VERSION ""

NS_ :

BS_:

BU_: GFM2_BCCMB ACCMB GFM3_DCACB FHCM SOBDMB_AWDC DCACA_GAS DCACA_HEV DCDC_LISB BCMC_CPDB DCMR_EAWD DCMR_ELSD BECMB_EPM PACM GFM_CPLR OBCC AFCM SOBDM_BCCM GWM _delete BCM ACCM GFM2_UIM ICM DCDC_HEV BECM SOBDMD_AHCM_PTC GENERIC TSTR

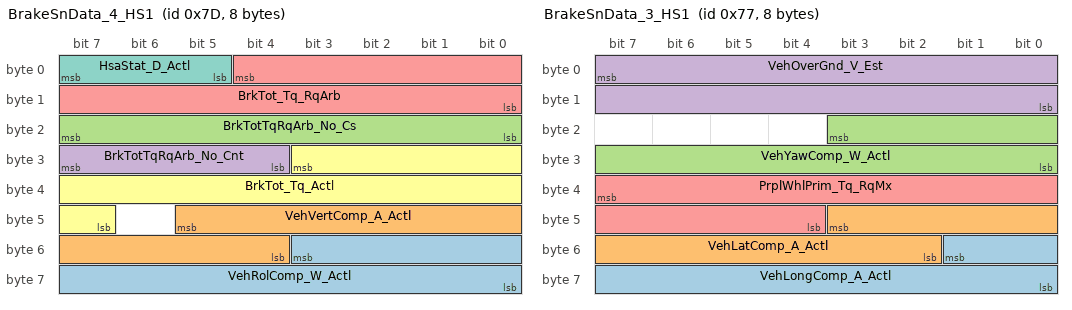
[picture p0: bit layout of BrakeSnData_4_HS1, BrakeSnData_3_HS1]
BO_ 125 BrakeSnData_4_HS1: 8 GWM
 SG_ VehRolComp_W_Actl : 51|12@0+ (0.03663,-75) [-75|74.92659] "degrees/sec"  GFM2_UIM
 SG_ VehVertComp_A_Actl : 45|10@0+ (0.035,-17.9) [-17.9|17.835] "m/s^2"  GFM2_UIM
 SG_ BrkTotTqRqArb_No_Cs : 23|8@0+ (1,0) [0|255] "Unitless"  BCMC_CPDB
 SG_ BrkTotTqRqArb_No_Cnt : 31|4@0+ (1,0) [0|15] "Unitless"  BCMC_CPDB
 SG_ BrkTot_Tq_RqArb : 4|13@0+ (4,0) [0|32756] "Nm"  BCMC_CPDB
 SG_ BrkTot_Tq_Actl : 27|13@0+ (4,0) [0|32756] "Nm"  GENERIC
 SG_ HsaStat_D_Actl : 7|3@0+ (1,0) [0|7] "SED"  GENERIC

BO_ 119 BrakeSnData_3_HS1: 8 GWM
 SG_ VehLongComp_A_Actl : 49|10@0+ (0.035,-17.9) [-17.9|17.835] "m/s^2"  AFCM,GFM2_UIM
 SG_ VehLatComp_A_Actl : 43|10@0+ (0.035,-17.9) [-17.9|17.835] "m/s^2"  AFCM,GFM2_UIM
 SG_ VehYawComp_W_Actl : 19|12@0+ (0.03663,-75) [-75|74.92659] "deg/s"  GFM2_UIM
 SG_ VehOverGnd_V_Est : 7|16@0+ (0.01,0) [0|655.33] "kph"  DCMR_ELSD
 SG_ PrplWhlPrim_Tq_RqMx : 39|12@0+ (8,0) [0|32760] "Nm"  GENERIC

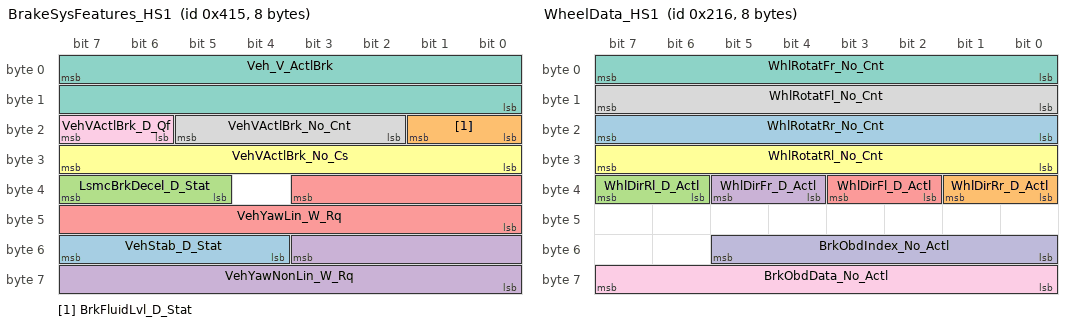
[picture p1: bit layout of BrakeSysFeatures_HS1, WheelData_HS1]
BO_ 1045 BrakeSysFeatures_HS1: 8 GWM
 SG_ VehStab_D_Stat : 55|4@0+ (1,0) [0|15] "SED" Vector__XXX
 SG_ BrkFluidLvl_D_Stat : 17|2@0+ (1,0) [0|3] "SED"  BCM
 SG_ LsmcBrkDecel_D_Stat : 39|3@0+ (1,0) [0|7] "SED"  GENERIC
 SG_ VehYawNonLin_W_Rq : 51|12@0+ (0.03663,-75) [-75|74.92659] "deg/s" Vector__XXX
 SG_ VehYawLin_W_Rq : 35|12@0+ (0.03663,-75) [-75|74.92659] "deg/s" Vector__XXX
 SG_ VehVActlBrk_No_Cs : 31|8@0+ (1,0) [0|255] "Unitless"  FHCM,SOBDMB_AWDC,DCMR_EAWD,BCM
 SG_ Veh_V_ActlBrk : 7|16@0+ (0.01,0) [0|655.35] "kph"  FHCM,SOBDMB_AWDC,DCMR_EAWD,BCM
 SG_ VehVActlBrk_No_Cnt : 21|4@0+ (1,0) [0|15] "Unitless"  FHCM,SOBDMB_AWDC,DCMR_EAWD,BCM
 SG_ VehVActlBrk_D_Qf : 23|2@0+ (1,0) [0|3] "SED"  FHCM,SOBDMB_AWDC,DCMR_EAWD,DCMR_ELSD,BCM

BO_ 534 WheelData_HS1: 8 GWM
 SG_ WhlRotatRr_No_Cnt : 23|8@0+ (1,0) [0|255] "Unitless"  BCM
 SG_ WhlDirRr_D_Actl : 33|2@0+ (1,0) [0|3] "SED" Vector__XXX
 SG_ WhlDirRl_D_Actl : 39|2@0+ (1,0) [0|3] "SED" Vector__XXX
 SG_ WhlDirFr_D_Actl : 37|2@0+ (1,0) [0|3] "SED" Vector__XXX
 SG_ WhlDirFl_D_Actl : 35|2@0+ (1,0) [0|3] "SED" Vector__XXX
 SG_ WhlRotatRl_No_Cnt : 31|8@0+ (1,0) [0|255] "Unitless"  BCM
 SG_ WhlRotatFr_No_Cnt : 7|8@0+ (1,0) [0|255] "Unitless"  BCM
 SG_ WhlRotatFl_No_Cnt : 15|8@0+ (1,0) [0|255] "Unitless"  BCM
 SG_ BrkObdData_No_Actl : 63|8@0+ (1,0) [0|255] "unitless" Vector__XXX
 SG_ BrkObdIndex_No_Actl : 53|6@0+ (1,0) [0|63] "unitless" Vector__XXX

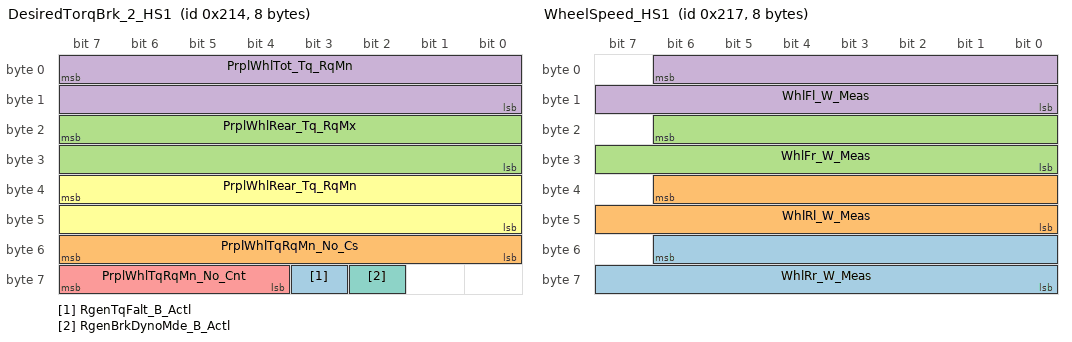
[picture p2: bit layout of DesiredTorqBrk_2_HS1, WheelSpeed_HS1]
BO_ 532 DesiredTorqBrk_2_HS1: 8 GWM
 SG_ RgenTqFalt_B_Actl : 59|1@0+ (1,0) [0|1] "SED" Vector__XXX
 SG_ PrplWhlTqRqMn_No_Cs : 55|8@0+ (1,0) [0|255] "Unitless" Vector__XXX
 SG_ PrplWhlRear_Tq_RqMx : 23|16@0+ (4,-131072) [-131072|131068] "Nm" Vector__XXX
 SG_ PrplWhlTot_Tq_RqMn : 7|16@0+ (4,-131072) [-131072|131068] "Nm" Vector__XXX
 SG_ PrplWhlTqRqMn_No_Cnt : 63|4@0+ (1,0) [0|15] "Unitless" Vector__XXX
 SG_ PrplWhlRear_Tq_RqMn : 39|16@0+ (4,-131072) [-131072|131068] "Nm" Vector__XXX
 SG_ RgenBrkDynoMde_B_Actl : 58|1@0+ (1,0) [0|1] "SED" Vector__XXX

BO_ 531 DesiredTorqBrk_HS1: 8 GWM
 SG_ VehStop_D_Stat : 28|2@0+ (1,0) [0|3] "SED"  GENERIC
 SG_ TracCtlPtActv_B_Actl : 31|1@0+ (1,0) [0|1] "SED"  GENERIC
 SG_ LscmbbMntr_B_Err : 17|1@0+ (1,0) [0|1] "SED"  GENERIC
 SG_ LscmbbBrkDis_B_Actl : 19|1@0+ (1,0) [0|1] "SED"  GENERIC
 SG_ StabCtlBrkActv_B_Actl : 23|1@0+ (1,0) [0|1] "SED"  GENERIC
 SG_ CmbbBrkPrchg_B_Actl : 59|1@0+ (1,0) [0|1] "SED"  GENERIC
 SG_ CmbbBrkDecel_B_Actl : 58|1@0+ (1,0) [0|1] "SED"  GENERIC
 SG_ CmbbBaSensInc_B_Actl : 57|1@0+ (1,0) [0|1] "SED"  GENERIC
 SG_ AccBrkWarm_B_Actl : 63|1@0+ (1,0) [0|1] "SED"  GENERIC
 SG_ AccBrkTotTqMn_B_Actl : 62|1@0+ (1,0) [0|1] "SED"  GENERIC
 SG_ AccBrkPrchgActv_B_Actl : 61|1@0+ (1,0) [0|1] "SED"  GENERIC
 SG_ AccBrkDis_B_Actl : 44|1@0+ (1,0) [0|1] "SED"  GENERIC
 SG_ AccBrkDeny_B_Actl : 42|1@0+ (1,0) [0|1] "SED"  GENERIC
 SG_ AccBrkActv_B_Actl : 43|1@0+ (1,0) [0|1] "SED"  GENERIC
 SG_ PrplDrgCtlActv_B_Actl : 46|1@0+ (1,0) [0|1] "SED"  GENERIC
 SG_ PrplWhlTot_Tq_RqMx : 7|16@0+ (4,-131072) [-131072|131068] "Nm"  GENERIC
 SG_ AbsActv_B_Actl : 45|1@0+ (1,0) [0|1] "SED"  GENERIC
 SG_ CmbbBrkDis_B_Actl : 56|1@0+ (1,0) [0|1] "SED"  GENERIC
 SG_ CmbbDeny_B_ActlBrk : 60|1@0+ (1,0) [0|1] "SED"  GENERIC
 SG_ CcDis_B_Cmd : 47|1@0+ (1,0) [0|1] "SED"  GENERIC
 SG_ VehLongOvrGnd_A_Est : 41|10@0+ (0.035,-17.9) [-17.9|17.835] "m/s^2"  AFCM,GENERIC
 SG_ AccStopActv_B_ActlBrk : 22|1@0+ (1,0) [0|1] "SED"  GENERIC
 SG_ AccDis_B_ActlEpb : 32|1@0+ (1,0) [0|1] "SED"  GENERIC
 SG_ PrkBrkYwLamp_D_Rq : 38|2@0+ (1,0) [0|3] "SED"  GENERIC
 SG_ PrkBrkRedLamp_D_Rq : 30|2@0+ (1,0) [0|3] "SED"  GENERIC
 SG_ PrkBrkMsgTxt_D_Rq : 36|4@0+ (1,0) [0|15] "SED"  GENERIC
 SG_ PrkBrkStatus : 26|3@0+ (1,0) [0|7] "SED"  DCACA_GAS,DCACA_HEV,GENERIC,BCM
 SG_ VehicleStationary : 39|1@0+ (1,0) [0|1] "SED"  GENERIC
 SG_ LscmbbDeny_B_ActlBrk : 18|1@0+ (1,0) [0|1] "SED"  GENERIC
 SG_ LscmbbBrkDecel_B_Actl : 20|1@0+ (1,0) [0|1] "SED"  GENERIC
 SG_ LscmbbBaSensInc_B_Actl : 21|1@0+ (1,0) [0|1] "SED"  GENERIC
 SG_ LscmbBrkPrchg_B_Actl : 16|1@0+ (1,0) [0|1] "SED"  GENERIC

BO_ 535 WheelSpeed_HS1: 8 GWM
 SG_ WhlRr_W_Meas : 54|15@0+ (0.01,0) [0|327.65] "rad/s"  SOBDMB_AWDC,DCMR_EAWD,DCMR_ELSD
 SG_ WhlRl_W_Meas : 38|15@0+ (0.01,0) [0|327.65] "rad/s"  SOBDMB_AWDC,DCMR_EAWD,DCMR_ELSD
 SG_ WhlFr_W_Meas : 22|15@0+ (0.01,0) [0|327.65] "rad/s"  SOBDMB_AWDC,DCMR_EAWD,DCMR_ELSD
 SG_ WhlFl_W_Meas : 6|15@0+ (0.01,0) [0|327.65] "rad/s"  SOBDMB_AWDC,DCMR_EAWD,DCMR_ELSD

BO_ 611 Driveline_Data_1_HS1: 8 GWM
 SG_ AwdTerrMdeChng_D_Rdy : 58|3@0+ (1,0) [0|7] "SED"  GENERIC
 SG_ AwdTerrMde_D_Actl : 50|3@0+ (1,0) [0|7] "SED"  GENERIC
 SG_ AwdSys_D_Stat : 27|2@0+ (1,0) [0|3] "SED"  GENERIC
 SG_ SelDrvMdeAwd_D_Stat : 33|2@0+ (1,0) [0|3] "SED"  GENERIC
 SG_ AwdStat_D_RqDsply : 63|5@0+ (1,0) [0|31] "SED"  GENERIC
 SG_ AwdLck_D_Stat : 31|4@0+ (1,0) [0|15] "SED"  GENERIC
 SG_ AwdSrvcRqd_B_Rq : 0|1@0+ (1,0) [0|1] "SED"  GENERIC
 SG_ AwdDrvMde_D_Stat : 38|3@0+ (1,0) [0|7] "SED"  GENERIC
 SG_ NtrlTowAvail_B_Stat : 4|1@0+ (1,0) [0|1] "SED"  GENERIC
 SG_ AwdLck_Tq_Rq : 15|12@0+ (1,0) [0|4093] "Nm"  DCMR_ELSD
 SG_ TrnAout_Tq_RqMx : 47|13@0+ (1,-1250) [-1250|6941] "Nm"  GENERIC
 SG_ AwdOffRoadMode_D_Stats : 25|2@0+ (1,0) [0|3] "SED"  GENERIC
 SG_ AwdLoLamp_D_RqDsply : 35|2@0+ (1,0) [0|3] "SED"  GENERIC
 SG_ AwdHiLamp_D_RqDsply : 19|2@0+ (1,0) [0|3] "SED"  GENERIC
 SG_ AwdAutoLamp_D_RqDsply : 17|2@0+ (1,0) [0|3] "SED"  GENERIC
 SG_ Awd2wdLamp_D_RqDsply : 2|2@0+ (1,0) [0|3] "SED"  GENERIC
 SG_ AwdRnge_D_Actl : 7|3@0+ (1,0) [0|7] "SED"  DCMR_ELSD

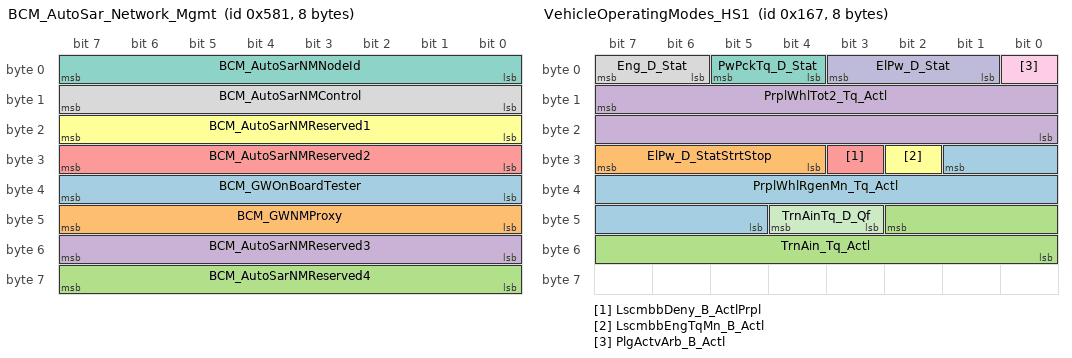
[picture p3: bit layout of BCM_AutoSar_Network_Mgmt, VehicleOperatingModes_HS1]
BO_ 1409 BCM_AutoSar_Network_Mgmt: 8 BCM
 SG_ BCM_GWOnBoardTester : 39|8@0+ (1,0) [0|255] "unitless"  BECMB_EPM,GWM
 SG_ BCM_GWNMProxy : 47|8@0+ (1,0) [0|255] "unitless"  BECMB_EPM,GWM
 SG_ BCM_AutoSarNMReserved4 : 63|8@0+ (1,0) [0|255] "unitless"  BECMB_EPM,GWM
 SG_ BCM_AutoSarNMReserved3 : 55|8@0+ (1,0) [0|255] "unitless"  BECMB_EPM,GWM
 SG_ BCM_AutoSarNMReserved2 : 31|8@0+ (1,0) [0|255] "unitless"  BECMB_EPM,GWM
 SG_ BCM_AutoSarNMReserved1 : 23|8@0+ (1,0) [0|255] "unitless"  BECMB_EPM,GWM
 SG_ BCM_AutoSarNMNodeId : 7|8@0+ (1,0) [0|255] "unitless"  BECMB_EPM,GWM
 SG_ BCM_AutoSarNMControl : 15|8@0+ (1,0) [0|255] "unitless"  BECMB_EPM,GWM

BO_ 90 Gear_Shift_by_Wire_HS1: 8 GWM
 SG_ TrnGsmNtmState_D_Actl : 55|2@0+ (1,0) [0|3] "SED"  GENERIC
 SG_ DrQltyDrv_D_StatGsm : 42|3@0+ (1,0) [0|7] "SED"  GENERIC
 SG_ TrnBtsiOvrrd_B_Stat : 43|1@0+ (1,0) [0|1] "SED"  GENERIC
 SG_ GsmGearMsgTxt_D_Rq : 63|2@0+ (1,0) [0|3] "SED"  GENERIC
 SG_ TrnRng_D_RqGsm : 51|4@0+ (1,0) [0|15] "SED"  GENERIC
 SG_ PrkBrkActv_D_RqGsmGear : 53|2@0+ (1,0) [0|3] "SED"  GENERIC
 SG_ TrnValidGearRq_D_Stat : 25|2@0+ (1,0) [0|3] "SED"  GENERIC
 SG_ TrnGearRqCnt_B_Actl : 26|1@0+ (1,0) [0|1] "unitless"  GENERIC
 SG_ TrnGearButtn_U_Actl : 23|8@0+ (0.05,0) [0|12.7] "VOLT"  GENERIC
 SG_ TrnGearButtn_B_ActlR2 : 8|1@0+ (1,0) [0|1] "SED"  GENERIC
 SG_ TrnGearButtn_B_ActlR1 : 9|1@0+ (1,0) [0|1] "SED"  GENERIC
 SG_ TrnGearButtn_B_ActlR0 : 10|1@0+ (1,0) [0|1] "SED"  GENERIC
 SG_ TrnGearButtn_B_ActlP2 : 11|1@0+ (1,0) [0|1] "SED"  GENERIC
 SG_ TrnGearButtn_B_ActlP1 : 12|1@0+ (1,0) [0|1] "SED"  GENERIC
 SG_ TrnGearButtn_B_ActlP0 : 13|1@0+ (1,0) [0|1] "SED"  GENERIC
 SG_ TrnGearButtn_B_ActlN2 : 14|1@0+ (1,0) [0|1] "SED"  GENERIC
 SG_ TrnGearButtn_B_ActlN1 : 15|1@0+ (1,0) [0|1] "SED"  GENERIC
 SG_ TrnGearButtn_B_ActlN0 : 0|1@0+ (1,0) [0|1] "SED"  GENERIC
 SG_ TrnGearButtn_B_ActlM2 : 1|1@0+ (1,0) [0|1] "SED"  GENERIC
 SG_ TrnGearButtn_B_ActlM1 : 2|1@0+ (1,0) [0|1] "SED"  GENERIC
 SG_ TrnGearButtn_B_ActlM0 : 3|1@0+ (1,0) [0|1] "SED"  GENERIC
 SG_ TrnGearButtn_B_ActlD2 : 4|1@0+ (1,0) [0|1] "SED"  GENERIC
 SG_ TrnGearButtn_B_ActlD1 : 5|1@0+ (1,0) [0|1] "SED"  GENERIC
 SG_ TrnGearButtn_B_ActlD0 : 6|1@0+ (1,0) [0|1] "SED"  GENERIC
 SG_ TrnGear_No_Cs : 39|8@0+ (1,0) [0|255] "Unitless"  GENERIC
 SG_ TrnGear_No_Cnt : 47|4@0+ (1,0) [0|15] "Unitless"  GENERIC
 SG_ TrnGear_D_RqDrv : 31|5@0+ (1,0) [0|31] "SED"  GENERIC,BCM
 SG_ BrkSwtchPos_B_ActlGsm : 7|1@0+ (1,0) [0|1] "SED"  GENERIC

BO_ 1109 eCall_Info_HS1: 8 GWM
 SG_ eCallConfirmation : 7|3@0+ (1,0) [0|7] "SED"  BCM

BO_ 92 Gear_Shift_by_Wire_3_HS1: 8 GWM
 SG_ TrnGearMsgTxt2_D_Rq : 53|5@0+ (1,0) [0|31] "SED"  GENERIC
 SG_ RaceTrakMde_D_Stat : 55|2@0+ (1,0) [0|3] "SED" Vector__XXX
 SG_ TrnLvrV_D_Rq : 43|2@0+ (1,0) [0|3] "SED" Vector__XXX
 SG_ TrnSbwSysHlth_D_Actl : 1|2@0+ (1,0) [0|3] "SED" Vector__XXX
 SG_ TrnGearNtmAllow_B_Stat : 47|1@0+ (1,0) [0|1] "SED" Vector__XXX
 SG_ TrnDtpCmd_D_Actl : 46|3@0+ (1,0) [0|7] "SED" Vector__XXX
 SG_ GearSelLck_D_Rq : 41|2@0+ (1,0) [0|3] "SED"  GENERIC
 SG_ TrnGearCmd_No_Cs : 31|8@0+ (1,0) [0|255] "Unitless" Vector__XXX
 SG_ TrnValidGear_D_Cnfm : 11|2@0+ (1,0) [0|3] "SED" Vector__XXX
 SG_ TrnNtrlTowCmd_D_Actl : 6|2@0+ (1,0) [0|3] "SED" Vector__XXX
 SG_ TrnGearCmd_Pc_ActlPt : 9|10@0+ (0.1,0) [0|102.2] "percent duty cycle" Vector__XXX
 SG_ TrnGear_D_RqPt : 4|3@0+ (1,0) [0|7] "SED"  SOBDMB_AWDC,DCMR_EAWD
 SG_ TrnCmdState_B_Actl : 39|1@0+ (1,0) [0|1] "SED" Vector__XXX
 SG_ TrnCmdCnt_B_Actl : 7|1@0+ (1,0) [0|1] "unitless" Vector__XXX
 SG_ PrkBrkActv_D_RqTrnGear : 38|2@0+ (1,0) [0|3] "SED" Vector__XXX
 SG_ TrnGearMsgTxt_D_Rq : 36|5@0+ (1,0) [0|31] "SED" Vector__XXX
 SG_ TrnGearCmd_No_Cnt : 15|4@0+ (1,0) [0|15] "Unitless" Vector__XXX

BO_ 359 VehicleOperatingModes_HS1: 8 GWM
 SG_ PrplWhlRgenMn_Tq_Actl : 25|13@0+ (4,-16380) [-16380|16380] "Nm"  GWM
 SG_ ElPw_D_StatStrtStop : 31|4@0+ (1,0) [0|15] "SED"  GWM
 SG_ TrnAin_Tq_Actl : 42|11@0+ (1,-500) [-500|1547] "Nm"  GWM
 SG_ PrplWhlTot2_Tq_Actl : 15|16@0+ (4,-131072) [-131072|131060] "Nm"  DCMR_ELSD,GWM
 SG_ LscmbbDeny_B_ActlPrpl : 27|1@0+ (1,0) [0|1] "SED"  GWM
 SG_ LscmbbEngTqMn_B_Actl : 26|1@0+ (1,0) [0|1] "SED"  GWM
 SG_ PwPckTq_D_Stat : 5|2@0+ (1,0) [0|3] "SED"  ACCMB,SOBDMB_AWDC,DCDC_LISB,GFM2_UIM,DCMR_EAWD,BCMC_CPDB,PACM,DCMR_ELSD,GFM_CPLR,SOBDM_BCCM,ACCM,SOBDMD_AHCM_PTC,DCDC_HEV,BCM,ICM,BECM,GWM
 SG_ Eng_D_Stat : 7|2@0+ (1,0) [0|3] "SED"  GFM2_UIM,BCM,GWM
 SG_ PlgActvArb_B_Actl : 0|1@0+ (1,0) [0|1] "SED"  BCM,GWM
 SG_ ElPw_D_Stat : 3|3@0+ (1,0) [0|7] "SED"  GFM2_UIM,BCMC_CPDB,DCMR_ELSD,SOBDMD_AHCM_PTC,BCM,GWM
 SG_ TrnAinTq_D_Qf : 44|2@0+ (1,0) [0|3] "SED"  GWM

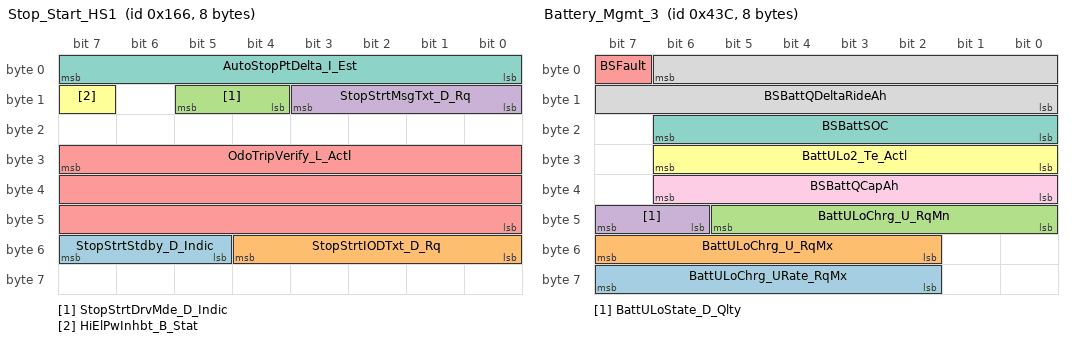
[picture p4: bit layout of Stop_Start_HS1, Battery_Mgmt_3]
BO_ 358 Stop_Start_HS1: 8 GWM
 SG_ StopStrtStdby_D_Indic : 55|3@0+ (1,0) [0|7] "SED"  GENERIC
 SG_ StopStrtIODTxt_D_Rq : 52|5@0+ (1,0) [0|31] "SED"  GENERIC
 SG_ StopStrtDrvMde_D_Indic : 13|2@0+ (1,0) [0|3] "SED"  BCM
 SG_ StopStrtMsgTxt_D_Rq : 11|4@0+ (1,0) [0|15] "SED"  GENERIC
 SG_ OdoTripVerify_L_Actl : 31|24@0+ (0.1,0) [0|1677721.4] "km"  GENERIC
 SG_ HiElPwInhbt_B_Stat : 15|1@0+ (1,0) [0|1] "SED"  GENERIC
 SG_ AutoStopPtDelta_I_Est : 7|8@0+ (1,-127) [-127|127] "Amps"  BCM

BO_ 1084 Battery_Mgmt_3: 8 BCM
 SG_ BattULoChrg_URate_RqMx : 63|6@0+ (0.1,0) [0|6.3] "volts/second"  GWM
 SG_ BattULoChrg_U_RqMx : 55|6@0+ (0.1,10.6) [10.6|16.9] "volt"  GWM
 SG_ BattULoChrg_U_RqMn : 45|6@0+ (0.1,10.6) [10.6|16.9] "volt"  GWM
 SG_ BattULoState_D_Qlty : 47|2@0+ (1,0) [0|3] "SED"  GWM
 SG_ BSFault : 7|1@0+ (1,0) [0|1] "SED"  GWM
 SG_ BattULo2_Te_Actl : 30|7@0+ (1,-40) [-40|86] "degC"  GFM2_UIM,GWM
 SG_ BSBattSOC : 22|7@0+ (1,0) [0|127] "%"  GFM2_UIM,GWM
 SG_ BSBattQDeltaRideAh : 6|15@0+ (0.0078125,-100) [-100|155.9921875] "ampere*hour"  GWM
 SG_ BSBattQCapAh : 38|7@0+ (1,0) [0|127] "ampere*hour"  GWM

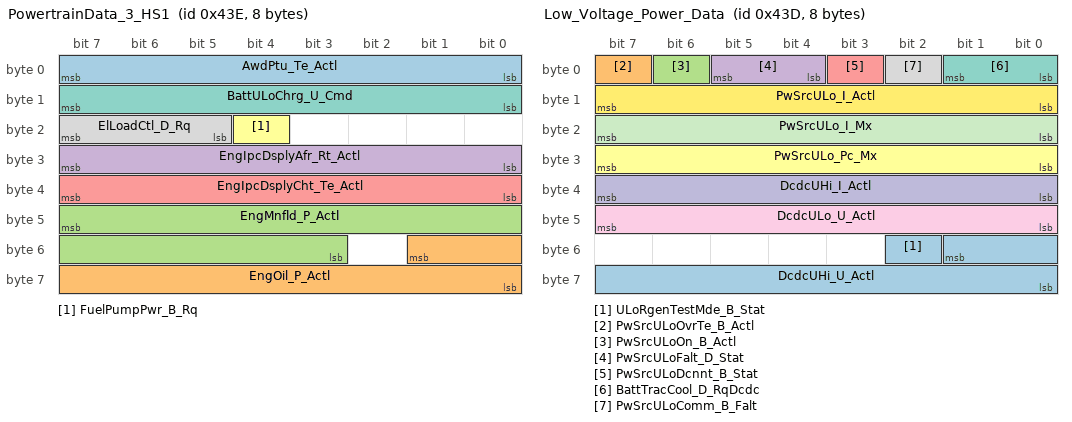
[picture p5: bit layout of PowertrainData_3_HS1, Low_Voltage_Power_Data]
BO_ 1086 PowertrainData_3_HS1: 8 GWM
 SG_ AwdPtu_Te_Actl : 7|8@0+ (1,-50) [-50|204] "degC"  GENERIC
 SG_ EngOil_P_Actl : 49|10@0+ (1,0) [0|1023] "kilopascal"  ICM
 SG_ EngMnfld_P_Actl : 47|13@0+ (0.1,-206.8) [-206.8|612.3] "kilopascal"  GENERIC,ICM
 SG_ EngIpcDsplyAfr_Rt_Actl : 31|8@0+ (0.1,0) [0|25.5] "unitless"  GENERIC
 SG_ EngIpcDsplyCht_Te_Actl : 39|8@0+ (1,-60) [-60|195] "degC"  GENERIC
 SG_ FuelPumpPwr_B_Rq : 20|1@0+ (1,0) [0|1] "SED"  BCM
 SG_ BattULoChrg_U_Cmd : 15|8@0+ (0.025,10.6) [10.6|16.975] "volt"  DCDC_LISB,BECM,BCM,DCDC_HEV
 SG_ ElLoadCtl_D_Rq : 23|3@0+ (1,0) [0|7] "SED"  BCM

BO_ 1085 Low_Voltage_Power_Data: 8 DCDC_HEV
 SG_ ULoRgenTestMde_B_Stat : 50|1@0+ (1,0) [0|1] "SED"  GWM,BCM
 SG_ PwSrcULoOvrTe_B_Actl : 7|1@0+ (1,0) [0|1] "SED"  GWM,BCM
 SG_ PwSrcULoOn_B_Actl : 6|1@0+ (1,0) [0|1] "SED"  GWM,SOBDM_BCCM
 SG_ PwSrcULoFalt_D_Stat : 5|2@0+ (1,0) [0|3] "SED"  GWM,BCM
 SG_ PwSrcULoDcnnt_B_Stat : 3|1@0+ (1,0) [0|1] "SED"  GWM,BCM
 SG_ PwSrcULo_Pc_Mx : 31|8@0+ (0.4,0) [0|101.6] "%"  GWM,SOBDMD_AHCM_PTC,BCM
 SG_ BattTracCool_D_RqDcdc : 1|2@0+ (1,0) [0|3] "SED"  GWM,BECM
 SG_ PwSrcULoComm_B_Falt : 2|1@0+ (1,0) [0|1] "SED"  GWM,BCM
 SG_ DcdcULo_U_Actl : 47|8@0+ (0.1,0) [0|25.4] "Volts"  GWM,BECM
 SG_ DcdcUHi_I_Actl : 39|8@0+ (0.1,0) [0|25.4] "Amps"  GWM,BCM,BECM
 SG_ PwSrcULo_I_Mx : 23|8@0+ (1,0) [0|254] "ampere"  GWM,BCM
 SG_ PwSrcULo_I_Actl : 15|8@0+ (1,0) [0|254] "ampere"  GWM,BCM
 SG_ DcdcUHi_U_Actl : 49|10@0+ (0.5,0) [0|510.5] "V"  GWM,BCM,BECM

BO_ 891 Chassis_Data: 8 GWM
 SG_ CabnSndAmb2_Db_Actl_UB : 10|1@0+ (1,0) [0|1] "SED"  BECM
 SG_ CabnSndAmb2_Db_Actl : 7|8@0+ (1,10) [10|264] "decibel"  BECM

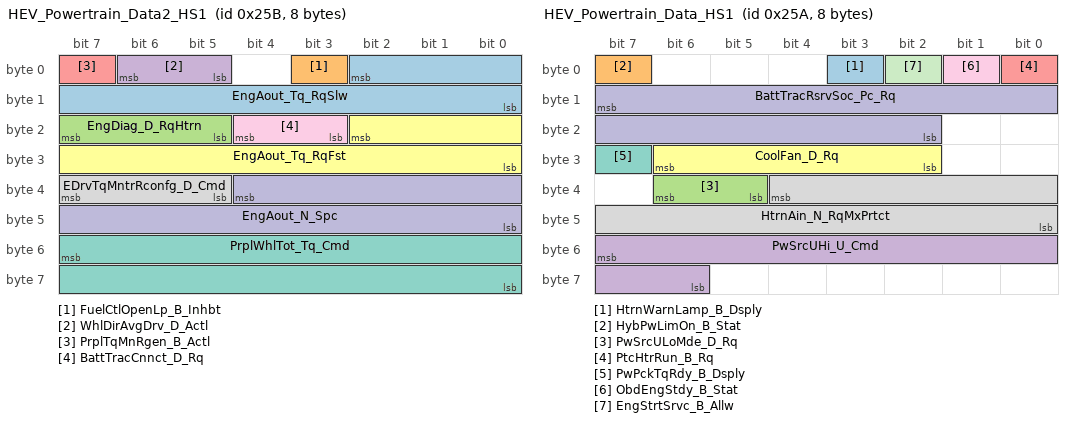
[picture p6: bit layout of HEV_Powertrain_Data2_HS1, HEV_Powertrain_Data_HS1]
BO_ 603 HEV_Powertrain_Data2_HS1: 8 GWM
 SG_ EngAout_Tq_RqSlw : 2|11@0+ (1,-500) [-500|1547] "Nm"  GWM,GENERIC
 SG_ FuelCtlOpenLp_B_Inhbt : 3|1@0+ (1,0) [0|1] "SED"  GWM,GENERIC
 SG_ EngDiag_D_RqHtrn : 23|3@0+ (1,0) [0|7] "SED"  GWM
 SG_ WhlDirAvgDrv_D_Actl : 6|2@0+ (1,0) [0|3] "SED"  GWM
 SG_ PrplTqMnRgen_B_Actl : 7|1@0+ (1,0) [0|1] "SED"  GWM
 SG_ EngAout_Tq_RqFst : 18|11@0+ (1,-500) [-500|1547] "Nm"  GWM,GENERIC
 SG_ PrplWhlTot_Tq_Cmd : 55|16@0+ (4,-131072) [-131072|131068] "Nm"  SOBDMB_AWDC,GWM,DCMR_EAWD,GENERIC
 SG_ EDrvTqMntrRconfg_D_Cmd : 39|3@0+ (1,0) [0|7] "SED"  GWM,GENERIC
 SG_ BattTracCnnct_D_Rq : 20|2@0+ (1,0) [0|3] "SED"  SOBDMB_AWDC,GWM,SOBDM_BCCM,DCMR_EAWD,BECM
 SG_ EngAout_N_Spc : 36|13@0+ (2,0) [0|16382] "rpm"  GWM,GENERIC

BO_ 602 HEV_Powertrain_Data_HS1: 8 GWM
 SG_ HtrnWarnLamp_B_Dsply : 3|1@0+ (1,0) [0|1] "SED"  GWM
 SG_ HybPwLimOn_B_Stat : 7|1@0+ (1,0) [0|1] "SED"  GWM,BECM,DCDC_HEV
 SG_ PwSrcULoMde_D_Rq : 38|2@0+ (1,0) [0|3] "SED"  GWM,DCDC_LISB,BECM,DCDC_HEV
 SG_ PwSrcUHi_U_Cmd : 55|10@0+ (0.5,0) [0|511.5] "volt"  GWM,DCDC_LISB,BECM,DCDC_HEV
 SG_ PtcHtrRun_B_Rq : 0|1@0+ (1,0) [0|1] "SED"  GWM,GENERIC
 SG_ CoolFan_D_Rq : 30|5@0+ (1,0) [0|31] "unitless"  GWM,GENERIC
 SG_ PwPckTqRdy_B_Dsply : 31|1@0+ (1,0) [0|1] "SED"  GWM
 SG_ HtrnAin_N_RqMxPrtct : 36|13@0+ (2,0) [0|16382] "RPM"  GWM,GENERIC
 SG_ ObdEngStdy_B_Stat : 1|1@0+ (1,0) [0|1] "SED"  GWM,GENERIC
 SG_ BattTracRsrvSoc_Pc_Rq : 15|14@0+ (0.01,0) [0|163.81] "percent"  GWM,BECM
 SG_ EngStrtSrvc_B_Allw : 2|1@0+ (1,0) [0|1] "SED"  GWM,GENERIC

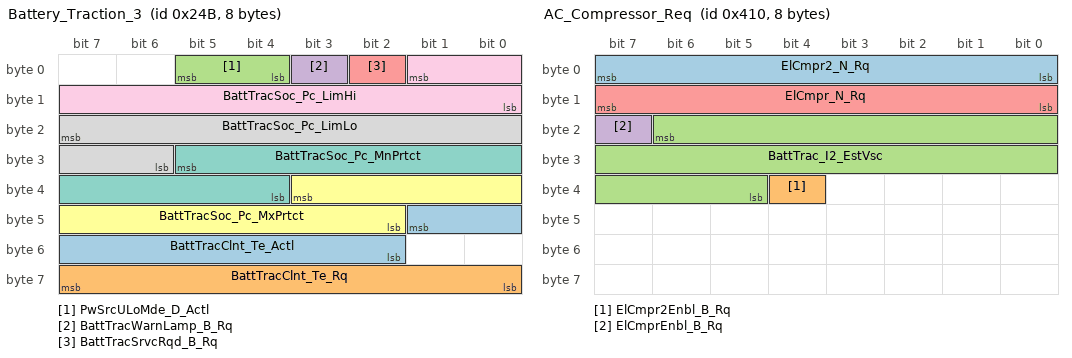
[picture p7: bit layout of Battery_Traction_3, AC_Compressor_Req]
BO_ 587 Battery_Traction_3: 8 BECM
 SG_ BattTracClnt_Te_Actl : 41|8@0+ (0.5,-60) [-60|66.5] "degC"  GWM
 SG_ BattTracClnt_Te_Rq : 63|8@0+ (0.5,-60) [-60|67.5] "degC"  GWM
 SG_ PwSrcULoMde_D_Actl : 5|2@0+ (1,0) [0|3] "SED"  GWM
 SG_ BattTracWarnLamp_B_Rq : 3|1@0+ (1,0) [0|1] "SED"  GWM
 SG_ BattTracSrvcRqd_B_Rq : 2|1@0+ (1,0) [0|1] "SED"  GWM
 SG_ BattTracSoc_Pc_MxPrtct : 35|10@0+ (0.1,0) [0|100] "%"  GWM
 SG_ BattTracSoc_Pc_MnPrtct : 29|10@0+ (0.1,0) [0|100] "%"  GWM
 SG_ BattTracSoc_Pc_LimLo : 23|10@0+ (0.1,0) [0|100] "%"  GWM
 SG_ BattTracSoc_Pc_LimHi : 1|10@0+ (0.1,0) [0|100] "%"  GWM

BO_ 1040 AC_Compressor_Req: 8 GWM
 SG_ ElCmpr2_N_Rq : 7|8@0+ (50,0) [0|12750] "RPM"  ACCMB
 SG_ ElCmpr2Enbl_B_Rq : 36|1@0+ (1,0) [0|1] "SED"  ACCMB
 SG_ BattTrac_I2_EstVsc : 22|18@0+ (0.05,-6553.52) [-6553.52|6553.53] "ampere"  BECM
 SG_ ElCmprEnbl_B_Rq : 23|1@0+ (1,0) [0|1] "SED"  ACCM
 SG_ ElCmpr_N_Rq : 15|8@0+ (50,0) [0|12750] "RPM"  ACCM

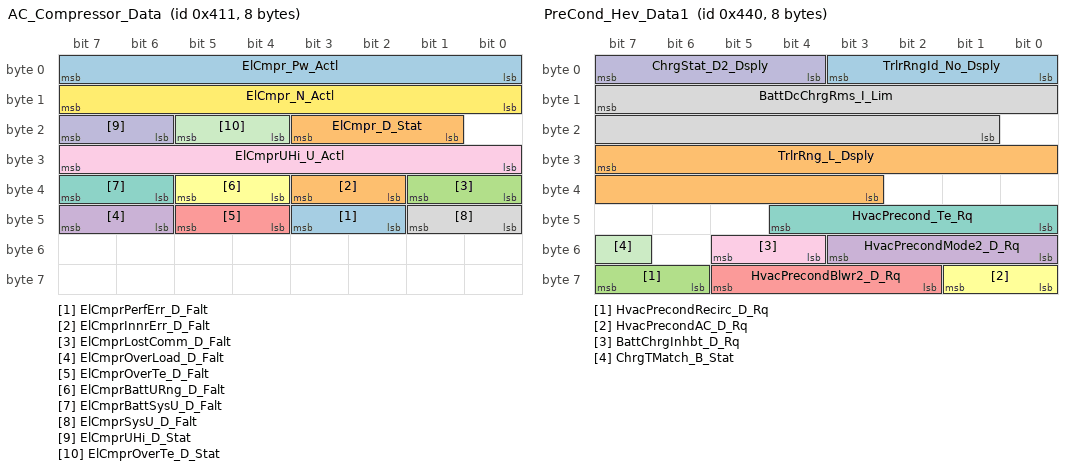
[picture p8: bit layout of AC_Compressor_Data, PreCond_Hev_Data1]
BO_ 1041 AC_Compressor_Data: 8 ACCM
 SG_ ElCmprPerfErr_D_Falt : 43|2@0+ (1,0) [0|3] "SED"  GWM
 SG_ ElCmprInnrErr_D_Falt : 35|2@0+ (1,0) [0|3] "SED"  GWM
 SG_ ElCmprLostComm_D_Falt : 33|2@0+ (1,0) [0|3] "SED"  GWM
 SG_ ElCmprOverLoad_D_Falt : 47|2@0+ (1,0) [0|3] "SED"  GWM
 SG_ ElCmprOverTe_D_Falt : 45|2@0+ (1,0) [0|3] "SED"  GWM
 SG_ ElCmprBattURng_D_Falt : 37|2@0+ (1,0) [0|3] "SED"  GWM
 SG_ ElCmprBattSysU_D_Falt : 39|2@0+ (1,0) [0|3] "SED"  GWM
 SG_ ElCmprSysU_D_Falt : 41|2@0+ (1,0) [0|3] "SED"  GWM
 SG_ ElCmprUHi_U_Actl : 31|8@0+ (2,0) [0|510] "volt"  GWM
 SG_ ElCmprUHi_D_Stat : 23|2@0+ (1,0) [0|3] "SED"  GWM
 SG_ ElCmprOverTe_D_Stat : 21|2@0+ (1,0) [0|3] "SED"  GWM
 SG_ ElCmpr_N_Actl : 15|8@0+ (50,0) [0|12700] "RPM"  GWM
 SG_ ElCmpr_Pw_Actl : 7|8@0+ (40,0) [0|10160] "watts"  GWM
 SG_ ElCmpr_D_Stat : 19|3@0+ (1,0) [0|7] "SED"  GWM

BO_ 1999 TesterPhysicalResACCM: 8 ACCM
 SG_ TesterPhysicalResACCM : 7|64@0+ (1,0) [0|1.84467E+019] "unitless"  TSTR

BO_ 1991 TesterPhysicalReqACCM: 8 TSTR
 SG_ TesterPhysicalReqACCM : 7|64@0+ (1,0) [0|1.84467E+019] "unitless"  ACCM

BO_ 2022 TesterPhysicalReqSOBDMC: 8 TSTR
 SG_ TesterPhysicalReqSOBDMC : 7|64@0+ (1,0) [0|1.84467E+019] "unitless" Vector__XXX

BO_ 1088 PreCond_Hev_Data1: 8 GWM
 SG_ TrlrRngId_No_Dsply : 3|4@0+ (1,0) [0|15] "unitless"  GENERIC
 SG_ TrlrRng_L_Dsply : 31|13@0+ (0.1,0) [0|818.9] "kilometer"  GENERIC
 SG_ HvacPrecondRecirc_D_Rq : 63|2@0+ (1,0) [0|3] "SED" Vector__XXX
 SG_ HvacPrecondMode2_D_Rq : 51|4@0+ (1,0) [0|15] "SED" Vector__XXX
 SG_ HvacPrecondBlwr2_D_Rq : 61|4@0+ (1,0) [0|15] "SED" Vector__XXX
 SG_ HvacPrecondAC_D_Rq : 57|2@0+ (1,0) [0|3] "SED" Vector__XXX
 SG_ HvacPrecond_Te_Rq : 44|5@0+ (0.5,14.5) [14.5|30] "deg C" Vector__XXX
 SG_ BattDcChrgRms_I_Lim : 15|15@0+ (0.05,0) [0|1638.25] "ampere"  BECM
 SG_ BattChrgInhbt_D_Rq : 53|2@0+ (1,0) [0|3] "SED"  SOBDM_BCCM,BECM
 SG_ ChrgStat_D2_Dsply : 7|4@0+ (1,0) [0|15] "SED" Vector__XXX
 SG_ ChrgTMatch_B_Stat : 55|1@0+ (1,0) [0|1] "SED" Vector__XXX

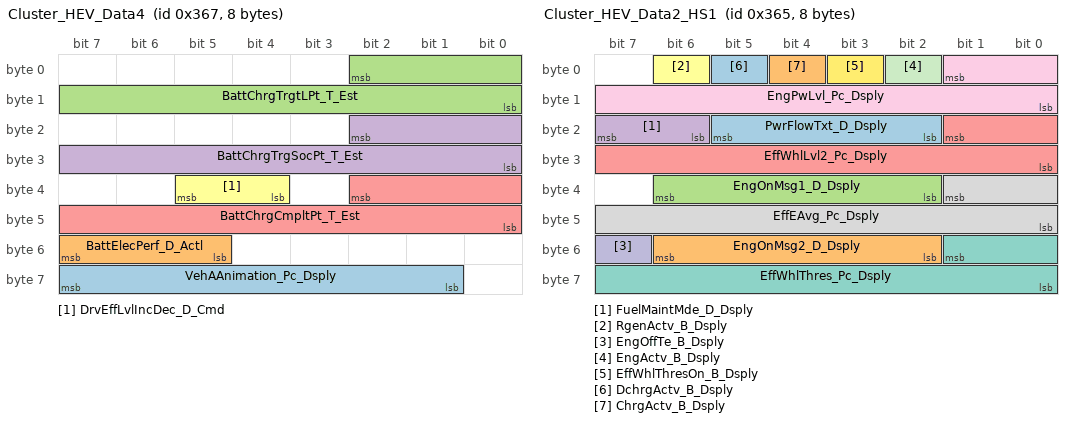
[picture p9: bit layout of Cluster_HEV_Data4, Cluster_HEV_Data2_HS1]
BO_ 871 Cluster_HEV_Data4: 8 GWM
 SG_ VehAAnimation_Pc_Dsply : 63|7@0+ (1,0) [0|127] "percent"  GENERIC
 SG_ BattElecPerf_D_Actl : 55|3@0+ (1,0) [0|7] "SED"  GENERIC
 SG_ BattChrgTrgtLPt_T_Est : 2|11@0+ (1,0) [0|2045] "minute"  GENERIC
 SG_ BattChrgTrgSocPt_T_Est : 18|11@0+ (1,0) [0|2045] "minute"  GENERIC
 SG_ BattChrgCmpltPt_T_Est : 34|11@0+ (1,0) [0|2045] "minute"  OBCC
 SG_ DrvEffLvlIncDec_D_Cmd : 37|2@0+ (1,0) [0|3] "SED"  GENERIC

BO_ 869 Cluster_HEV_Data2_HS1: 8 GWM
 SG_ PwrFlowTxt_D_Dsply : 21|4@0+ (1,0) [0|15] "SED"  GENERIC
 SG_ EngOnMsg2_D_Dsply : 54|5@0+ (1,0) [0|31] "SED"  GENERIC
 SG_ EngOnMsg1_D_Dsply : 38|5@0+ (1,0) [0|31] "SED"  GENERIC
 SG_ FuelMaintMde_D_Dsply : 23|2@0+ (1,0) [0|3] "SED"  GENERIC
 SG_ EffWhlLvl2_Pc_Dsply : 17|10@0+ (0.2,-102.2) [-102.2|102.4] "percent"  GENERIC
 SG_ RgenActv_B_Dsply : 6|1@0+ (1,0) [0|1] "SED"  GFM2_UIM
 SG_ EffWhlThres_Pc_Dsply : 49|10@0+ (0.1,0) [0|102.3] "percent"  GENERIC
 SG_ EffEAvg_Pc_Dsply : 33|10@0+ (0.1,0) [0|102.3] "percent"  GENERIC
 SG_ EngPwLvl_Pc_Dsply : 1|10@0+ (0.1,0) [0|102.3] "percent"  GENERIC
 SG_ EngOffTe_B_Dsply : 55|1@0+ (1,0) [0|1] "SED"  GENERIC
 SG_ EngActv_B_Dsply : 2|1@0+ (1,0) [0|1] "SED"  GENERIC
 SG_ EffWhlThresOn_B_Dsply : 3|1@0+ (1,0) [0|1] "SED"  GENERIC
 SG_ DchrgActv_B_Dsply : 5|1@0+ (1,0) [0|1] "SED"  GENERIC
 SG_ ChrgActv_B_Dsply : 4|1@0+ (1,0) [0|1] "SED"  GENERIC

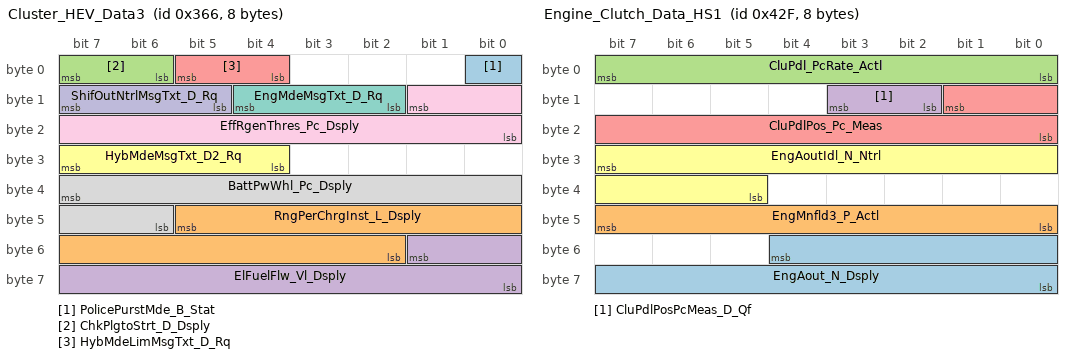
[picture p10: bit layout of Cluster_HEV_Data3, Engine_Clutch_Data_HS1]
BO_ 870 Cluster_HEV_Data3: 8 GWM
 SG_ PolicePurstMde_B_Stat : 0|1@0+ (1,0) [0|1] "SED"  GENERIC
 SG_ RngPerChrgInst_L_Dsply : 45|12@0+ (0.1,0) [0|409.3] "km"  GENERIC
 SG_ ChkPlgtoStrt_D_Dsply : 7|2@0+ (1,0) [0|3] "SED"  GENERIC
 SG_ ElFuelFlw_Vl_Dsply : 49|10@0+ (25,0) [0|25575] "micro-litre"  GFM2_UIM
 SG_ HybMdeLimMsgTxt_D_Rq : 5|2@0+ (1,0) [0|3] "SED"  GENERIC
 SG_ HybMdeMsgTxt_D2_Rq : 31|4@0+ (1,0) [0|15] "SED"  GENERIC
 SG_ EngMdeMsgTxt_D_Rq : 12|3@0+ (1,0) [0|7] "SED"  GENERIC
 SG_ BattPwWhl_Pc_Dsply : 39|10@0+ (0.1,0) [0|102.3] "percent"  GENERIC
 SG_ EffRgenThres_Pc_Dsply : 9|10@0+ (0.1,-102.3) [-102.3|0] "percent"  GENERIC
 SG_ ShifOutNtrlMsgTxt_D_Rq : 15|3@0+ (1,0) [0|7] "SED"  GENERIC

BO_ 1071 Engine_Clutch_Data_HS1: 8 GWM
 SG_ EngAout_N_Dsply : 52|13@0+ (2,0) [0|16382] "rpm" Vector__XXX
 SG_ EngMnfld3_P_Actl : 47|8@0+ (10,0) [0|2530] "milibar"  AFCM
 SG_ CluPdl_PcRate_Actl : 7|8@0+ (0.04,-5) [-5|5.2] "%/ms" Vector__XXX
 SG_ CluPdlPosPcMeas_D_Qf : 11|2@0+ (1,0) [0|3] "SED" Vector__XXX
 SG_ CluPdlPos_Pc_Meas : 9|10@0+ (0.1,0) [0|102.3] "%"  GFM2_UIM
 SG_ EngAoutIdl_N_Ntrl : 31|11@0+ (2,0) [0|4094] "rpm" Vector__XXX

BO_ 130 EPAS_INFO_HS1: 8 GWM
 SG_ TrlrHitchLamp_D_Rqst : 24|1@0+ (1,0) [0|1] "SED"  BCM
 SG_ SteEffort_D_Stat : 52|3@0+ (1,0) [0|7] "SED"  GENERIC
 SG_ SteMdule_D_Stat : 55|3@0+ (1,0) [0|7] "SED"  GENERIC
 SG_ Veh_V_RqMxTrlrAid : 63|8@0+ (0.1,0) [0|25.5] "km/h"  GENERIC
 SG_ DrvSteActv_B_Stat : 10|1@0+ (1,0) [0|1] "SED"  GENERIC
 SG_ DrvSte_Tq_Actl : 47|8@0+ (0.0625,-8) [-8|7.8125] "Nm"  GENERIC
 SG_ VehVTrlrAid_B_Rq : 25|1@0+ (1,0) [0|1] "SED"  GENERIC
 SG_ SteMdule_U_Meas : 39|8@0+ (0.05,6) [6|18.7] "Volts"  GENERIC,BCM
 SG_ SteMdule_I_Est : 21|12@0+ (0.05,-64) [-64|140.7] "Amps"  BCM
 SG_ EPAS_Failure : 9|2@0+ (1,0) [0|3] "SED"  GENERIC
 SG_ SteeringColumnTorque : 7|8@0+ (0.0625,-8) [-8|7.8125] "Nm"  GENERIC
 SG_ SAPPAngleControlStat6 : 15|1@0+ (1,0) [0|1] "SED"  GENERIC
 SG_ SAPPAngleControlStat5 : 14|1@0+ (1,0) [0|1] "SED"  GENERIC
 SG_ SAPPAngleControlStat4 : 13|1@0+ (1,0) [0|1] "SED"  GENERIC
 SG_ SAPPAngleControlStat3 : 12|1@0+ (1,0) [0|1] "SED"  GENERIC
 SG_ SAPPAngleControlStat2 : 11|1@0+ (1,0) [0|1] "SED"  GENERIC
 SG_ SAPPAngleControlStat1 : 23|2@0+ (1,0) [0|3] "SED"  GENERIC

BO_ 1076 Cluster_Info3_HS1: 8 GWM
 SG_ CenterStackRing_D_Actl : 60|2@0+ (1,0) [0|3] "SED"  GFM_CPLR
 SG_ CenterStackRing_D_Actl_UB : 58|1@0+ (1,0) [0|1] "SED"  GFM_CPLR
 SG_ EngIdlShutDown_B_RqDrv_UB : 61|1@0+ (1,0) [0|1] "SED"  GENERIC
 SG_ EngIdlShutDown_B_RqDrv : 62|1@0+ (1,0) [0|1] "SED" Vector__XXX
 SG_ OdoTripRx_B_Actl : 63|1@0+ (1,0) [0|1] "SED" Vector__XXX
 SG_ LscmbbEngTqMn_B_Rq_UB : 38|1@0+ (1,0) [0|1] "SED" Vector__XXX
 SG_ LscmbbEngTqMn_B_Rq : 39|1@0+ (1,0) [0|1] "SED" Vector__XXX
 SG_ TirePReset_B_Rq_UB : 18|1@0+ (1,0) [0|1] "SED"  BCM
 SG_ DrTGate_D_Rq : 51|2@0+ (1,0) [0|3] "SED"  BCM
 SG_ DrTGate_D_Rq_UB : 36|1@0+ (1,0) [0|1] "SED"  BCM
 SG_ Veh_V_CompLimMx : 35|12@0+ (0.1,0) [0|409.5] "km/h" Vector__XXX
 SG_ FuelLvlPssvSide_No_Raw : 17|10@0+ (1,0) [0|1023] "Unitless" Vector__XXX
 SG_ FUEL_SENSOR_NUM : 2|1@0+ (1,0) [0|1] "SED" Vector__XXX
 SG_ FuelLvlActvSide_No_Raw : 1|10@0+ (1,0) [0|1023] "Unitless" Vector__XXX
 SG_ DISPLAY_SPEED_SCALING : 23|4@0+ (0.5,100) [100|107.5] "%" Vector__XXX
 SG_ DISPLAY_SPEED_OFFSET : 6|3@0+ (0.5,0) [0|3.5] "kph" Vector__XXX
 SG_ TirePReset_B_Rq : 19|1@0+ (1,0) [0|1] "SED"  BCM

BO_ 1072 Cluster_Info1_HS1: 8 GWM
 SG_ ePRNDL_MODE_UB : 63|1@0+ (1,0) [0|1] "SED"  BCM
 SG_ NtrlTowMdeEnbl_B_RqDrv : 6|1@0+ (1,0) [0|1] "SED" Vector__XXX
 SG_ NtrlTowMdeEnbl_B_RqDrv_UB : 48|1@0+ (1,0) [0|1] "SED"  GENERIC
 SG_ Remote_Start_QuietMode_UB : 50|1@0+ (1,0) [0|1] "SED"  BCM
 SG_ Remote_Start_QuietMode : 51|1@0+ (1,0) [0|1] "SED"  BCM
 SG_ ParkDetect_Stat_UB : 52|1@0+ (1,0) [0|1] "SED"  BCM
 SG_ ParkDetect_Stat : 53|1@0+ (1,0) [0|1] "SED"  BCM
 SG_ TrlrLampCnnct_B_Actl_UB : 42|1@0+ (1,0) [0|1] "SED"  GFM2_UIM,BCM
 SG_ StopLamp_B_RqTrlrBrk_UB : 46|1@0+ (1,0) [0|1] "SED"  BCM
 SG_ StopLamp_B_RqTrlrBrk : 47|1@0+ (1,0) [0|1] "SED"  BCM
 SG_ OdometerMasterValue_UB : 1|1@0+ (1,0) [0|1] "SED"  DCDC_LISB,SOBDM_BCCM,OBCC,GFM2_UIM,BECM,DCDC_HEV,ACCM,BCM
 SG_ OdometerMasterValue : 15|24@0+ (1,0) [0|16777214] "km"  ACCMB,DCDC_LISB,SOBDM_BCCM,OBCC,GFM2_UIM,DCDC_HEV,BECM,ACCM,BCM
 SG_ FrostWarn_D_Stat : 5|2@0+ (1,0) [0|3] "SED"  GFM2_UIM
 SG_ ReducedGuard_D_Rq_UB : 49|1@0+ (1,0) [0|1] "SED"  BCM
 SG_ ReducedGuard_D_Rq : 41|2@0+ (1,0) [0|3] "SED"  BCM
 SG_ ePRNDL_MODE : 0|1@0+ (1,0) [0|1] "SED"  BCM
 SG_ EngOilLife_B_RqReset : 43|1@0+ (1,0) [0|1] "SED"  GFM2_UIM
 SG_ Outside_Air_Temp_Stat_UB : 2|1@0+ (1,0) [0|1] "SED"  DCMR_ELSD
 SG_ Outside_Air_Temp_Stat : 39|8@0+ (0.5,-40) [-40|86.5] "Degrees C"  DCMR_ELSD
 SG_ KeyTypeChngMykey_D_Rq_UB : 60|1@0+ (1,0) [0|1] "SED"  BCM
 SG_ KeyTypeChngMykey_D_Rq : 62|2@0+ (1,0) [0|3] "SED"  BCM
 SG_ TrlrLampCnnct_B_Actl : 3|1@0+ (1,0) [0|1] "SED"  GFM2_UIM,BCM

BO_ 2002 TesterPhysicalReqGFM2: 8 TSTR
 SG_ TesterPhysicalReqGFM2 : 7|64@0+ (1,0) [0|1.84467E+019] "unitless"  GFM2_BCCMB,GFM2_UIM

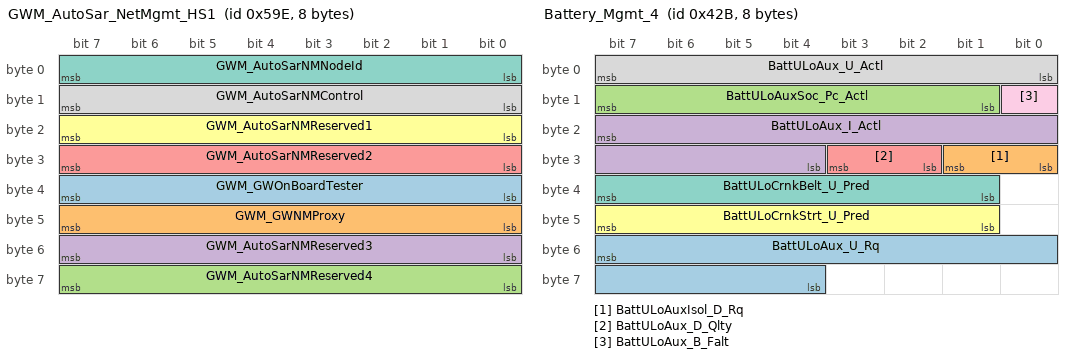
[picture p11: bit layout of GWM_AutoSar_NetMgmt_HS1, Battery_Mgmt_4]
BO_ 1438 GWM_AutoSar_NetMgmt_HS1: 8 GWM
 SG_ GWM_GWOnBoardTester : 39|8@0+ (1,0) [0|255] "unitless"  BCMC_CPDB,BECM,DCDC_HEV,DCDC_LISB,GFM2_UIM,ICM,SOBDM_BCCM,BECMB_EPM,BCM
 SG_ GWM_GWNMProxy : 47|8@0+ (1,0) [0|255] "unitless"  BCMC_CPDB,BECM,DCDC_HEV,DCDC_LISB,GFM2_UIM,ICM,SOBDM_BCCM,BECMB_EPM,BCM
 SG_ GWM_AutoSarNMReserved4 : 63|8@0+ (1,0) [0|255] "unitless"  BCMC_CPDB,BECM,DCDC_HEV,DCDC_LISB,GFM2_UIM,ICM,SOBDM_BCCM,BECMB_EPM,BCM
 SG_ GWM_AutoSarNMReserved3 : 55|8@0+ (1,0) [0|255] "unitless"  BCMC_CPDB,BECM,DCDC_HEV,DCDC_LISB,GFM2_UIM,ICM,SOBDM_BCCM,BECMB_EPM,BCM
 SG_ GWM_AutoSarNMReserved2 : 31|8@0+ (1,0) [0|255] "unitless"  BCMC_CPDB,BECM,DCDC_HEV,DCDC_LISB,GFM2_UIM,ICM,SOBDM_BCCM,BECMB_EPM,BCM
 SG_ GWM_AutoSarNMReserved1 : 23|8@0+ (1,0) [0|255] "unitless"  BCMC_CPDB,BECM,DCDC_HEV,DCDC_LISB,GFM2_UIM,ICM,SOBDM_BCCM,BECMB_EPM,BCM
 SG_ GWM_AutoSarNMNodeId : 7|8@0+ (1,0) [0|255] "unitless"  BCMC_CPDB,BECM,DCDC_HEV,DCDC_LISB,GFM2_UIM,ICM,SOBDM_BCCM,BECMB_EPM,BCM
 SG_ GWM_AutoSarNMControl : 15|8@0+ (1,0) [0|255] "unitless"  BCMC_CPDB,BECM,DCDC_HEV,DCDC_LISB,GFM2_UIM,ICM,SOBDM_BCCM,BECMB_EPM,BCM

BO_ 1067 Battery_Mgmt_4: 8 BCM
 SG_ BattULoAux_U_Rq : 55|12@0+ (0.00390625,0) [0|15.9921875] "volt"  GWM
 SG_ BattULoAuxIsol_D_Rq : 25|2@0+ (1,0) [0|3] "SED"  GWM
 SG_ BattULoAuxSoc_Pc_Actl : 15|7@0+ (1,0) [0|127] "percent"  GWM
 SG_ BattULoAux_I_Actl : 23|12@0+ (0.0625,-128) [-128|127.875] "ampere"  GWM
 SG_ BattULoAux_D_Qlty : 27|2@0+ (1,0) [0|3] "SED"  GWM
 SG_ BattULoCrnkStrt_U_Pred : 47|7@0+ (0.1,0) [0|12.7] "volt"  GWM
 SG_ BattULoCrnkBelt_U_Pred : 39|7@0+ (0.1,0) [0|12.7] "volt"  GWM
 SG_ BattULoAux_U_Actl : 7|8@0+ (0.0625,0) [0|15.875] "volt"  GWM
 SG_ BattULoAux_B_Falt : 8|1@0+ (1,0) [0|1] "SED"  GWM

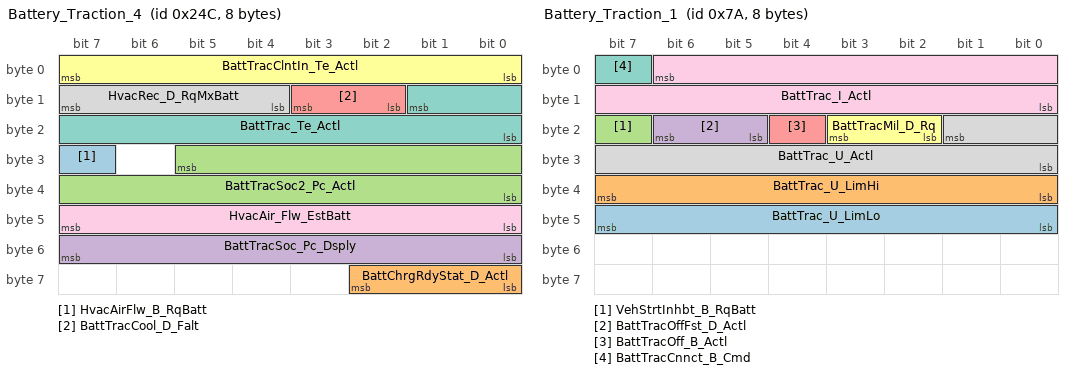
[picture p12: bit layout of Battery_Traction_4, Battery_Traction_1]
BO_ 588 Battery_Traction_4: 8 BECM
 SG_ HvacAirFlw_B_RqBatt : 31|1@0+ (1,0) [0|1] "SED"  GWM
 SG_ BattChrgRdyStat_D_Actl : 58|3@0+ (1,0) [0|7] "SED"  GWM,OBCC,GFM_CPLR,SOBDM_BCCM
 SG_ BattTracSoc2_Pc_Actl : 29|14@0+ (0.01,0) [0|163.81] "%"  GWM
 SG_ BattTracSoc_Pc_Dsply : 55|8@0+ (0.5,0) [0|126.5] "Percent"  OBCC,GFM_CPLR,SOBDM_BCCM,GWM
 SG_ BattTracCool_D_Falt : 11|2@0+ (1,0) [0|3] "SED"  DCDC_LISB,GWM,DCDC_HEV
 SG_ BattTracClntIn_Te_Actl : 7|8@0+ (1,-50) [-50|204] "degC"  DCDC_LISB,GWM,SOBDM_BCCM,DCDC_HEV
 SG_ BattTrac_Te_Actl : 9|10@0+ (0.5,-50) [-50|460.5] "degC"  GWM
 SG_ HvacRec_D_RqMxBatt : 15|4@0+ (1,0) [0|15] "SED"  GWM
 SG_ HvacAir_Flw_EstBatt : 47|8@0+ (0.5,0) [0|127] "liter/second"  DCDC_LISB,DCDC_HEV,GWM

BO_ 122 Battery_Traction_1: 8 BECM
 SG_ BattTrac_U_LimLo : 47|8@0+ (2,0) [0|510] "volt"  SOBDMB_AWDC,DCMR_EAWD,GWM
 SG_ BattTrac_U_LimHi : 39|8@0+ (2,0) [0|510] "volt"  SOBDMB_AWDC,DCMR_EAWD,GWM
 SG_ VehStrtInhbt_B_RqBatt : 23|1@0+ (1,0) [0|1] "SED"  GWM
 SG_ BattTracOffFst_D_Actl : 22|2@0+ (1,0) [0|3] "SED"  ACCMB,SOBDMB_AWDC,SOBDM_BCCM,ACCM,DCMR_EAWD,GWM
 SG_ BattTracOff_B_Actl : 20|1@0+ (1,0) [0|1] "SED"  SOBDMB_AWDC,DCMR_EAWD,GWM,SOBDM_BCCM
 SG_ BattTracMil_D_Rq : 19|2@0+ (1,0) [0|3] "SED"  GWM
 SG_ BattTracCnnct_B_Cmd : 7|1@0+ (1,0) [0|1] "SED"  DCDC_LISB,DCMR_EAWD,GWM,DCDC_HEV
 SG_ BattTrac_U_Actl : 17|10@0+ (0.5,0) [0|510.5] "Volts"  DCDC_LISB,DCMR_EAWD,OBCC,GWM,SOBDM_BCCM,DCDC_HEV
 SG_ BattTrac_I_Actl : 6|15@0+ (0.05,-750) [-750|888.25] "Amps"  DCDC_LISB,OBCC,SOBDM_BCCM,GWM

BO_ 1814 TesterPhysicalReqGWM_H1: 8 TSTR
 SG_ TesterPhysicalReqGWM_H1 : 7|64@0+ (1,0) [0|1.84467E+019] "unitless"  GWM

BO_ 1822 TesterPhysicalResGWM_HS1: 8 GWM
 SG_ TesterPhysicalResGWM_H1 : 7|64@0+ (1,0) [0|1.84467E+019] "unitless"  TSTR

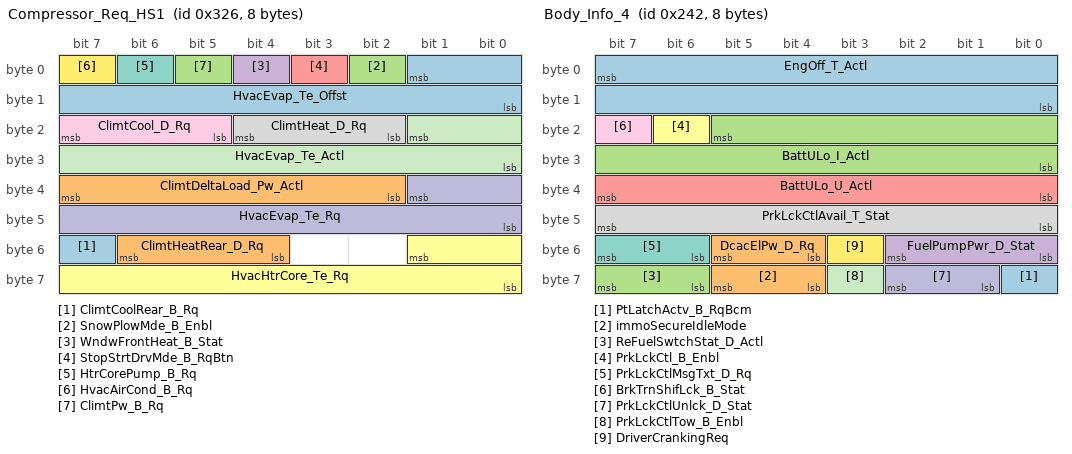
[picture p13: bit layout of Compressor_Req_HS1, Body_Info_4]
BO_ 806 Compressor_Req_HS1: 8 GWM
 SG_ ClimtCoolRear_B_Rq : 55|1@0+ (1,0) [0|1] "SED" Vector__XXX
 SG_ ClimtHeatRear_D_Rq : 54|3@0+ (1,0) [0|7] "SED" Vector__XXX
 SG_ SnowPlowMde_B_Enbl : 2|1@0+ (1,0) [0|1] "SED"  BCM
 SG_ WndwFrontHeat_B_Stat : 4|1@0+ (1,0) [0|1] "SED"  GENERIC
 SG_ StopStrtDrvMde_B_RqBtn : 3|1@0+ (1,0) [0|1] "SED" Vector__XXX
 SG_ HvacHtrCore_Te_Rq : 49|10@0+ (0.25,-50) [-50|205.75] "degC" Vector__XXX
 SG_ HtrCorePump_B_Rq : 6|1@0+ (1,0) [0|1] "SED" Vector__XXX
 SG_ ClimtHeat_D_Rq : 20|3@0+ (1,0) [0|7] "SED"  SOBDMD_AHCM_PTC
 SG_ ClimtCool_D_Rq : 23|3@0+ (1,0) [0|7] "SED" Vector__XXX
 SG_ HvacEvap_Te_Rq : 33|10@0+ (0.125,-50) [-50|77.875] "Degrees C" Vector__XXX
 SG_ HvacEvap_Te_Actl : 17|10@0+ (0.125,-50) [-50|77.75] "Degrees C" Vector__XXX
 SG_ HvacAirCond_B_Rq : 7|1@0+ (1,0) [0|1] "SED"  GFM2_UIM
 SG_ HvacEvap_Te_Offst : 1|10@0+ (0.125,-50) [-50|77.875] "Degrees C" Vector__XXX
 SG_ ClimtDeltaLoad_Pw_Actl : 39|6@0+ (50,-1600) [-1600|1450] "watts" Vector__XXX
 SG_ ClimtPw_B_Rq : 5|1@0+ (1,0) [0|1] "SED" Vector__XXX

BO_ 578 Body_Info_4: 8 BCM
 SG_ PtLatchActv_B_RqBcm : 56|1@0+ (1,0) [0|1] "SED"  GWM
 SG_ immoSecureIdleMode : 61|2@0+ (1,0) [0|3] "SED"  SOBDMB_AWDC,DCMR_EAWD,GWM
 SG_ ReFuelSwtchStat_D_Actl : 63|2@0+ (1,0) [0|3] "SED"  GWM
 SG_ FuelPumpPwr_D_Stat : 50|3@0+ (1,0) [0|7] "SED"  GWM
 SG_ BattULo_U_Actl : 39|8@0+ (0.0625,0) [0|15.875] "volt"  ACCMB,DCDC_LISB,DCACA_GAS,DCACA_HEV,OBCC,GFM2_UIM,SOBDM_BCCM,GFM_CPLR,BECM,ACCM,DCDC_HEV,GWM
 SG_ PrkLckCtl_B_Enbl : 22|1@0+ (1,0) [0|1] "SED"  GWM
 SG_ PrkLckCtlMsgTxt_D_Rq : 55|2@0+ (1,0) [0|3] "SED"  GWM
 SG_ PrkLckCtlAvail_T_Stat : 47|8@0+ (1,0) [0|255] "second"  GWM
 SG_ BrkTrnShifLck_B_Stat : 23|1@0+ (1,0) [0|1] "SED"  GWM
 SG_ PrkLckCtlUnlck_D_Stat : 58|2@0+ (1,0) [0|3] "SED"  GWM
 SG_ PrkLckCtlTow_B_Enbl : 59|1@0+ (1,0) [0|1] "SED"  GWM
 SG_ DriverCrankingReq : 51|1@0+ (1,0) [0|1] "SED"  GWM
 SG_ EngOff_T_Actl : 7|16@0+ (1,0) [0|65534] "second^0.5"  DCMR_ELSD,GWM
 SG_ DcacElPw_D_Rq : 53|2@0+ (1,0) [0|3] "SED"  GWM
 SG_ BattULo_I_Actl : 21|14@0+ (0.0625,-512) [-512|511.875] "ampere"  GFM2_UIM,GWM

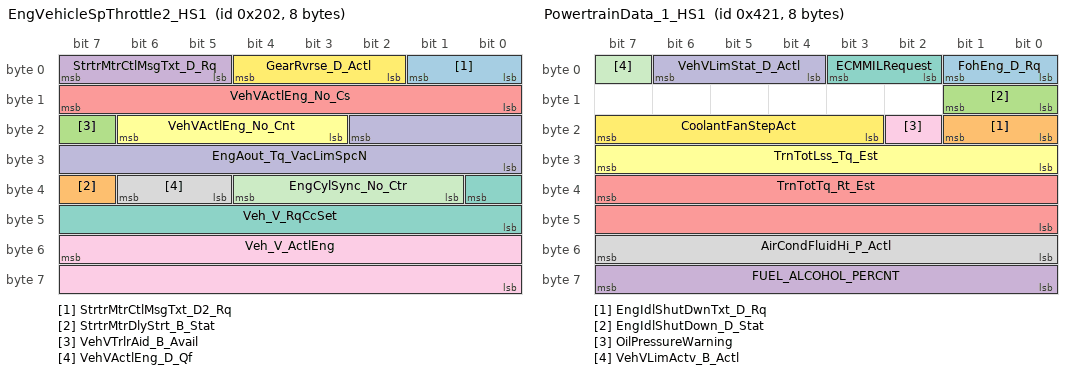
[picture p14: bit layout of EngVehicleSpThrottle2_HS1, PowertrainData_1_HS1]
BO_ 514 EngVehicleSpThrottle2_HS1: 8 GWM
 SG_ StrtrMtrCtlMsgTxt_D2_Rq : 1|2@0+ (1,0) [0|3] "SED"  BCM
 SG_ StrtrMtrDlyStrt_B_Stat : 39|1@0+ (1,0) [0|1] "SED"  BCM
 SG_ VehVTrlrAid_B_Avail : 23|1@0+ (1,0) [0|1] "SED"  GENERIC
 SG_ StrtrMtrCtlMsgTxt_D_Rq : 7|3@0+ (1,0) [0|7] "SED"  GENERIC
 SG_ VehVActlEng_No_Cs : 15|8@0+ (1,0) [0|255] "Unitless"  GENERIC
 SG_ VehVActlEng_No_Cnt : 22|4@0+ (1,0) [0|15] "Unitless"  GENERIC
 SG_ Veh_V_RqCcSet : 32|9@0+ (0.5,0) [0|255.5] "kph"  GENERIC
 SG_ VehVActlEng_D_Qf : 38|2@0+ (1,0) [0|3] "SED"  PACM,BCMC_CPDB,BECM,BCM
 SG_ Veh_V_ActlEng : 55|16@0+ (0.01,0) [0|655.35] "kph"  BCMC_CPDB,AFCM,DCACA_GAS,DCACA_HEV,GFM2_UIM,BECMB_EPM,PACM,BCM,BECM
 SG_ EngAout_Tq_VacLimSpcN : 18|11@0+ (1,-500) [-500|1547] "Nm"  GENERIC
 SG_ EngCylSync_No_Ctr : 36|4@0+ (1,0) [0|15] "unitless"  GENERIC
 SG_ GearRvrse_D_Actl : 4|3@0+ (1,0) [0|7] "SED"  GFM2_UIM,PACM,BCM

BO_ 1057 PowertrainData_1_HS1: 8 GWM
 SG_ FohEng_D_Rq : 1|2@0+ (1,0) [0|3] "SED" Vector__XXX
 SG_ EngIdlShutDwnTxt_D_Rq : 17|2@0+ (1,0) [0|3] "SED" Vector__XXX
 SG_ EngIdlShutDown_D_Stat : 9|2@0+ (1,0) [0|3] "SED"  BCM
 SG_ FUEL_ALCOHOL_PERCNT : 63|8@0+ (0.393700787,0) [0|99.999899898] "Percent" Vector__XXX
 SG_ TrnTotTq_Rt_Est : 39|16@0+ (0.001,0) [0|65.533] "Unitless" Vector__XXX
 SG_ TrnTotLss_Tq_Est : 31|8@0+ (0.5,0) [0|126.5] "Nm" Vector__XXX
 SG_ ECMMILRequest : 3|2@0+ (1,0) [0|3] "SED"  GFM2_UIM
 SG_ AirCondFluidHi_P_Actl : 55|8@0+ (0.125,0) [0|31.625] "bar" Vector__XXX
 SG_ OilPressureWarning : 18|1@0+ (1,0) [0|1] "SED"  GFM2_UIM,ICM
 SG_ VehVLimStat_D_Actl : 6|3@0+ (1,0) [0|7] "SED" Vector__XXX
 SG_ VehVLimActv_B_Actl : 7|1@0+ (1,0) [0|1] "SED" Vector__XXX
 SG_ CoolantFanStepAct : 23|5@0+ (1,0) [0|31] "Steps"  BCM

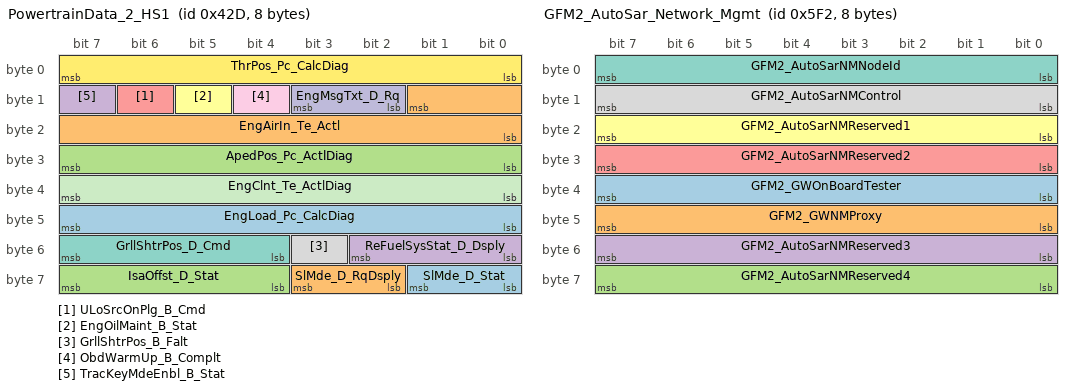
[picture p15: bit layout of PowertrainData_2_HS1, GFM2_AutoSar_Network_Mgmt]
BO_ 1069 PowertrainData_2_HS1: 8 GWM
 SG_ SlMde_D_Stat : 57|2@0+ (1,0) [0|3] "SED" Vector__XXX
 SG_ SlMde_D_RqDsply : 59|2@0+ (1,0) [0|3] "SED" Vector__XXX
 SG_ IsaOffst_D_Stat : 63|4@0+ (1,0) [0|15] "SED" Vector__XXX
 SG_ ReFuelSysStat_D_Dsply : 50|3@0+ (1,0) [0|7] "SED" Vector__XXX
 SG_ ULoSrcOnPlg_B_Cmd : 14|1@0+ (1,0) [0|1] "SED"  DCDC_LISB,SOBDM_BCCM,BECM,DCDC_HEV
 SG_ EngOilMaint_B_Stat : 13|1@0+ (1,0) [0|1] "SED" Vector__XXX
 SG_ GrllShtrPos_D_Cmd : 55|4@0+ (1,0) [0|15] "SED"  BCM
 SG_ GrllShtrPos_B_Falt : 51|1@0+ (1,0) [0|1] "SED"  BCM
 SG_ ObdWarmUp_B_Complt : 12|1@0+ (1,0) [0|1] "SED"  GFM3_DCACB,SOBDMB_AWDC,DCACA_GAS,DCACA_HEV,DCDC_LISB,OBCC,SOBDM_BCCM,ACCM,BECM,DCDC_HEV
 SG_ EngMsgTxt_D_Rq : 11|2@0+ (1,0) [0|3] "SED" Vector__XXX
 SG_ EngClnt_Te_ActlDiag : 39|8@0+ (1,-40) [-40|215] "degC"  SOBDMB_AWDC,BECM
 SG_ ThrPos_Pc_CalcDiag : 7|8@0+ (0.392157,0) [0|100.000035] "%" Vector__XXX
 SG_ EngLoad_Pc_CalcDiag : 47|8@0+ (0.392157,0) [0|100.000035] "%"  SOBDMB_AWDC,BECM
 SG_ EngAirIn_Te_Actl : 9|10@0+ (0.25,-128) [-128|127.25] "degC"  AFCM,BCM
 SG_ ApedPos_Pc_ActlDiag : 31|8@0+ (0.392157,0) [0|100.000035] "%"  SOBDMB_AWDC,BECM
 SG_ TracKeyMdeEnbl_B_Stat : 15|1@0+ (1,0) [0|1] "SED" Vector__XXX

BO_ 1037 Body_Info_15: 8 BCM
 SG_ BattRgenLo_I_Est : 7|8@0+ (1,0) [0|255] "ampere"  DCDC_LISB

BO_ 878 DCACA_Data4_HS1: 8 GWM
 SG_ PwBedPnlEnblScnd_B_Rq : 48|1@0+ (1,0) [0|1] "SED"  GFM3_DCACB
 SG_ DcacSysScnd_B_Falt : 40|1@0+ (1,0) [0|1] "SED"  GFM3_DCACB
 SG_ DcacOnScnd_B_Rq : 32|1@0+ (1,0) [0|1] "SED"  GFM3_DCACB
 SG_ DcacGfciTestScnd_B_Rq : 24|1@0+ (1,0) [0|1] "SED"  GFM3_DCACB
 SG_ EngExhMdeHrStrt_D_Stat : 53|5@0+ (1,0) [0|31] "SED" Vector__XXX
 SG_ EngExhMdeHrEnd_D_Stat : 63|5@0+ (1,0) [0|31] "SED" Vector__XXX
 SG_ EngExhMdeHrEnbl_D_Stat : 58|2@0+ (1,0) [0|3] "SED" Vector__XXX
 SG_ DcacGfciTest_B_Rq : 0|1@0+ (1,0) [0|1] "SED"  DCACA_GAS,DCACA_HEV
 SG_ DcacOut_Pw_DsplyMx : 23|10@0+ (10,0) [0|10220] "watts"  GENERIC
 SG_ DcacOut1_Pw_Dsply : 39|7@0+ (100,0) [0|12600] "watts"  GENERIC
 SG_ DcacOut2_Pw_Dsply : 47|7@0+ (100,0) [0|12600] "watts"  GENERIC
 SG_ DcacHw_D_Confg : 11|4@0+ (1,0) [0|15] "SED"  GENERIC
 SG_ DcacFaltMsgTxt_D_Rq : 15|4@0+ (1,0) [0|15] "SED"  BCM
 SG_ DcacLoFuelMsgTxt_D_Rq : 29|5@0+ (1,0) [0|31] "SED"  GENERIC
 SG_ DcacEngOnMsgTxt_D_Rq : 55|2@0+ (1,0) [0|3] "SED"  GENERIC
 SG_ DcacElPw_D_Stat : 2|2@0+ (1,0) [0|3] "SED"  BCM
 SG_ PwBedPnlEnbl_B_Rq : 3|1@0+ (1,0) [0|1] "SED"  DCACA_GAS,DCACA_HEV
 SG_ DcacOn_B_Rq : 4|1@0+ (1,0) [0|1] "SED"  DCACA_GAS,DCACA_HEV
 SG_ DcacSys_B_Falt : 5|1@0+ (1,0) [0|1] "SED"  BCM,DCACA_HEV,DCACA_GAS
 SG_ DcacLedCtl_D_Rq : 7|2@0+ (1,0) [0|3] "SED"  DCACA_HEV,DCACA_GAS,DCDC_HEV

BO_ 2010 TesterPhysicalResGFM2: 8 GFM2_UIM
 SG_ TesterPhysicalResGFM2 : 7|64@0+ (1,0) [0|1.84467E+019] "unitless"  TSTR

BO_ 1522 GFM2_AutoSar_Network_Mgmt: 8 GFM2_UIM
 SG_ GFM2_GWOnBoardTester : 39|8@0+ (1,0) [0|255] "unitless"  GWM
 SG_ GFM2_GWNMProxy : 47|8@0+ (1,0) [0|255] "unitless"  GWM
 SG_ GFM2_AutoSarNMReserved4 : 63|8@0+ (1,0) [0|255] "unitless"  GWM
 SG_ GFM2_AutoSarNMReserved3 : 55|8@0+ (1,0) [0|255] "unitless"  GWM
 SG_ GFM2_AutoSarNMReserved2 : 31|8@0+ (1,0) [0|255] "unitless"  GWM
 SG_ GFM2_AutoSarNMReserved1 : 23|8@0+ (1,0) [0|255] "unitless"  GWM
 SG_ GFM2_AutoSarNMNodeId : 7|8@0+ (1,0) [0|255] "unitless"  GWM
 SG_ GFM2_AutoSarNMControl : 15|8@0+ (1,0) [0|255] "unitless"  GWM

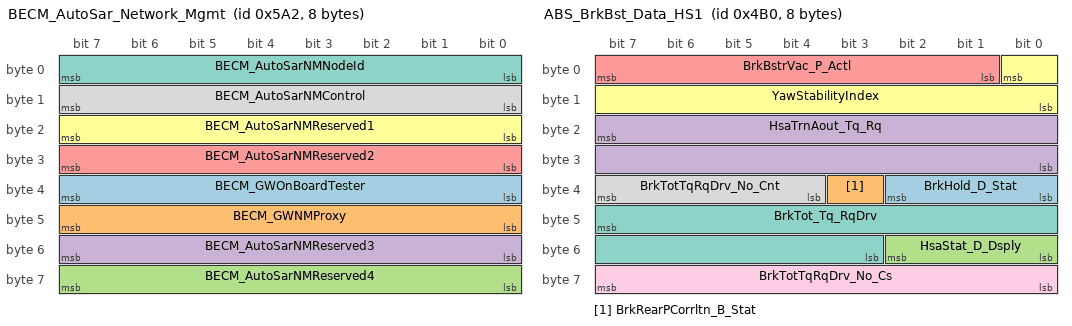
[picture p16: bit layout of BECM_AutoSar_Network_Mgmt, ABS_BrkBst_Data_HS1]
BO_ 1442 BECM_AutoSar_Network_Mgmt: 8 BECM
 SG_ BECM_GWOnBoardTester : 39|8@0+ (1,0) [0|255] "unitless"  GENERIC
 SG_ BECM_GWNMProxy : 47|8@0+ (1,0) [0|255] "unitless"  GENERIC
 SG_ BECM_AutoSarNMReserved4 : 63|8@0+ (1,0) [0|255] "unitless"  GENERIC
 SG_ BECM_AutoSarNMReserved3 : 55|8@0+ (1,0) [0|255] "unitless"  GENERIC
 SG_ BECM_AutoSarNMReserved2 : 31|8@0+ (1,0) [0|255] "unitless"  GENERIC
 SG_ BECM_AutoSarNMReserved1 : 23|8@0+ (1,0) [0|255] "unitless"  GENERIC
 SG_ BECM_AutoSarNMNodeId : 7|8@0+ (1,0) [0|255] "unitless"  GENERIC
 SG_ BECM_AutoSarNMControl : 15|8@0+ (1,0) [0|255] "unitless"  GENERIC

BO_ 1200 ABS_BrkBst_Data_HS1: 8 GWM
 SG_ BrkHold_D_Stat : 34|3@0+ (1,0) [0|7] "SED"  BCM
 SG_ BrkRearPCorrltn_B_Stat : 35|1@0+ (1,0) [0|1] "SED"  GENERIC
 SG_ HsaStat_D_Dsply : 50|3@0+ (1,0) [0|7] "SED"  GENERIC
 SG_ HsaTrnAout_Tq_Rq : 23|16@0+ (4,-131072) [-131072|131060] "Nm" Vector__XXX
 SG_ BrkBstrVac_P_Actl : 7|7@0+ (8,0) [0|1008] "Millibar" Vector__XXX
 SG_ YawStabilityIndex : 0|9@0+ (1,-256) [-256|255] "%"  GENERIC
 SG_ BrkTot_Tq_RqDrv : 47|13@0+ (4,0) [0|32760] "Nm"  BCM
 SG_ BrkTotTqRqDrv_No_Cnt : 39|4@0+ (1,0) [0|15] "unitless"  BCM
 SG_ BrkTotTqRqDrv_No_Cs : 63|8@0+ (1,0) [0|255] "unitless"  BCM

BO_ 2015 TesterFunctionalReq_H1: 8 TSTR
 SG_ TesterFunctionalReq : 7|64@0+ (1,0) [0|1.84467E+019] "unitless"  GFM2_BCCMB,ACCMB,GFM3_DCACB,OBCC,DCACA_GAS,DCACA_HEV,DCDC_LISB,SOBDMB_AWDC,FHCM,AFCM,DCMR_EAWD,BCMC_CPDB,ICM,BECMB_EPM,GFM2_UIM,PACM,DCMR_ELSD,GFM_CPLR,SOBDM_BCCM,ACCM,GWM,GENERIC,DCDC_HEV,BECM,BCM,SOBDMD_AHCM_PTC

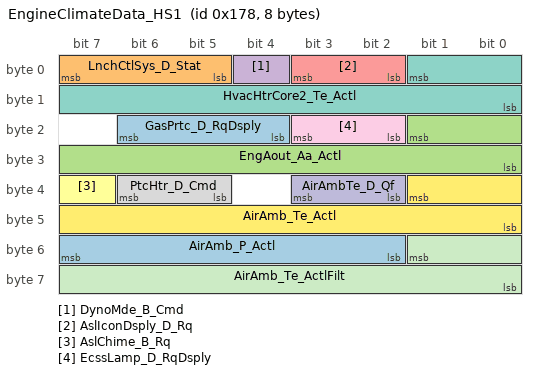
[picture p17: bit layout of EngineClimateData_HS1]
BO_ 376 EngineClimateData_HS1: 8 GWM
 SG_ GasPrtc_D_RqDsply : 22|3@0+ (1,0) [0|7] "SED"  GENERIC
 SG_ LnchCtlSys_D_Stat : 7|3@0+ (1,0) [0|7] "SED"  GENERIC
 SG_ EngAout_Aa_Actl : 17|10@0+ (0.05,-25.6) [-25.6|25.55] "rpm/ms"  GENERIC
 SG_ DynoMde_B_Cmd : 4|1@0+ (1,0) [0|1] "SED"  GENERIC
 SG_ AslIconDsply_D_Rq : 3|2@0+ (1,0) [0|3] "SED"  GENERIC
 SG_ AslChime_B_Rq : 39|1@0+ (1,0) [0|1] "SED"  GENERIC
 SG_ HvacHtrCore2_Te_Actl : 1|10@0+ (0.25,-50) [-50|205.5] "degC"  GENERIC
 SG_ PtcHtr_D_Cmd : 38|2@0+ (1,0) [0|3] "SED"  GENERIC
 SG_ EcssLamp_D_RqDsply : 19|2@0+ (1,0) [0|3] "SED"  GENERIC
 SG_ AirAmbTe_D_Qf : 35|2@0+ (1,0) [0|3] "SED"  BCM
 SG_ AirAmb_Te_ActlFilt : 49|10@0+ (0.25,-128) [-128|127.75] "deg C"  ACCMB,BECM,GWM,ACCM,BCM
 SG_ AirAmb_Te_Actl : 33|10@0+ (0.25,-128) [-128|127.75] "degC"  DCDC_LISB,SOBDM_BCCM,OBCC,GFM2_UIM,DCDC_HEV,BCM
 SG_ AirAmb_P_Actl : 55|6@0+ (10,500) [500|1110] "mbar"  BCM

BO_TX_BU_ 1085 : BECM,GWM,DCDC_LISB,DCDC_HEV;
BO_TX_BU_ 2010 : GFM2_BCCMB,GFM2_UIM;
CM_ BO_ 534 "DCR 1833 to update Tx from GWM to EP100ms. Wheel Count signals are used by complex algorithm to determine Tire Pressure by Location & can't change from 20msec. (jweinfur)";
CM_ SG_ 534 WhlRotatRr_No_Cnt "DCR 1833 to update Tx from GWM to EP100ms. Wheel Count signals are used by complex algorithm to determine Tire Pressure by Location & can't change from 20msec. (jweinfur)";
CM_ SG_ 534 WhlRotatRl_No_Cnt "DCR 1833 to update Tx from GWM to EP100ms. Wheel Count signals are used by complex algorithm to determine Tire Pressure by Location & can't change from 20msec. (jweinfur)";
CM_ SG_ 534 WhlRotatFr_No_Cnt "DCR 1833 to update Tx from GWM to EP100ms. Wheel Count signals are used by complex algorithm to determine Tire Pressure by Location & can't change from 20msec. (jweinfur)";
CM_ SG_ 534 WhlRotatFl_No_Cnt "DCR 1833 to update Tx from GWM to EP100ms. Wheel Count signals are used by complex algorithm to determine Tire Pressure by Location & can't change from 20msec. (jweinfur)";
CM_ SG_ 534 BrkObdData_No_Actl "Signal not transmitted on gas, diesel and HEV.  Only supported on PHEV.";
CM_ SG_ 534 BrkObdIndex_No_Actl "Signal not transmitted on gas, diesel and HEV.  Only supported on PHEV.";
CM_ BO_ 532 "IC is NOT to use data in this message for displays, Used data from 415 instead.";
CM_ BO_ 531 "IC is NOT to use data in this message for displays, Used data from 415 instead.";
CM_ BO_ 611 "Used on Applications with 4x4 supplied by Motorola.";
CM_ SG_ 611 AwdStat_D_RqDsply "Signal not transmitted on programs that do not have AWD.";
CM_ SG_ 611 AwdSrvcRqd_B_Rq "Signal not transmitted on programs that do not have AWD.";
CM_ SG_ 611 AwdLck_Tq_Rq "Signal not transmitted on programs that do not have AWD.";
CM_ SG_ 90 TrnGsmNtmState_D_Actl "Signal not transmitted on vehicles that do not have shift by wire.";
CM_ SG_ 90 DrQltyDrv_D_StatGsm "Signal not transmitted on vehicles that do not have shift by wire.";
CM_ SG_ 90 TrnBtsiOvrrd_B_Stat "Signal not transmitted on vehicles that do not have shift by wire.";
CM_ SG_ 90 TrnValidGearRq_D_Stat "Signal not transmitted on vehicles that do not have shift by wire.";
CM_ SG_ 90 TrnGearRqCnt_B_Actl "Signal not transmitted on vehicles that do not have shift by wire.";
CM_ SG_ 90 TrnGearButtn_U_Actl "Signal not transmitted on vehicles that do not have shift by wire.";
CM_ SG_ 90 TrnGearButtn_B_ActlR2 "Signal not transmitted on vehicles that do not have shift by wire.";
CM_ SG_ 90 TrnGearButtn_B_ActlR1 "Signal not transmitted on vehicles that do not have shift by wire.";
CM_ SG_ 90 TrnGearButtn_B_ActlR0 "Signal not transmitted on vehicles that do not have shift by wire.";
CM_ SG_ 90 TrnGearButtn_B_ActlP2 "Signal not transmitted on vehicles that do not have shift by wire.";
CM_ SG_ 90 TrnGearButtn_B_ActlP1 "Signal not transmitted on vehicles that do not have shift by wire.";
CM_ SG_ 90 TrnGearButtn_B_ActlP0 "Signal not transmitted on vehicles that do not have shift by wire.";
CM_ SG_ 90 TrnGearButtn_B_ActlN2 "Signal not transmitted on vehicles that do not have shift by wire.";
CM_ SG_ 90 TrnGearButtn_B_ActlN1 "Signal not transmitted on vehicles that do not have shift by wire.";
CM_ SG_ 90 TrnGearButtn_B_ActlN0 "Signal not transmitted on vehicles that do not have shift by wire.";
CM_ SG_ 90 TrnGearButtn_B_ActlM2 "Signal not transmitted on vehicles that do not have shift by wire.";
CM_ SG_ 90 TrnGearButtn_B_ActlM1 "Signal not transmitted on vehicles that do not have shift by wire.";
CM_ SG_ 90 TrnGearButtn_B_ActlM0 "Signal not transmitted on vehicles that do not have shift by wire.";
CM_ SG_ 90 TrnGearButtn_B_ActlD2 "Signal not transmitted on vehicles that do not have shift by wire.";
CM_ SG_ 90 TrnGearButtn_B_ActlD1 "Signal not transmitted on vehicles that do not have shift by wire.";
CM_ SG_ 90 TrnGearButtn_B_ActlD0 "Signal not transmitted on vehicles that do not have shift by wire.";
CM_ SG_ 90 TrnGear_No_Cs "Signal not transmitted on vehicles that do not have shift by wire.";
CM_ SG_ 90 TrnGear_No_Cnt "Signal not transmitted on vehicles that do not have shift by wire.";
CM_ SG_ 90 TrnGear_D_RqDrv "Signal not transmitted on vehicles that do not have shift by wire.";
CM_ SG_ 90 BrkSwtchPos_B_ActlGsm "Signal not transmitted on vehicles that do not have shift by wire.";
CM_ SG_ 92 TrnGearMsgTxt2_D_Rq "Signal not transmitted on vehicles that do not have shift by wire.";
CM_ SG_ 92 TrnSbwSysHlth_D_Actl "Signal not transmitted on vehicles that do not have shift by wire.";
CM_ SG_ 92 TrnGearNtmAllow_B_Stat "Signal not transmitted on vehicles that do not have shift by wire.";
CM_ SG_ 92 TrnDtpCmd_D_Actl "Signal not transmitted on vehicles that do not have shift by wire.";
CM_ SG_ 92 TrnGearCmd_No_Cs "Signal not transmitted on vehicles that do not have shift by wire.";
CM_ SG_ 92 TrnValidGear_D_Cnfm "Signal not transmitted on vehicles that do not have shift by wire.";
CM_ SG_ 92 TrnNtrlTowCmd_D_Actl "Signal not transmitted on vehicles that do not have shift by wire.";
CM_ SG_ 92 TrnGearCmd_Pc_ActlPt "Signal not transmitted on vehicles that do not have shift by wire.";
CM_ SG_ 92 TrnGear_D_RqPt "Signal not transmitted on vehicles that do not have shift by wire.";
CM_ SG_ 92 TrnCmdState_B_Actl "Signal not transmitted on vehicles that do not have shift by wire.";
CM_ SG_ 92 TrnCmdCnt_B_Actl "Signal not transmitted on vehicles that do not have shift by wire.";
CM_ SG_ 92 PrkBrkActv_D_RqTrnGear "Signal not transmitted on vehicles that do not have shift by wire.";
CM_ SG_ 92 TrnGearMsgTxt_D_Rq "Signal not transmitted on vehicles that do not have shift by wire.";
CM_ SG_ 92 TrnGearCmd_No_Cnt "Signal not transmitted on vehicles that do not have shift by wire.";
CM_ SG_ 359 TrnAin_Tq_Actl "Signal not transmitted on HEV variances.";
CM_ SG_ 359 PlgActvArb_B_Actl "Only supported on PHEV programs.  PlgActvArb_B_Actl HPCM will Tx on Powersplit PHEV�s,  On MHT PHEVs the PCM_HEV will Tx and HPCM will Rx. 
";
CM_ SG_ 359 TrnAinTq_D_Qf "Signal not transmitted on HEV variances.";
CM_ SG_ 358 HiElPwInhbt_B_Stat "Signal not transmitted on HEV programs";
CM_ SG_ 358 AutoStopPtDelta_I_Est "Signal not transmitted on vehicles that do not have autostop/stop-start feature.";
CM_ SG_ 1086 ElLoadCtl_D_Rq "Signal not transmitted on HEV variants.";
CM_ BO_ 1085 "HS1 0x43D Tx by HS1 BECM, DCDC_HEV, DCDC_LISB
Or FrameGateway from FD1
Set to FixedPeriodic 50ms at all nodes so the transmit method and rate export from mdc to dbc
Program specific msg lists update attributes as needed.";
CM_ SG_ 1085 ULoRgenTestMde_B_Stat "Signal not transmitted on HEV variants.";
CM_ SG_ 1085 BattTracCool_D_RqDcdc "Signal not transmitted on gas and diesel variants.";
CM_ SG_ 1085 PwSrcULoComm_B_Falt "Signal not transmitted on HEV variants.";
CM_ SG_ 1085 DcdcULo_U_Actl "Signal not transmitted on gas and diesel variants.";
CM_ SG_ 1085 DcdcUHi_I_Actl "Signal not transmitted on gas and diesel variants.";
CM_ SG_ 1085 DcdcUHi_U_Actl "Signal not transmitted on gas and diesel variants.";
CM_ BO_ 603 "48V mHEV: ECM_HEVDSL is Tx
MHT HEV: PCM_HEV is Tx
Powersplit HEV: SOBDMC_HPCM is Tx
";
CM_ SG_ 603 WhlDirAvgDrv_D_Actl "48V mHEV: ECM_HEVDSL is Tx,  MHT HEV: PCM_HEV is Tx,  Powersplit HEV: SOBDMC_HPCM is Tx";
CM_ SG_ 603 PrplTqMnRgen_B_Actl "48V mHEV: ECM_HEVDSL is Tx,  MHT HEV: PCM_HEV is Tx,  Powersplit HEV: SOBDMC_HPCM is Tx";
CM_ SG_ 603 BattTracCnnct_D_Rq "48V mHEV: ECM_HEVDSL is Tx,  MHT HEV: PCM_HEV is Tx,  Powersplit HEV: SOBDMC_HPCM is Tx";
CM_ SG_ 1088 HvacPrecondMode2_D_Rq "Signal not transmitted on vehicles that do not have the Fuel operated heater feature.";
CM_ SG_ 1088 HvacPrecondBlwr2_D_Rq "Signal not transmitted on vehicles that do not have the Fuel operated heater feature.";
CM_ SG_ 870 PolicePurstMde_B_Stat "Normal�SED�EP 1000. Using�100FP�can�result� in100ms�w/c�latency.��Latency�accepted�for feature/function by�SME since existing FGW msg.";
CM_ SG_ 1071 CluPdl_PcRate_Actl "Signal not transmitted on HEV variants.";
CM_ SG_ 1071 CluPdlPosPcMeas_D_Qf "Signal not transmitted on HEV variants.";
CM_ SG_ 1071 CluPdlPos_Pc_Meas "Signal not transmitted on HEV variants.";
CM_ SG_ 1071 EngAoutIdl_N_Ntrl "Signal not transmitted on HEV variants and diesel.";
CM_ BO_ 130 "DCR 1745  to update Tx from GWM to EP100ms. SteMdule_I_Est & SteMdule_U_Meas are used by BMS system & filtered. The filter uses standard periodic rate & changing to EP would adversely affect the filter.(jweinfur)";
CM_ SG_ 130 VehVTrlrAid_B_Rq "VR session start- req. limit blower speed no more than X volts.  CC restriction on time msg. will be honored.Double Event msg1st event to request limit, 2nd event to release limit, No msg. CC Grammar v7.xls";
CM_ SG_ 130 SteMdule_U_Meas "DCR 1745  to update Tx from GWM to EP100ms. SteMdule_I_Est & SteMdule_U_Meas are used by BMS system & filtered. The filter uses standard periodic rate & changing to EP would adversely affect the filter.(jweinfur)";
CM_ SG_ 130 SteMdule_I_Est "DCR 1745  to update Tx from GWM to EP100ms. SteMdule_I_Est & SteMdule_U_Meas are used by BMS system & filtered. The filter uses standard periodic rate & changing to EP would adversely affect the filter.(jweinfur)";
CM_ SG_ 1076 CenterStackRing_D_Actl "The Center Stack sends the CPLR a signal to turn On or Off the light Ring, This is a customer selectable preference switch";
CM_ SG_ 1072 StopLamp_B_RqTrlrBrk "Signal not transmitted on all variants.";
CM_ SG_ 1072 Outside_Air_Temp_Stat "Filtered value, i.e. same as disply for customer";
CM_ SG_ 514 EngAout_Tq_VacLimSpcN "Signal not transmitted on gas and diesel variances.";
CM_ SG_ 514 EngCylSync_No_Ctr "Signal not transmitted on gas and diesel variances.";
CM_ SG_ 514 GearRvrse_D_Actl "Do not implement GearRvrse_D_Actl  until eTracker 8804151 is approved, 11/24/09";
CM_ SG_ 1057 FohEng_D_Rq "Signal not transmitted on vehicles that do not have the fuel operated heater feature.";
CM_ SG_ 1057 EngIdlShutDown_D_Stat "Signal not transmitted on diesel variants.";
CM_ SG_ 1057 FUEL_ALCOHOL_PERCNT "signal not transmitted on diesel and HEV variants.";
CM_ SG_ 1057 TrnTotTq_Rt_Est "Signal not transmitted on gas and HEV variants.";
CM_ SG_ 1057 TrnTotLss_Tq_Est "Signal not transmitted on gas and HEV variants.";
CM_ SG_ 1057 VehVLimStat_D_Actl "Signal not transmitted on gas and HEV variants.";
CM_ SG_ 1057 VehVLimActv_B_Actl "Signal not transmitted on gas and HEV variants.";
CM_ SG_ 1069 SlMde_D_Stat "IPC and HUD_ADV Receve from HS3 FGW 0x42D, not HS3 0x38A, MSG DCR 506.";
CM_ SG_ 1069 SlMde_D_RqDsply "IPC and HUD_ADV Receve from HS3 FGW 0x42D, not HS3 0x38A, MSG DCR 506.";
CM_ SG_ 1069 ObdWarmUp_B_Complt "Signal not transmitted on gas and diesel variants.";
CM_ SG_ 1069 EngMsgTxt_D_Rq "Signal not transmitted on diesel variants.";
CM_ SG_ 1069 EngClnt_Te_ActlDiag "Signal not transmitted on gas variants.";
CM_ SG_ 1069 EngLoad_Pc_CalcDiag "Signal not transmitted on gas variants.";
CM_ SG_ 1069 ApedPos_Pc_ActlDiag "Signal not transmitted on gas variants.";
CM_ SG_ 1442 BECM_GWOnBoardTester "Signal not transmitted on gas, diesel and HEV.  Only supported on PHEV.";
CM_ SG_ 1442 BECM_GWNMProxy "Signal not transmitted on gas, diesel and HEV.  Only supported on PHEV.";
CM_ SG_ 1442 BECM_AutoSarNMReserved4 "Signal not transmitted on gas, diesel and HEV.  Only supported on PHEV.";
CM_ SG_ 1442 BECM_AutoSarNMReserved3 "Signal not transmitted on gas, diesel and HEV.  Only supported on PHEV.";
CM_ SG_ 1442 BECM_AutoSarNMReserved2 "Signal not transmitted on gas, diesel and HEV.  Only supported on PHEV.";
CM_ SG_ 1442 BECM_AutoSarNMReserved1 "Signal not transmitted on gas, diesel and HEV.  Only supported on PHEV.";
CM_ SG_ 1442 BECM_AutoSarNMNodeId "Signal not transmitted on gas, diesel and HEV.  Only supported on PHEV.";
CM_ SG_ 1442 BECM_AutoSarNMControl "Signal not transmitted on gas, diesel and HEV.  Only supported on PHEV.";
CM_ BO_ 1200 "DCR 1836 to update Tx from GWM to EP100ms rejected due MPS6 TCM requires BrkTot_Tq_RqDrv at 20ms (bshu1).";
CM_ SG_ 1200 BrkTot_Tq_RqDrv "DCR 1836 to update Tx from GWM to EP100ms rejected due MPS6 TCM requires BrkTot_Tq_RqDrv at 20ms (bshu1).";
CM_ BO_ 2015 "OBDII Request ($7DF) messages are for FNOS 1.0.1 only.
Diagnostic Functional Addressing ($7DF) and Dual Rate Periodic messages are for FNOS I3 only.";
CM_ SG_ 376 EngAout_Aa_Actl "Signal not transmitted on HEV variants.";
BA_DEF_ BO_  "FrameRouting" STRING ;
BA_DEF_ BO_  "FrameGatewayNetwork" STRING ;
BA_DEF_ BO_  "NetworkInitialization" ENUM  "No","Yes";
BA_DEF_ BO_  "FrameGatewayId" HEX 0 1407;
BA_DEF_ BO_  "EventRateOfChange" INT 10 10000;
BA_DEF_ BO_  "GenMsgStartDelayTime" INT 0 10000;
BA_DEF_ BO_  "GenMsgNrOfRepetition" INT 0 100;
BA_DEF_ BO_  "GenMsgDelayTime" INT 0 1000;
BA_DEF_ BO_  "GenMsgCycleTime" INT 0 100000;
BA_DEF_ BO_  "GenMsgSendType" ENUM  "FixedPeriodic","Event","EnabledPeriodic","NotUsed","NotUsed","EventPeriodic","NotUsed","NotUsed","NoMsgSendType";
BA_DEF_ SG_  "U_CD764_MY2022_Tx" ENUM  "No","Yes";
BA_DEF_ SG_  "U_U55X_MY2022_Tx" ENUM  "No","Yes";
BA_DEF_ SG_  "U_CD542_MY2021_Tx" ENUM  "No","Yes";
BA_DEF_ SG_  "ECGUsedTxSignal" ENUM  "No","Yes";
BA_DEF_ SG_  "U_T6_MCA_MY2020_Tx" ENUM  "No","Yes";
BA_DEF_ SG_  "U_P702_MY2021_Tx" ENUM  "No","Yes";
BA_DEF_ SG_  "U_CX727_MY2021_Tx" ENUM  "No","Yes";
BA_DEF_ SG_  "U_CD764_MY2022_Rx" ENUM  "No","Yes";
BA_DEF_ SG_  "U_U55X_MY2022_Rx" ENUM  "No","Yes";
BA_DEF_ SG_  "U_CD542_MY2021_Rx" ENUM  "No","Yes";
BA_DEF_ SG_  "ECGUsedRxSignal" ENUM  "No","Yes";
BA_DEF_ SG_  "U_T6_MCA_MY2020_Rx" ENUM  "No","Yes";
BA_DEF_ SG_  "U_P702_MY2021_Rx" ENUM  "No","Yes";
BA_DEF_ SG_  "U_CX727_MY2021_Rx" ENUM  "No","Yes";
BA_DEF_ SG_  "GenSigStartValue" HEX 0 268435455;
BA_DEF_ SG_  "MetaData" ENUM  "No","Yes";
BA_DEF_ SG_  "ContentDependant" ENUM  "No","Yes";
BA_DEF_ SG_  "GenSigStartValueInteger" INT 0 1000000000;
BA_DEF_ SG_  "UsedOnPgmDBC" ENUM  "No","Yes";
BA_DEF_ SG_  "WakeupSignal" ENUM  "No","Yes";
BA_DEF_ SG_  "GenSigInactiveValue" INT 0 100000;
BA_DEF_ SG_  "GenSigSendType" ENUM  "Cyclic","OnWrite","vector_leerstring","OnChange","vector_leerstring","IfActive","vector_leerstring","NoSigSendType";
BA_DEF_ BO_  "OvtpPushApplication" ENUM  "FALSE","TRUE";
BA_DEF_ BO_  "SCP_FreshnessValueLength" INT 0 512;
BA_DEF_ BO_  "SCP_FreshnessValueTxLength" INT 0 512;
BA_DEF_ BO_  "SCP_AuthInfoTxLength" INT 0 512;
BA_DEF_ BO_  "GenMsgRoutingTimeoutTime" INT 0 5000;
BA_DEF_ BO_  "MessageGateway" ENUM  "No","Yes";
BA_DEF_ BO_  "NmAsrMessage" ENUM  "No","Yes";
BA_DEF_ BO_  "TpApplType" STRING ;
BA_DEF_ BO_  "DiagState" ENUM  "No","Yes";
BA_DEF_ BO_  "TpTxIndex" INT 0 536870911;
BA_DEF_ BO_  "DiagRequest" ENUM  "No","Yes";
BA_DEF_ BO_  "DiagResponse" ENUM  "No","Yes";
BA_DEF_ BO_  "GenMsgILSupport" ENUM  "No","Yes";
BA_DEF_DEF_  "FrameRouting" "";
BA_DEF_DEF_  "FrameGatewayNetwork" "NONE";
BA_DEF_DEF_  "NetworkInitialization" "Yes";
BA_DEF_DEF_  "FrameGatewayId" 0;
BA_DEF_DEF_  "EventRateOfChange" 10000;
BA_DEF_DEF_  "GenMsgStartDelayTime" 0;
BA_DEF_DEF_  "GenMsgNrOfRepetition" 1;
BA_DEF_DEF_  "GenMsgDelayTime" 20;
BA_DEF_DEF_  "GenMsgCycleTime" 0;
BA_DEF_DEF_  "GenMsgSendType" "NoMsgSendType";
BA_DEF_DEF_  "U_CD764_MY2022_Tx" "No";
BA_DEF_DEF_  "U_U55X_MY2022_Tx" "No";
BA_DEF_DEF_  "U_CD542_MY2021_Tx" "No";
BA_DEF_DEF_  "ECGUsedTxSignal" "No";
BA_DEF_DEF_  "U_T6_MCA_MY2020_Tx" "No";
BA_DEF_DEF_  "U_P702_MY2021_Tx" "No";
BA_DEF_DEF_  "U_CX727_MY2021_Tx" "No";
BA_DEF_DEF_  "U_CD764_MY2022_Rx" "No";
BA_DEF_DEF_  "U_U55X_MY2022_Rx" "No";
BA_DEF_DEF_  "U_CD542_MY2021_Rx" "No";
BA_DEF_DEF_  "ECGUsedRxSignal" "No";
BA_DEF_DEF_  "U_T6_MCA_MY2020_Rx" "No";
BA_DEF_DEF_  "U_P702_MY2021_Rx" "No";
BA_DEF_DEF_  "U_CX727_MY2021_Rx" "No";
BA_DEF_DEF_  "GenSigStartValue" 0;
BA_DEF_DEF_  "MetaData" "No";
BA_DEF_DEF_  "ContentDependant" "No";
BA_DEF_DEF_  "GenSigStartValueInteger" 0;
BA_DEF_DEF_  "UsedOnPgmDBC" "Yes";
BA_DEF_DEF_  "WakeupSignal" "No";
BA_DEF_DEF_  "GenSigInactiveValue" 0;
BA_DEF_DEF_  "GenSigSendType" "NoSigSendType";
BA_DEF_DEF_  "OvtpPushApplication" "FALSE";
BA_DEF_DEF_  "SCP_FreshnessValueLength" 64;
BA_DEF_DEF_  "SCP_FreshnessValueTxLength" 11;
BA_DEF_DEF_  "SCP_AuthInfoTxLength" 53;
BA_DEF_DEF_  "GenMsgRoutingTimeoutTime" 0;
BA_DEF_DEF_  "MessageGateway" "No";
BA_DEF_DEF_  "NmAsrMessage" "No";
BA_DEF_DEF_  "TpApplType" "";
BA_DEF_DEF_  "DiagState" "No";
BA_DEF_DEF_  "TpTxIndex" 0;
BA_DEF_DEF_  "DiagRequest" "No";
BA_DEF_DEF_  "DiagResponse" "No";
BA_DEF_DEF_  "GenMsgILSupport" "Yes";
BA_ "FrameRouting" BO_ 125 "FD1_CAN,0x7D;";
BA_ "FrameGatewayNetwork" BO_ 125 "FD1_CAN";
BA_ "FrameGatewayId" BO_ 125 125;
BA_ "GenMsgDelayTime" BO_ 125 10;
BA_ "FrameRouting" BO_ 119 "FD1_CAN,0x77;";
BA_ "FrameGatewayNetwork" BO_ 119 "FD1_CAN";
BA_ "FrameGatewayId" BO_ 119 119;
BA_ "GenMsgDelayTime" BO_ 119 10;
BA_ "FrameRouting" BO_ 1045 "FD1_CAN,0x415;";
BA_ "FrameGatewayNetwork" BO_ 1045 "FD1_CAN";
BA_ "FrameGatewayId" BO_ 1045 1045;
BA_ "GenMsgDelayTime" BO_ 1045 10;
BA_ "FrameRouting" BO_ 534 "FD1_CAN,0x216";
BA_ "FrameGatewayNetwork" BO_ 534 "FD1_CAN";
BA_ "FrameGatewayId" BO_ 534 534;
BA_ "GenMsgDelayTime" BO_ 534 10;
BA_ "FrameRouting" BO_ 532 "FD1_CAN,0x214";
BA_ "FrameGatewayNetwork" BO_ 532 "FD1_CAN";
BA_ "FrameGatewayId" BO_ 532 532;
BA_ "GenMsgDelayTime" BO_ 532 10;
BA_ "FrameRouting" BO_ 531 "FD1_CAN,0x213";
BA_ "FrameGatewayNetwork" BO_ 531 "FD1_CAN";
BA_ "FrameGatewayId" BO_ 531 531;
BA_ "GenMsgDelayTime" BO_ 531 10;
BA_ "FrameRouting" BO_ 535 "FD1_CAN,0x217";
BA_ "FrameGatewayNetwork" BO_ 535 "FD1_CAN";
BA_ "FrameGatewayId" BO_ 535 535;
BA_ "GenMsgDelayTime" BO_ 535 0;
BA_ "FrameRouting" BO_ 611 "FD1_CAN,0x263;";
BA_ "FrameGatewayNetwork" BO_ 611 "FD1_CAN";
BA_ "FrameGatewayId" BO_ 611 611;
BA_ "NetworkInitialization" BO_ 1409 0;
BA_ "GenMsgCycleTime" BO_ 1409 1000;
BA_ "GenMsgSendType" BO_ 1409 0;
BA_ "NmAsrMessage" BO_ 1409 1;
BA_ "GenMsgILSupport" BO_ 1409 0;
BA_ "FrameRouting" BO_ 90 "HS2_CAN,0x5A;";
BA_ "FrameGatewayNetwork" BO_ 90 "HS2_CAN";
BA_ "FrameGatewayId" BO_ 90 90;
BA_ "FrameRouting" BO_ 1109 "HS3_CAN,0x455;";
BA_ "FrameGatewayNetwork" BO_ 1109 "HS3_CAN";
BA_ "FrameGatewayId" BO_ 1109 1109;
BA_ "FrameRouting" BO_ 92 "FD1_CAN,0x5C;";
BA_ "FrameGatewayNetwork" BO_ 92 "FD1_CAN";
BA_ "FrameGatewayId" BO_ 92 92;
BA_ "FrameRouting" BO_ 359 "FD1_CAN,0x167;";
BA_ "FrameGatewayNetwork" BO_ 359 "FD1_CAN";
BA_ "FrameGatewayId" BO_ 359 359;
BA_ "FrameRouting" BO_ 358 "FD1_CAN,0x166;";
BA_ "FrameGatewayNetwork" BO_ 358 "FD1_CAN";
BA_ "FrameGatewayId" BO_ 358 358;
BA_ "GenMsgCycleTime" BO_ 1084 1000;
BA_ "GenMsgSendType" BO_ 1084 0;
BA_ "FrameRouting" BO_ 1086 "FD1_CAN,0x43E;";
BA_ "FrameGatewayNetwork" BO_ 1086 "FD1_CAN";
BA_ "FrameGatewayId" BO_ 1086 1086;
BA_ "GenMsgCycleTime" BO_ 1085 50;
BA_ "GenMsgSendType" BO_ 1085 0;
BA_ "GenMsgCycleTime" BO_ 891 100;
BA_ "GenMsgSendType" BO_ 891 0;
BA_ "FrameRouting" BO_ 603 "FD1_CAN,0x25B;";
BA_ "FrameGatewayNetwork" BO_ 603 "FD1_CAN";
BA_ "FrameGatewayId" BO_ 603 603;
BA_ "FrameRouting" BO_ 602 "FD1_CAN,0x25A;";
BA_ "FrameGatewayNetwork" BO_ 602 "FD1_CAN";
BA_ "FrameGatewayId" BO_ 602 602;
BA_ "GenMsgCycleTime" BO_ 587 100;
BA_ "GenMsgSendType" BO_ 587 0;
BA_ "FrameRouting" BO_ 1040 "FD1_CAN,0x410;";
BA_ "FrameGatewayNetwork" BO_ 1040 "FD1_CAN";
BA_ "FrameGatewayId" BO_ 1040 1040;
BA_ "GenMsgCycleTime" BO_ 1041 100;
BA_ "GenMsgSendType" BO_ 1041 0;
BA_ "NetworkInitialization" BO_ 1999 0;
BA_ "GenMsgDelayTime" BO_ 1999 0;
BA_ "GenMsgSendType" BO_ 1999 1;
BA_ "DiagResponse" BO_ 1999 1;
BA_ "GenMsgILSupport" BO_ 1999 0;
BA_ "NetworkInitialization" BO_ 1991 0;
BA_ "GenMsgDelayTime" BO_ 1991 0;
BA_ "GenMsgSendType" BO_ 1991 1;
BA_ "DiagRequest" BO_ 1991 1;
BA_ "GenMsgILSupport" BO_ 1991 0;
BA_ "NetworkInitialization" BO_ 2022 0;
BA_ "GenMsgDelayTime" BO_ 2022 0;
BA_ "GenMsgSendType" BO_ 2022 1;
BA_ "DiagRequest" BO_ 2022 1;
BA_ "GenMsgILSupport" BO_ 2022 0;
BA_ "FrameRouting" BO_ 1088 "FD1_CAN,0x440;";
BA_ "FrameGatewayNetwork" BO_ 1088 "FD1_CAN";
BA_ "FrameGatewayId" BO_ 1088 1088;
BA_ "FrameRouting" BO_ 871 "FD1_CAN,0x367;";
BA_ "FrameGatewayNetwork" BO_ 871 "FD1_CAN";
BA_ "FrameGatewayId" BO_ 871 871;
BA_ "FrameRouting" BO_ 869 "FD1_CAN,0x365;";
BA_ "FrameGatewayNetwork" BO_ 869 "FD1_CAN";
BA_ "FrameGatewayId" BO_ 869 869;
BA_ "FrameRouting" BO_ 870 "FD1_CAN,0x366;";
BA_ "FrameGatewayNetwork" BO_ 870 "FD1_CAN";
BA_ "FrameGatewayId" BO_ 870 870;
BA_ "FrameRouting" BO_ 1071 "FD1_CAN,0x42F;";
BA_ "FrameGatewayNetwork" BO_ 1071 "FD1_CAN";
BA_ "FrameGatewayId" BO_ 1071 1071;
BA_ "FrameRouting" BO_ 130 "FD1_CAN,0x82;";
BA_ "FrameGatewayNetwork" BO_ 130 "FD1_CAN";
BA_ "FrameGatewayId" BO_ 130 130;
BA_ "GenMsgDelayTime" BO_ 130 10;
BA_ "GenMsgCycleTime" BO_ 1076 100;
BA_ "GenMsgSendType" BO_ 1076 5;
BA_ "GenMsgCycleTime" BO_ 1072 100;
BA_ "GenMsgSendType" BO_ 1072 5;
BA_ "NetworkInitialization" BO_ 2002 0;
BA_ "GenMsgDelayTime" BO_ 2002 0;
BA_ "GenMsgSendType" BO_ 2002 1;
BA_ "DiagRequest" BO_ 2002 1;
BA_ "GenMsgILSupport" BO_ 2002 0;
BA_ "NetworkInitialization" BO_ 1438 0;
BA_ "GenMsgCycleTime" BO_ 1438 1000;
BA_ "GenMsgSendType" BO_ 1438 0;
BA_ "NmAsrMessage" BO_ 1438 1;
BA_ "GenMsgILSupport" BO_ 1438 0;
BA_ "GenMsgCycleTime" BO_ 1067 100;
BA_ "GenMsgSendType" BO_ 1067 0;
BA_ "GenMsgCycleTime" BO_ 588 100;
BA_ "GenMsgSendType" BO_ 588 0;
BA_ "GenMsgDelayTime" BO_ 122 0;
BA_ "GenMsgCycleTime" BO_ 122 10;
BA_ "GenMsgSendType" BO_ 122 0;
BA_ "NetworkInitialization" BO_ 1814 0;
BA_ "GenMsgDelayTime" BO_ 1814 0;
BA_ "GenMsgSendType" BO_ 1814 1;
BA_ "DiagRequest" BO_ 1814 1;
BA_ "GenMsgILSupport" BO_ 1814 0;
BA_ "NetworkInitialization" BO_ 1822 0;
BA_ "GenMsgDelayTime" BO_ 1822 0;
BA_ "GenMsgSendType" BO_ 1822 1;
BA_ "DiagResponse" BO_ 1822 1;
BA_ "GenMsgILSupport" BO_ 1822 0;
BA_ "FrameRouting" BO_ 806 "MS1_CAN,0x326;";
BA_ "FrameGatewayNetwork" BO_ 806 "MS1_CAN";
BA_ "FrameGatewayId" BO_ 806 806;
BA_ "GenMsgCycleTime" BO_ 578 40;
BA_ "GenMsgSendType" BO_ 578 0;
BA_ "FrameRouting" BO_ 514 "FD1_CAN,0x202;";
BA_ "FrameGatewayNetwork" BO_ 514 "FD1_CAN";
BA_ "FrameGatewayId" BO_ 514 514;
BA_ "FrameRouting" BO_ 1057 "FD1_CAN,0x421;";
BA_ "FrameGatewayNetwork" BO_ 1057 "FD1_CAN";
BA_ "FrameGatewayId" BO_ 1057 1057;
BA_ "FrameRouting" BO_ 1069 "FD1_CAN,0x42D;";
BA_ "FrameGatewayNetwork" BO_ 1069 "FD1_CAN";
BA_ "FrameGatewayId" BO_ 1069 1069;
BA_ "GenMsgCycleTime" BO_ 1037 1000;
BA_ "GenMsgSendType" BO_ 1037 0;
BA_ "FrameRouting" BO_ 878 "FD1_CAN,0x36E;";
BA_ "FrameGatewayNetwork" BO_ 878 "FD1_CAN";
BA_ "FrameGatewayId" BO_ 878 878;
BA_ "NetworkInitialization" BO_ 2010 0;
BA_ "GenMsgDelayTime" BO_ 2010 0;
BA_ "GenMsgSendType" BO_ 2010 1;
BA_ "DiagResponse" BO_ 2010 1;
BA_ "GenMsgILSupport" BO_ 2010 0;
BA_ "NetworkInitialization" BO_ 1522 0;
BA_ "GenMsgCycleTime" BO_ 1522 1000;
BA_ "GenMsgSendType" BO_ 1522 0;
BA_ "NmAsrMessage" BO_ 1522 1;
BA_ "GenMsgILSupport" BO_ 1522 0;
BA_ "NetworkInitialization" BO_ 1442 0;
BA_ "GenMsgCycleTime" BO_ 1442 1000;
BA_ "GenMsgSendType" BO_ 1442 0;
BA_ "NmAsrMessage" BO_ 1442 1;
BA_ "GenMsgILSupport" BO_ 1442 0;
BA_ "FrameRouting" BO_ 1200 "FD1_CAN,0x4B0;";
BA_ "FrameGatewayNetwork" BO_ 1200 "FD1_CAN";
BA_ "FrameGatewayId" BO_ 1200 1200;
BA_ "GenMsgDelayTime" BO_ 1200 10;
BA_ "NetworkInitialization" BO_ 2015 0;
BA_ "GenMsgDelayTime" BO_ 2015 0;
BA_ "GenMsgSendType" BO_ 2015 1;
BA_ "DiagState" BO_ 2015 1;
BA_ "GenMsgILSupport" BO_ 2015 0;
BA_ "FrameRouting" BO_ 376 "FD1_CAN,0x178;";
BA_ "FrameGatewayNetwork" BO_ 376 "FD1_CAN";
BA_ "FrameGatewayId" BO_ 376 376;
BA_ "GenSigStartValue" SG_ 125 VehRolComp_W_Actl 4094;
BA_ "GenSigStartValueInteger" SG_ 125 VehRolComp_W_Actl 4094;
BA_ "GenSigStartValue" SG_ 125 VehVertComp_A_Actl 1022;
BA_ "GenSigStartValueInteger" SG_ 125 VehVertComp_A_Actl 1022;
BA_ "MetaData" SG_ 125 BrkTotTqRqArb_No_Cs 1;
BA_ "MetaData" SG_ 125 BrkTotTqRqArb_No_Cnt 1;
BA_ "GenSigStartValue" SG_ 119 VehLongComp_A_Actl 1022;
BA_ "GenSigStartValueInteger" SG_ 119 VehLongComp_A_Actl 1022;
BA_ "GenSigStartValue" SG_ 119 VehLatComp_A_Actl 1022;
BA_ "GenSigStartValueInteger" SG_ 119 VehLatComp_A_Actl 1022;
BA_ "GenSigStartValue" SG_ 119 VehYawComp_W_Actl 4094;
BA_ "GenSigStartValueInteger" SG_ 119 VehYawComp_W_Actl 4094;
BA_ "U_U55X_MY2022_Rx" SG_ 119 VehOverGnd_V_Est 1;
BA_ "GenSigStartValue" SG_ 1045 VehStab_D_Stat 14;
BA_ "GenSigStartValueInteger" SG_ 1045 VehStab_D_Stat 14;
BA_ "U_CD764_MY2022_Rx" SG_ 1045 BrkFluidLvl_D_Stat 1;
BA_ "U_U55X_MY2022_Rx" SG_ 1045 BrkFluidLvl_D_Stat 1;
BA_ "U_CD542_MY2021_Rx" SG_ 1045 BrkFluidLvl_D_Stat 1;
BA_ "U_T6_MCA_MY2020_Rx" SG_ 1045 BrkFluidLvl_D_Stat 1;
BA_ "U_P702_MY2021_Rx" SG_ 1045 BrkFluidLvl_D_Stat 1;
BA_ "U_CX727_MY2021_Rx" SG_ 1045 BrkFluidLvl_D_Stat 1;
BA_ "GenSigStartValue" SG_ 1045 VehYawNonLin_W_Rq 4094;
BA_ "GenSigStartValueInteger" SG_ 1045 VehYawNonLin_W_Rq 4094;
BA_ "GenSigStartValue" SG_ 1045 VehYawLin_W_Rq 4094;
BA_ "GenSigStartValueInteger" SG_ 1045 VehYawLin_W_Rq 4094;
BA_ "U_CD764_MY2022_Rx" SG_ 1045 VehVActlBrk_No_Cs 1;
BA_ "U_U55X_MY2022_Rx" SG_ 1045 VehVActlBrk_No_Cs 1;
BA_ "U_CD542_MY2021_Rx" SG_ 1045 VehVActlBrk_No_Cs 1;
BA_ "U_T6_MCA_MY2020_Rx" SG_ 1045 VehVActlBrk_No_Cs 1;
BA_ "U_P702_MY2021_Rx" SG_ 1045 VehVActlBrk_No_Cs 1;
BA_ "U_CX727_MY2021_Rx" SG_ 1045 VehVActlBrk_No_Cs 1;
BA_ "MetaData" SG_ 1045 VehVActlBrk_No_Cs 1;
BA_ "U_CD764_MY2022_Rx" SG_ 1045 Veh_V_ActlBrk 1;
BA_ "U_U55X_MY2022_Rx" SG_ 1045 Veh_V_ActlBrk 1;
BA_ "U_CD542_MY2021_Rx" SG_ 1045 Veh_V_ActlBrk 1;
BA_ "U_T6_MCA_MY2020_Rx" SG_ 1045 Veh_V_ActlBrk 1;
BA_ "U_P702_MY2021_Rx" SG_ 1045 Veh_V_ActlBrk 1;
BA_ "U_CX727_MY2021_Rx" SG_ 1045 Veh_V_ActlBrk 1;
BA_ "U_CD764_MY2022_Rx" SG_ 1045 VehVActlBrk_No_Cnt 1;
BA_ "U_U55X_MY2022_Rx" SG_ 1045 VehVActlBrk_No_Cnt 1;
BA_ "U_CD542_MY2021_Rx" SG_ 1045 VehVActlBrk_No_Cnt 1;
BA_ "U_T6_MCA_MY2020_Rx" SG_ 1045 VehVActlBrk_No_Cnt 1;
BA_ "U_P702_MY2021_Rx" SG_ 1045 VehVActlBrk_No_Cnt 1;
BA_ "U_CX727_MY2021_Rx" SG_ 1045 VehVActlBrk_No_Cnt 1;
BA_ "MetaData" SG_ 1045 VehVActlBrk_No_Cnt 1;
BA_ "U_CD764_MY2022_Rx" SG_ 1045 VehVActlBrk_D_Qf 1;
BA_ "U_U55X_MY2022_Rx" SG_ 1045 VehVActlBrk_D_Qf 1;
BA_ "U_CD542_MY2021_Rx" SG_ 1045 VehVActlBrk_D_Qf 1;
BA_ "U_T6_MCA_MY2020_Rx" SG_ 1045 VehVActlBrk_D_Qf 1;
BA_ "U_P702_MY2021_Rx" SG_ 1045 VehVActlBrk_D_Qf 1;
BA_ "U_CX727_MY2021_Rx" SG_ 1045 VehVActlBrk_D_Qf 1;
BA_ "MetaData" SG_ 1045 VehVActlBrk_D_Qf 1;
BA_ "U_CD764_MY2022_Rx" SG_ 534 WhlRotatRr_No_Cnt 1;
BA_ "U_U55X_MY2022_Rx" SG_ 534 WhlRotatRr_No_Cnt 1;
BA_ "U_CD542_MY2021_Rx" SG_ 534 WhlRotatRr_No_Cnt 1;
BA_ "U_T6_MCA_MY2020_Rx" SG_ 534 WhlRotatRr_No_Cnt 1;
BA_ "U_P702_MY2021_Rx" SG_ 534 WhlRotatRr_No_Cnt 1;
BA_ "U_CX727_MY2021_Rx" SG_ 534 WhlRotatRr_No_Cnt 1;
BA_ "U_CD764_MY2022_Rx" SG_ 534 WhlRotatRl_No_Cnt 1;
BA_ "U_U55X_MY2022_Rx" SG_ 534 WhlRotatRl_No_Cnt 1;
BA_ "U_CD542_MY2021_Rx" SG_ 534 WhlRotatRl_No_Cnt 1;
BA_ "U_T6_MCA_MY2020_Rx" SG_ 534 WhlRotatRl_No_Cnt 1;
BA_ "U_P702_MY2021_Rx" SG_ 534 WhlRotatRl_No_Cnt 1;
BA_ "U_CX727_MY2021_Rx" SG_ 534 WhlRotatRl_No_Cnt 1;
BA_ "U_CD764_MY2022_Rx" SG_ 534 WhlRotatFr_No_Cnt 1;
BA_ "U_U55X_MY2022_Rx" SG_ 534 WhlRotatFr_No_Cnt 1;
BA_ "U_CD542_MY2021_Rx" SG_ 534 WhlRotatFr_No_Cnt 1;
BA_ "U_T6_MCA_MY2020_Rx" SG_ 534 WhlRotatFr_No_Cnt 1;
BA_ "U_P702_MY2021_Rx" SG_ 534 WhlRotatFr_No_Cnt 1;
BA_ "U_CX727_MY2021_Rx" SG_ 534 WhlRotatFr_No_Cnt 1;
BA_ "U_CD764_MY2022_Rx" SG_ 534 WhlRotatFl_No_Cnt 1;
BA_ "U_U55X_MY2022_Rx" SG_ 534 WhlRotatFl_No_Cnt 1;
BA_ "U_CD542_MY2021_Rx" SG_ 534 WhlRotatFl_No_Cnt 1;
BA_ "U_T6_MCA_MY2020_Rx" SG_ 534 WhlRotatFl_No_Cnt 1;
BA_ "U_P702_MY2021_Rx" SG_ 534 WhlRotatFl_No_Cnt 1;
BA_ "U_CX727_MY2021_Rx" SG_ 534 WhlRotatFl_No_Cnt 1;
BA_ "ContentDependant" SG_ 534 BrkObdData_No_Actl 1;
BA_ "ContentDependant" SG_ 534 BrkObdIndex_No_Actl 1;
BA_ "MetaData" SG_ 532 PrplWhlTqRqMn_No_Cs 1;
BA_ "MetaData" SG_ 532 PrplWhlTqRqMn_No_Cnt 1;
BA_ "GenSigStartValue" SG_ 531 VehStop_D_Stat 2;
BA_ "GenSigStartValueInteger" SG_ 531 VehStop_D_Stat 2;
BA_ "GenSigStartValueInteger" SG_ 531 VehLongOvrGnd_A_Est 511;
BA_ "WakeupSignal" SG_ 531 PrkBrkYwLamp_D_Rq 1;
BA_ "WakeupSignal" SG_ 531 PrkBrkRedLamp_D_Rq 1;
BA_ "WakeupSignal" SG_ 531 PrkBrkMsgTxt_D_Rq 1;
BA_ "U_CD764_MY2022_Rx" SG_ 531 PrkBrkStatus 1;
BA_ "U_U55X_MY2022_Rx" SG_ 531 PrkBrkStatus 1;
BA_ "U_CD542_MY2021_Rx" SG_ 531 PrkBrkStatus 1;
BA_ "U_T6_MCA_MY2020_Rx" SG_ 531 PrkBrkStatus 1;
BA_ "U_P702_MY2021_Rx" SG_ 531 PrkBrkStatus 1;
BA_ "U_CX727_MY2021_Rx" SG_ 531 PrkBrkStatus 1;
BA_ "GenSigStartValue" SG_ 531 PrkBrkStatus 7;
BA_ "GenSigStartValueInteger" SG_ 531 PrkBrkStatus 7;
BA_ "U_CX727_MY2021_Rx" SG_ 535 WhlRr_W_Meas 1;
BA_ "U_U55X_MY2022_Rx" SG_ 535 WhlRr_W_Meas 1;
BA_ "U_CX727_MY2021_Rx" SG_ 535 WhlRl_W_Meas 1;
BA_ "U_U55X_MY2022_Rx" SG_ 535 WhlRl_W_Meas 1;
BA_ "U_CX727_MY2021_Rx" SG_ 535 WhlFr_W_Meas 1;
BA_ "U_U55X_MY2022_Rx" SG_ 535 WhlFr_W_Meas 1;
BA_ "U_CX727_MY2021_Rx" SG_ 535 WhlFl_W_Meas 1;
BA_ "U_U55X_MY2022_Rx" SG_ 535 WhlFl_W_Meas 1;
BA_ "ContentDependant" SG_ 611 AwdStat_D_RqDsply 1;
BA_ "ContentDependant" SG_ 611 AwdSrvcRqd_B_Rq 1;
BA_ "U_U55X_MY2022_Rx" SG_ 611 AwdLck_Tq_Rq 1;
BA_ "ContentDependant" SG_ 611 AwdLck_Tq_Rq 1;
BA_ "GenSigStartValue" SG_ 611 TrnAout_Tq_RqMx 8191;
BA_ "GenSigStartValueInteger" SG_ 611 TrnAout_Tq_RqMx 8191;
BA_ "U_U55X_MY2022_Rx" SG_ 611 AwdRnge_D_Actl 1;
BA_ "GenSigStartValue" SG_ 611 AwdRnge_D_Actl 7;
BA_ "GenSigStartValueInteger" SG_ 611 AwdRnge_D_Actl 7;
BA_ "U_CD764_MY2022_Tx" SG_ 1409 BCM_GWOnBoardTester 1;
BA_ "U_U55X_MY2022_Tx" SG_ 1409 BCM_GWOnBoardTester 1;
BA_ "U_CD542_MY2021_Tx" SG_ 1409 BCM_GWOnBoardTester 1;
BA_ "U_T6_MCA_MY2020_Tx" SG_ 1409 BCM_GWOnBoardTester 1;
BA_ "U_P702_MY2021_Tx" SG_ 1409 BCM_GWOnBoardTester 1;
BA_ "U_CX727_MY2021_Tx" SG_ 1409 BCM_GWOnBoardTester 1;
BA_ "U_CX727_MY2021_Rx" SG_ 1409 BCM_GWOnBoardTester 1;
BA_ "GenSigStartValue" SG_ 1409 BCM_GWOnBoardTester 255;
BA_ "ContentDependant" SG_ 1409 BCM_GWOnBoardTester 1;
BA_ "GenSigStartValueInteger" SG_ 1409 BCM_GWOnBoardTester 255;
BA_ "U_CD764_MY2022_Tx" SG_ 1409 BCM_GWNMProxy 1;
BA_ "U_U55X_MY2022_Tx" SG_ 1409 BCM_GWNMProxy 1;
BA_ "U_CD542_MY2021_Tx" SG_ 1409 BCM_GWNMProxy 1;
BA_ "U_T6_MCA_MY2020_Tx" SG_ 1409 BCM_GWNMProxy 1;
BA_ "U_P702_MY2021_Tx" SG_ 1409 BCM_GWNMProxy 1;
BA_ "U_CX727_MY2021_Tx" SG_ 1409 BCM_GWNMProxy 1;
BA_ "U_CX727_MY2021_Rx" SG_ 1409 BCM_GWNMProxy 1;
BA_ "GenSigStartValue" SG_ 1409 BCM_GWNMProxy 255;
BA_ "ContentDependant" SG_ 1409 BCM_GWNMProxy 1;
BA_ "GenSigStartValueInteger" SG_ 1409 BCM_GWNMProxy 255;
BA_ "U_CD764_MY2022_Tx" SG_ 1409 BCM_AutoSarNMReserved4 1;
BA_ "U_U55X_MY2022_Tx" SG_ 1409 BCM_AutoSarNMReserved4 1;
BA_ "U_CD542_MY2021_Tx" SG_ 1409 BCM_AutoSarNMReserved4 1;
BA_ "U_T6_MCA_MY2020_Tx" SG_ 1409 BCM_AutoSarNMReserved4 1;
BA_ "U_P702_MY2021_Tx" SG_ 1409 BCM_AutoSarNMReserved4 1;
BA_ "U_CX727_MY2021_Tx" SG_ 1409 BCM_AutoSarNMReserved4 1;
BA_ "U_CX727_MY2021_Rx" SG_ 1409 BCM_AutoSarNMReserved4 1;
BA_ "GenSigStartValue" SG_ 1409 BCM_AutoSarNMReserved4 255;
BA_ "ContentDependant" SG_ 1409 BCM_AutoSarNMReserved4 1;
BA_ "GenSigStartValueInteger" SG_ 1409 BCM_AutoSarNMReserved4 255;
BA_ "U_CD764_MY2022_Tx" SG_ 1409 BCM_AutoSarNMReserved3 1;
BA_ "U_U55X_MY2022_Tx" SG_ 1409 BCM_AutoSarNMReserved3 1;
BA_ "U_CD542_MY2021_Tx" SG_ 1409 BCM_AutoSarNMReserved3 1;
BA_ "U_T6_MCA_MY2020_Tx" SG_ 1409 BCM_AutoSarNMReserved3 1;
BA_ "U_P702_MY2021_Tx" SG_ 1409 BCM_AutoSarNMReserved3 1;
BA_ "U_CX727_MY2021_Tx" SG_ 1409 BCM_AutoSarNMReserved3 1;
BA_ "U_CX727_MY2021_Rx" SG_ 1409 BCM_AutoSarNMReserved3 1;
BA_ "GenSigStartValue" SG_ 1409 BCM_AutoSarNMReserved3 255;
BA_ "ContentDependant" SG_ 1409 BCM_AutoSarNMReserved3 1;
BA_ "GenSigStartValueInteger" SG_ 1409 BCM_AutoSarNMReserved3 255;
BA_ "U_CD764_MY2022_Tx" SG_ 1409 BCM_AutoSarNMReserved2 1;
BA_ "U_U55X_MY2022_Tx" SG_ 1409 BCM_AutoSarNMReserved2 1;
BA_ "U_CD542_MY2021_Tx" SG_ 1409 BCM_AutoSarNMReserved2 1;
BA_ "U_T6_MCA_MY2020_Tx" SG_ 1409 BCM_AutoSarNMReserved2 1;
BA_ "U_P702_MY2021_Tx" SG_ 1409 BCM_AutoSarNMReserved2 1;
BA_ "U_CX727_MY2021_Tx" SG_ 1409 BCM_AutoSarNMReserved2 1;
BA_ "U_CX727_MY2021_Rx" SG_ 1409 BCM_AutoSarNMReserved2 1;
BA_ "GenSigStartValue" SG_ 1409 BCM_AutoSarNMReserved2 255;
BA_ "ContentDependant" SG_ 1409 BCM_AutoSarNMReserved2 1;
BA_ "GenSigStartValueInteger" SG_ 1409 BCM_AutoSarNMReserved2 255;
BA_ "U_CD764_MY2022_Tx" SG_ 1409 BCM_AutoSarNMReserved1 1;
BA_ "U_U55X_MY2022_Tx" SG_ 1409 BCM_AutoSarNMReserved1 1;
BA_ "U_CD542_MY2021_Tx" SG_ 1409 BCM_AutoSarNMReserved1 1;
BA_ "U_T6_MCA_MY2020_Tx" SG_ 1409 BCM_AutoSarNMReserved1 1;
BA_ "U_P702_MY2021_Tx" SG_ 1409 BCM_AutoSarNMReserved1 1;
BA_ "U_CX727_MY2021_Tx" SG_ 1409 BCM_AutoSarNMReserved1 1;
BA_ "U_CX727_MY2021_Rx" SG_ 1409 BCM_AutoSarNMReserved1 1;
BA_ "GenSigStartValue" SG_ 1409 BCM_AutoSarNMReserved1 255;
BA_ "ContentDependant" SG_ 1409 BCM_AutoSarNMReserved1 1;
BA_ "GenSigStartValueInteger" SG_ 1409 BCM_AutoSarNMReserved1 255;
BA_ "U_CD764_MY2022_Tx" SG_ 1409 BCM_AutoSarNMNodeId 1;
BA_ "U_U55X_MY2022_Tx" SG_ 1409 BCM_AutoSarNMNodeId 1;
BA_ "U_CD542_MY2021_Tx" SG_ 1409 BCM_AutoSarNMNodeId 1;
BA_ "U_T6_MCA_MY2020_Tx" SG_ 1409 BCM_AutoSarNMNodeId 1;
BA_ "U_P702_MY2021_Tx" SG_ 1409 BCM_AutoSarNMNodeId 1;
BA_ "U_CX727_MY2021_Tx" SG_ 1409 BCM_AutoSarNMNodeId 1;
BA_ "U_CX727_MY2021_Rx" SG_ 1409 BCM_AutoSarNMNodeId 1;
BA_ "GenSigStartValue" SG_ 1409 BCM_AutoSarNMNodeId 129;
BA_ "ContentDependant" SG_ 1409 BCM_AutoSarNMNodeId 1;
BA_ "GenSigStartValueInteger" SG_ 1409 BCM_AutoSarNMNodeId 81;
BA_ "U_CD764_MY2022_Tx" SG_ 1409 BCM_AutoSarNMControl 1;
BA_ "U_U55X_MY2022_Tx" SG_ 1409 BCM_AutoSarNMControl 1;
BA_ "U_CD542_MY2021_Tx" SG_ 1409 BCM_AutoSarNMControl 1;
BA_ "U_T6_MCA_MY2020_Tx" SG_ 1409 BCM_AutoSarNMControl 1;
BA_ "U_P702_MY2021_Tx" SG_ 1409 BCM_AutoSarNMControl 1;
BA_ "U_CX727_MY2021_Tx" SG_ 1409 BCM_AutoSarNMControl 1;
BA_ "U_CX727_MY2021_Rx" SG_ 1409 BCM_AutoSarNMControl 1;
BA_ "ContentDependant" SG_ 1409 BCM_AutoSarNMControl 1;
BA_ "ContentDependant" SG_ 90 TrnGsmNtmState_D_Actl 1;
BA_ "GenSigStartValue" SG_ 90 DrQltyDrv_D_StatGsm 6;
BA_ "ContentDependant" SG_ 90 DrQltyDrv_D_StatGsm 1;
BA_ "GenSigStartValueInteger" SG_ 90 DrQltyDrv_D_StatGsm 6;
BA_ "ContentDependant" SG_ 90 TrnBtsiOvrrd_B_Stat 1;
BA_ "GenSigStartValue" SG_ 90 TrnRng_D_RqGsm 14;
BA_ "GenSigStartValueInteger" SG_ 90 TrnRng_D_RqGsm 14;
BA_ "ContentDependant" SG_ 90 TrnValidGearRq_D_Stat 1;
BA_ "ContentDependant" SG_ 90 TrnGearRqCnt_B_Actl 1;
BA_ "ContentDependant" SG_ 90 TrnGearButtn_U_Actl 1;
BA_ "WakeupSignal" SG_ 90 TrnGearButtn_U_Actl 1;
BA_ "ContentDependant" SG_ 90 TrnGearButtn_B_ActlR2 1;
BA_ "WakeupSignal" SG_ 90 TrnGearButtn_B_ActlR2 1;
BA_ "ContentDependant" SG_ 90 TrnGearButtn_B_ActlR1 1;
BA_ "WakeupSignal" SG_ 90 TrnGearButtn_B_ActlR1 1;
BA_ "ContentDependant" SG_ 90 TrnGearButtn_B_ActlR0 1;
BA_ "WakeupSignal" SG_ 90 TrnGearButtn_B_ActlR0 1;
BA_ "ContentDependant" SG_ 90 TrnGearButtn_B_ActlP2 1;
BA_ "WakeupSignal" SG_ 90 TrnGearButtn_B_ActlP2 1;
BA_ "ContentDependant" SG_ 90 TrnGearButtn_B_ActlP1 1;
BA_ "WakeupSignal" SG_ 90 TrnGearButtn_B_ActlP1 1;
BA_ "ContentDependant" SG_ 90 TrnGearButtn_B_ActlP0 1;
BA_ "WakeupSignal" SG_ 90 TrnGearButtn_B_ActlP0 1;
BA_ "ContentDependant" SG_ 90 TrnGearButtn_B_ActlN2 1;
BA_ "WakeupSignal" SG_ 90 TrnGearButtn_B_ActlN2 1;
BA_ "ContentDependant" SG_ 90 TrnGearButtn_B_ActlN1 1;
BA_ "WakeupSignal" SG_ 90 TrnGearButtn_B_ActlN1 1;
BA_ "ContentDependant" SG_ 90 TrnGearButtn_B_ActlN0 1;
BA_ "WakeupSignal" SG_ 90 TrnGearButtn_B_ActlN0 1;
BA_ "ContentDependant" SG_ 90 TrnGearButtn_B_ActlM2 1;
BA_ "WakeupSignal" SG_ 90 TrnGearButtn_B_ActlM2 1;
BA_ "ContentDependant" SG_ 90 TrnGearButtn_B_ActlM1 1;
BA_ "WakeupSignal" SG_ 90 TrnGearButtn_B_ActlM1 1;
BA_ "ContentDependant" SG_ 90 TrnGearButtn_B_ActlM0 1;
BA_ "WakeupSignal" SG_ 90 TrnGearButtn_B_ActlM0 1;
BA_ "ContentDependant" SG_ 90 TrnGearButtn_B_ActlD2 1;
BA_ "WakeupSignal" SG_ 90 TrnGearButtn_B_ActlD2 1;
BA_ "ContentDependant" SG_ 90 TrnGearButtn_B_ActlD1 1;
BA_ "WakeupSignal" SG_ 90 TrnGearButtn_B_ActlD1 1;
BA_ "ContentDependant" SG_ 90 TrnGearButtn_B_ActlD0 1;
BA_ "WakeupSignal" SG_ 90 TrnGearButtn_B_ActlD0 1;
BA_ "MetaData" SG_ 90 TrnGear_No_Cs 1;
BA_ "ContentDependant" SG_ 90 TrnGear_No_Cs 1;
BA_ "MetaData" SG_ 90 TrnGear_No_Cnt 1;
BA_ "ContentDependant" SG_ 90 TrnGear_No_Cnt 1;
BA_ "U_CD764_MY2022_Rx" SG_ 90 TrnGear_D_RqDrv 1;
BA_ "U_U55X_MY2022_Rx" SG_ 90 TrnGear_D_RqDrv 1;
BA_ "U_CD542_MY2021_Rx" SG_ 90 TrnGear_D_RqDrv 1;
BA_ "U_T6_MCA_MY2020_Rx" SG_ 90 TrnGear_D_RqDrv 1;
BA_ "U_P702_MY2021_Rx" SG_ 90 TrnGear_D_RqDrv 1;
BA_ "U_CX727_MY2021_Rx" SG_ 90 TrnGear_D_RqDrv 1;
BA_ "ContentDependant" SG_ 90 TrnGear_D_RqDrv 1;
BA_ "WakeupSignal" SG_ 90 TrnGear_D_RqDrv 1;
BA_ "ContentDependant" SG_ 90 BrkSwtchPos_B_ActlGsm 1;
BA_ "U_CD764_MY2022_Rx" SG_ 1109 eCallConfirmation 1;
BA_ "U_U55X_MY2022_Rx" SG_ 1109 eCallConfirmation 1;
BA_ "U_CD542_MY2021_Rx" SG_ 1109 eCallConfirmation 1;
BA_ "U_T6_MCA_MY2020_Rx" SG_ 1109 eCallConfirmation 1;
BA_ "U_P702_MY2021_Rx" SG_ 1109 eCallConfirmation 1;
BA_ "U_CX727_MY2021_Rx" SG_ 1109 eCallConfirmation 1;
BA_ "ContentDependant" SG_ 92 TrnGearMsgTxt2_D_Rq 1;
BA_ "GenSigSendType" SG_ 92 TrnLvrV_D_Rq 3;
BA_ "GenSigStartValue" SG_ 92 TrnLvrV_D_Rq 1;
BA_ "GenSigStartValueInteger" SG_ 92 TrnLvrV_D_Rq 1;
BA_ "GenSigSendType" SG_ 92 TrnSbwSysHlth_D_Actl 3;
BA_ "GenSigStartValue" SG_ 92 TrnSbwSysHlth_D_Actl 1;
BA_ "ContentDependant" SG_ 92 TrnSbwSysHlth_D_Actl 1;
BA_ "GenSigStartValueInteger" SG_ 92 TrnSbwSysHlth_D_Actl 1;
BA_ "GenSigSendType" SG_ 92 TrnGearNtmAllow_B_Stat 3;
BA_ "ContentDependant" SG_ 92 TrnGearNtmAllow_B_Stat 1;
BA_ "GenSigStartValue" SG_ 92 TrnDtpCmd_D_Actl 1;
BA_ "ContentDependant" SG_ 92 TrnDtpCmd_D_Actl 1;
BA_ "GenSigStartValueInteger" SG_ 92 TrnDtpCmd_D_Actl 1;
BA_ "WakeupSignal" SG_ 92 TrnDtpCmd_D_Actl 1;
BA_ "GenSigSendType" SG_ 92 GearSelLck_D_Rq 3;
BA_ "MetaData" SG_ 92 TrnGearCmd_No_Cs 1;
BA_ "ContentDependant" SG_ 92 TrnGearCmd_No_Cs 1;
BA_ "GenSigSendType" SG_ 92 TrnValidGear_D_Cnfm 3;
BA_ "ContentDependant" SG_ 92 TrnValidGear_D_Cnfm 1;
BA_ "GenSigSendType" SG_ 92 TrnNtrlTowCmd_D_Actl 3;
BA_ "ContentDependant" SG_ 92 TrnNtrlTowCmd_D_Actl 1;
BA_ "ContentDependant" SG_ 92 TrnGearCmd_Pc_ActlPt 1;
BA_ "U_CX727_MY2021_Rx" SG_ 92 TrnGear_D_RqPt 1;
BA_ "GenSigSendType" SG_ 92 TrnGear_D_RqPt 3;
BA_ "ContentDependant" SG_ 92 TrnGear_D_RqPt 1;
BA_ "GenSigSendType" SG_ 92 TrnCmdState_B_Actl 3;
BA_ "ContentDependant" SG_ 92 TrnCmdState_B_Actl 1;
BA_ "GenSigSendType" SG_ 92 TrnCmdCnt_B_Actl 3;
BA_ "ContentDependant" SG_ 92 TrnCmdCnt_B_Actl 1;
BA_ "GenSigSendType" SG_ 92 PrkBrkActv_D_RqTrnGear 3;
BA_ "GenSigStartValue" SG_ 92 PrkBrkActv_D_RqTrnGear 1;
BA_ "ContentDependant" SG_ 92 PrkBrkActv_D_RqTrnGear 1;
BA_ "GenSigStartValueInteger" SG_ 92 PrkBrkActv_D_RqTrnGear 1;
BA_ "GenSigSendType" SG_ 92 TrnGearMsgTxt_D_Rq 3;
BA_ "ContentDependant" SG_ 92 TrnGearMsgTxt_D_Rq 1;
BA_ "MetaData" SG_ 92 TrnGearCmd_No_Cnt 1;
BA_ "ContentDependant" SG_ 92 TrnGearCmd_No_Cnt 1;
BA_ "GenSigStartValueInteger" SG_ 359 PrplWhlRgenMn_Tq_Actl 4095;
BA_ "ContentDependant" SG_ 359 TrnAin_Tq_Actl 1;
BA_ "U_U55X_MY2022_Rx" SG_ 359 PrplWhlTot2_Tq_Actl 1;
BA_ "U_CD764_MY2022_Rx" SG_ 359 PwPckTq_D_Stat 1;
BA_ "U_U55X_MY2022_Rx" SG_ 359 PwPckTq_D_Stat 1;
BA_ "U_T6_MCA_MY2020_Rx" SG_ 359 PwPckTq_D_Stat 1;
BA_ "U_CD542_MY2021_Rx" SG_ 359 PwPckTq_D_Stat 1;
BA_ "U_P702_MY2021_Rx" SG_ 359 PwPckTq_D_Stat 1;
BA_ "U_CX727_MY2021_Rx" SG_ 359 PwPckTq_D_Stat 1;
BA_ "U_CD764_MY2022_Rx" SG_ 359 Eng_D_Stat 1;
BA_ "U_U55X_MY2022_Rx" SG_ 359 Eng_D_Stat 1;
BA_ "U_CD542_MY2021_Rx" SG_ 359 Eng_D_Stat 1;
BA_ "U_T6_MCA_MY2020_Rx" SG_ 359 Eng_D_Stat 1;
BA_ "U_P702_MY2021_Rx" SG_ 359 Eng_D_Stat 1;
BA_ "U_CX727_MY2021_Rx" SG_ 359 Eng_D_Stat 1;
BA_ "U_CD764_MY2022_Rx" SG_ 359 PlgActvArb_B_Actl 1;
BA_ "U_U55X_MY2022_Rx" SG_ 359 PlgActvArb_B_Actl 1;
BA_ "U_CD542_MY2021_Rx" SG_ 359 PlgActvArb_B_Actl 1;
BA_ "U_T6_MCA_MY2020_Rx" SG_ 359 PlgActvArb_B_Actl 1;
BA_ "U_P702_MY2021_Rx" SG_ 359 PlgActvArb_B_Actl 1;
BA_ "U_CX727_MY2021_Rx" SG_ 359 PlgActvArb_B_Actl 1;
BA_ "GenSigStartValue" SG_ 359 PlgActvArb_B_Actl 1;
BA_ "ContentDependant" SG_ 359 PlgActvArb_B_Actl 1;
BA_ "GenSigStartValueInteger" SG_ 359 PlgActvArb_B_Actl 1;
BA_ "U_CD764_MY2022_Rx" SG_ 359 ElPw_D_Stat 1;
BA_ "U_U55X_MY2022_Rx" SG_ 359 ElPw_D_Stat 1;
BA_ "U_CD542_MY2021_Rx" SG_ 359 ElPw_D_Stat 1;
BA_ "U_T6_MCA_MY2020_Rx" SG_ 359 ElPw_D_Stat 1;
BA_ "U_P702_MY2021_Rx" SG_ 359 ElPw_D_Stat 1;
BA_ "U_CX727_MY2021_Rx" SG_ 359 ElPw_D_Stat 1;
BA_ "MetaData" SG_ 359 TrnAinTq_D_Qf 1;
BA_ "ContentDependant" SG_ 359 TrnAinTq_D_Qf 1;
BA_ "U_CD764_MY2022_Rx" SG_ 358 StopStrtDrvMde_D_Indic 1;
BA_ "U_U55X_MY2022_Rx" SG_ 358 StopStrtDrvMde_D_Indic 1;
BA_ "U_CD542_MY2021_Rx" SG_ 358 StopStrtDrvMde_D_Indic 1;
BA_ "U_T6_MCA_MY2020_Rx" SG_ 358 StopStrtDrvMde_D_Indic 1;
BA_ "U_P702_MY2021_Rx" SG_ 358 StopStrtDrvMde_D_Indic 1;
BA_ "U_CX727_MY2021_Rx" SG_ 358 StopStrtDrvMde_D_Indic 1;
BA_ "ContentDependant" SG_ 358 HiElPwInhbt_B_Stat 1;
BA_ "U_CD764_MY2022_Rx" SG_ 358 AutoStopPtDelta_I_Est 1;
BA_ "U_U55X_MY2022_Rx" SG_ 358 AutoStopPtDelta_I_Est 1;
BA_ "U_CD542_MY2021_Rx" SG_ 358 AutoStopPtDelta_I_Est 1;
BA_ "U_T6_MCA_MY2020_Rx" SG_ 358 AutoStopPtDelta_I_Est 1;
BA_ "U_P702_MY2021_Rx" SG_ 358 AutoStopPtDelta_I_Est 1;
BA_ "U_CX727_MY2021_Rx" SG_ 358 AutoStopPtDelta_I_Est 1;
BA_ "ContentDependant" SG_ 358 AutoStopPtDelta_I_Est 1;
BA_ "GenSigStartValueInteger" SG_ 358 AutoStopPtDelta_I_Est 127;
BA_ "U_CD764_MY2022_Tx" SG_ 1084 BattULoChrg_URate_RqMx 1;
BA_ "U_U55X_MY2022_Tx" SG_ 1084 BattULoChrg_URate_RqMx 1;
BA_ "U_CD542_MY2021_Tx" SG_ 1084 BattULoChrg_URate_RqMx 1;
BA_ "U_T6_MCA_MY2020_Tx" SG_ 1084 BattULoChrg_URate_RqMx 1;
BA_ "U_P702_MY2021_Tx" SG_ 1084 BattULoChrg_URate_RqMx 1;
BA_ "U_CX727_MY2021_Tx" SG_ 1084 BattULoChrg_URate_RqMx 1;
BA_ "GenSigStartValue" SG_ 1084 BattULoChrg_URate_RqMx 5;
BA_ "GenSigStartValueInteger" SG_ 1084 BattULoChrg_URate_RqMx 5;
BA_ "U_CD764_MY2022_Tx" SG_ 1084 BattULoChrg_U_RqMx 1;
BA_ "U_U55X_MY2022_Tx" SG_ 1084 BattULoChrg_U_RqMx 1;
BA_ "U_CD542_MY2021_Tx" SG_ 1084 BattULoChrg_U_RqMx 1;
BA_ "U_T6_MCA_MY2020_Tx" SG_ 1084 BattULoChrg_U_RqMx 1;
BA_ "U_P702_MY2021_Tx" SG_ 1084 BattULoChrg_U_RqMx 1;
BA_ "U_CX727_MY2021_Tx" SG_ 1084 BattULoChrg_U_RqMx 1;
BA_ "GenSigStartValue" SG_ 1084 BattULoChrg_U_RqMx 34;
BA_ "GenSigStartValueInteger" SG_ 1084 BattULoChrg_U_RqMx 34;
BA_ "U_CD764_MY2022_Tx" SG_ 1084 BattULoChrg_U_RqMn 1;
BA_ "U_U55X_MY2022_Tx" SG_ 1084 BattULoChrg_U_RqMn 1;
BA_ "U_CD542_MY2021_Tx" SG_ 1084 BattULoChrg_U_RqMn 1;
BA_ "U_T6_MCA_MY2020_Tx" SG_ 1084 BattULoChrg_U_RqMn 1;
BA_ "U_P702_MY2021_Tx" SG_ 1084 BattULoChrg_U_RqMn 1;
BA_ "U_CX727_MY2021_Tx" SG_ 1084 BattULoChrg_U_RqMn 1;
BA_ "U_CD764_MY2022_Tx" SG_ 1084 BattULoState_D_Qlty 1;
BA_ "U_U55X_MY2022_Tx" SG_ 1084 BattULoState_D_Qlty 1;
BA_ "U_CD542_MY2021_Tx" SG_ 1084 BattULoState_D_Qlty 1;
BA_ "U_T6_MCA_MY2020_Tx" SG_ 1084 BattULoState_D_Qlty 1;
BA_ "U_P702_MY2021_Tx" SG_ 1084 BattULoState_D_Qlty 1;
BA_ "U_CX727_MY2021_Tx" SG_ 1084 BattULoState_D_Qlty 1;
BA_ "U_CD764_MY2022_Rx" SG_ 1084 BattULoState_D_Qlty 1;
BA_ "U_U55X_MY2022_Rx" SG_ 1084 BattULoState_D_Qlty 1;
BA_ "U_CD542_MY2021_Rx" SG_ 1084 BattULoState_D_Qlty 1;
BA_ "ECGUsedRxSignal" SG_ 1084 BattULoState_D_Qlty 1;
BA_ "U_T6_MCA_MY2020_Rx" SG_ 1084 BattULoState_D_Qlty 1;
BA_ "U_CD764_MY2022_Tx" SG_ 1084 BSFault 1;
BA_ "U_U55X_MY2022_Tx" SG_ 1084 BSFault 1;
BA_ "U_CD542_MY2021_Tx" SG_ 1084 BSFault 1;
BA_ "U_T6_MCA_MY2020_Tx" SG_ 1084 BSFault 1;
BA_ "U_P702_MY2021_Tx" SG_ 1084 BSFault 1;
BA_ "U_CX727_MY2021_Tx" SG_ 1084 BSFault 1;
BA_ "U_CD764_MY2022_Tx" SG_ 1084 BattULo2_Te_Actl 1;
BA_ "U_U55X_MY2022_Tx" SG_ 1084 BattULo2_Te_Actl 1;
BA_ "U_CD542_MY2021_Tx" SG_ 1084 BattULo2_Te_Actl 1;
BA_ "U_T6_MCA_MY2020_Tx" SG_ 1084 BattULo2_Te_Actl 1;
BA_ "U_P702_MY2021_Tx" SG_ 1084 BattULo2_Te_Actl 1;
BA_ "U_CX727_MY2021_Tx" SG_ 1084 BattULo2_Te_Actl 1;
BA_ "U_CD764_MY2022_Rx" SG_ 1084 BattULo2_Te_Actl 1;
BA_ "U_U55X_MY2022_Rx" SG_ 1084 BattULo2_Te_Actl 1;
BA_ "U_CD542_MY2021_Rx" SG_ 1084 BattULo2_Te_Actl 1;
BA_ "ECGUsedRxSignal" SG_ 1084 BattULo2_Te_Actl 1;
BA_ "U_T6_MCA_MY2020_Rx" SG_ 1084 BattULo2_Te_Actl 1;
BA_ "GenSigStartValue" SG_ 1084 BattULo2_Te_Actl 127;
BA_ "GenSigStartValueInteger" SG_ 1084 BattULo2_Te_Actl 127;
BA_ "U_CD764_MY2022_Tx" SG_ 1084 BSBattSOC 1;
BA_ "U_U55X_MY2022_Tx" SG_ 1084 BSBattSOC 1;
BA_ "U_CD542_MY2021_Tx" SG_ 1084 BSBattSOC 1;
BA_ "U_T6_MCA_MY2020_Tx" SG_ 1084 BSBattSOC 1;
BA_ "U_P702_MY2021_Tx" SG_ 1084 BSBattSOC 1;
BA_ "U_CX727_MY2021_Tx" SG_ 1084 BSBattSOC 1;
BA_ "U_CD764_MY2022_Rx" SG_ 1084 BSBattSOC 1;
BA_ "U_U55X_MY2022_Rx" SG_ 1084 BSBattSOC 1;
BA_ "U_CD542_MY2021_Rx" SG_ 1084 BSBattSOC 1;
BA_ "ECGUsedRxSignal" SG_ 1084 BSBattSOC 1;
BA_ "U_T6_MCA_MY2020_Rx" SG_ 1084 BSBattSOC 1;
BA_ "U_CD764_MY2022_Tx" SG_ 1084 BSBattQDeltaRideAh 1;
BA_ "U_U55X_MY2022_Tx" SG_ 1084 BSBattQDeltaRideAh 1;
BA_ "U_CD542_MY2021_Tx" SG_ 1084 BSBattQDeltaRideAh 1;
BA_ "U_T6_MCA_MY2020_Tx" SG_ 1084 BSBattQDeltaRideAh 1;
BA_ "U_P702_MY2021_Tx" SG_ 1084 BSBattQDeltaRideAh 1;
BA_ "U_CX727_MY2021_Tx" SG_ 1084 BSBattQDeltaRideAh 1;
BA_ "GenSigStartValueInteger" SG_ 1084 BSBattQDeltaRideAh 12800;
BA_ "U_CD764_MY2022_Tx" SG_ 1084 BSBattQCapAh 1;
BA_ "U_U55X_MY2022_Tx" SG_ 1084 BSBattQCapAh 1;
BA_ "U_CD542_MY2021_Tx" SG_ 1084 BSBattQCapAh 1;
BA_ "U_T6_MCA_MY2020_Tx" SG_ 1084 BSBattQCapAh 1;
BA_ "U_P702_MY2021_Tx" SG_ 1084 BSBattQCapAh 1;
BA_ "U_CX727_MY2021_Tx" SG_ 1084 BSBattQCapAh 1;
BA_ "U_CD764_MY2022_Rx" SG_ 1084 BSBattQCapAh 1;
BA_ "U_U55X_MY2022_Rx" SG_ 1084 BSBattQCapAh 1;
BA_ "U_CD542_MY2021_Rx" SG_ 1084 BSBattQCapAh 1;
BA_ "ECGUsedRxSignal" SG_ 1084 BSBattQCapAh 1;
BA_ "U_T6_MCA_MY2020_Rx" SG_ 1084 BSBattQCapAh 1;
BA_ "GenSigStartValueInteger" SG_ 1086 AwdPtu_Te_Actl 50;
BA_ "GenSigStartValueInteger" SG_ 1086 EngMnfld_P_Actl 2068;
BA_ "GenSigStartValue" SG_ 1086 EngIpcDsplyCht_Te_Actl 75;
BA_ "GenSigStartValueInteger" SG_ 1086 EngIpcDsplyCht_Te_Actl 75;
BA_ "U_CD764_MY2022_Rx" SG_ 1086 FuelPumpPwr_B_Rq 1;
BA_ "U_U55X_MY2022_Rx" SG_ 1086 FuelPumpPwr_B_Rq 1;
BA_ "U_CD542_MY2021_Rx" SG_ 1086 FuelPumpPwr_B_Rq 1;
BA_ "U_T6_MCA_MY2020_Rx" SG_ 1086 FuelPumpPwr_B_Rq 1;
BA_ "U_P702_MY2021_Rx" SG_ 1086 FuelPumpPwr_B_Rq 1;
BA_ "U_CX727_MY2021_Rx" SG_ 1086 FuelPumpPwr_B_Rq 1;
BA_ "U_CD764_MY2022_Rx" SG_ 1086 BattULoChrg_U_Cmd 1;
BA_ "U_U55X_MY2022_Rx" SG_ 1086 BattULoChrg_U_Cmd 1;
BA_ "U_T6_MCA_MY2020_Rx" SG_ 1086 BattULoChrg_U_Cmd 1;
BA_ "U_CD542_MY2021_Rx" SG_ 1086 BattULoChrg_U_Cmd 1;
BA_ "U_P702_MY2021_Rx" SG_ 1086 BattULoChrg_U_Cmd 1;
BA_ "U_CX727_MY2021_Rx" SG_ 1086 BattULoChrg_U_Cmd 1;
BA_ "U_CD764_MY2022_Rx" SG_ 1086 ElLoadCtl_D_Rq 1;
BA_ "U_U55X_MY2022_Rx" SG_ 1086 ElLoadCtl_D_Rq 1;
BA_ "U_CD542_MY2021_Rx" SG_ 1086 ElLoadCtl_D_Rq 1;
BA_ "U_T6_MCA_MY2020_Rx" SG_ 1086 ElLoadCtl_D_Rq 1;
BA_ "U_P702_MY2021_Rx" SG_ 1086 ElLoadCtl_D_Rq 1;
BA_ "U_CX727_MY2021_Rx" SG_ 1086 ElLoadCtl_D_Rq 1;
BA_ "ContentDependant" SG_ 1086 ElLoadCtl_D_Rq 1;
BA_ "U_CD764_MY2022_Rx" SG_ 1085 ULoRgenTestMde_B_Stat 1;
BA_ "U_U55X_MY2022_Rx" SG_ 1085 ULoRgenTestMde_B_Stat 1;
BA_ "U_CD542_MY2021_Rx" SG_ 1085 ULoRgenTestMde_B_Stat 1;
BA_ "U_T6_MCA_MY2020_Rx" SG_ 1085 ULoRgenTestMde_B_Stat 1;
BA_ "U_P702_MY2021_Rx" SG_ 1085 ULoRgenTestMde_B_Stat 1;
BA_ "U_CX727_MY2021_Rx" SG_ 1085 ULoRgenTestMde_B_Stat 1;
BA_ "ContentDependant" SG_ 1085 ULoRgenTestMde_B_Stat 1;
BA_ "U_CD542_MY2021_Tx" SG_ 1085 PwSrcULoOvrTe_B_Actl 1;
BA_ "U_P702_MY2021_Tx" SG_ 1085 PwSrcULoOvrTe_B_Actl 1;
BA_ "U_CX727_MY2021_Tx" SG_ 1085 PwSrcULoOvrTe_B_Actl 1;
BA_ "ECGUsedRxSignal" SG_ 1085 PwSrcULoOvrTe_B_Actl 1;
BA_ "U_CD764_MY2022_Rx" SG_ 1085 PwSrcULoOvrTe_B_Actl 1;
BA_ "U_U55X_MY2022_Rx" SG_ 1085 PwSrcULoOvrTe_B_Actl 1;
BA_ "U_T6_MCA_MY2020_Rx" SG_ 1085 PwSrcULoOvrTe_B_Actl 1;
BA_ "U_P702_MY2021_Rx" SG_ 1085 PwSrcULoOvrTe_B_Actl 1;
BA_ "U_CX727_MY2021_Rx" SG_ 1085 PwSrcULoOvrTe_B_Actl 1;
BA_ "U_CD542_MY2021_Tx" SG_ 1085 PwSrcULoOn_B_Actl 1;
BA_ "U_P702_MY2021_Tx" SG_ 1085 PwSrcULoOn_B_Actl 1;
BA_ "U_CX727_MY2021_Tx" SG_ 1085 PwSrcULoOn_B_Actl 1;
BA_ "U_U55X_MY2022_Rx" SG_ 1085 PwSrcULoOn_B_Actl 1;
BA_ "ECGUsedRxSignal" SG_ 1085 PwSrcULoOn_B_Actl 1;
BA_ "U_CX727_MY2021_Rx" SG_ 1085 PwSrcULoOn_B_Actl 1;
BA_ "U_CD542_MY2021_Tx" SG_ 1085 PwSrcULoFalt_D_Stat 1;
BA_ "U_P702_MY2021_Tx" SG_ 1085 PwSrcULoFalt_D_Stat 1;
BA_ "U_CX727_MY2021_Tx" SG_ 1085 PwSrcULoFalt_D_Stat 1;
BA_ "ECGUsedRxSignal" SG_ 1085 PwSrcULoFalt_D_Stat 1;
BA_ "U_CD764_MY2022_Rx" SG_ 1085 PwSrcULoFalt_D_Stat 1;
BA_ "U_U55X_MY2022_Rx" SG_ 1085 PwSrcULoFalt_D_Stat 1;
BA_ "U_T6_MCA_MY2020_Rx" SG_ 1085 PwSrcULoFalt_D_Stat 1;
BA_ "U_P702_MY2021_Rx" SG_ 1085 PwSrcULoFalt_D_Stat 1;
BA_ "U_CX727_MY2021_Rx" SG_ 1085 PwSrcULoFalt_D_Stat 1;
BA_ "U_CD542_MY2021_Tx" SG_ 1085 PwSrcULoDcnnt_B_Stat 1;
BA_ "U_P702_MY2021_Tx" SG_ 1085 PwSrcULoDcnnt_B_Stat 1;
BA_ "U_CX727_MY2021_Tx" SG_ 1085 PwSrcULoDcnnt_B_Stat 1;
BA_ "U_CD764_MY2022_Rx" SG_ 1085 PwSrcULoDcnnt_B_Stat 1;
BA_ "U_U55X_MY2022_Rx" SG_ 1085 PwSrcULoDcnnt_B_Stat 1;
BA_ "U_CD542_MY2021_Rx" SG_ 1085 PwSrcULoDcnnt_B_Stat 1;
BA_ "U_T6_MCA_MY2020_Rx" SG_ 1085 PwSrcULoDcnnt_B_Stat 1;
BA_ "U_P702_MY2021_Rx" SG_ 1085 PwSrcULoDcnnt_B_Stat 1;
BA_ "U_CX727_MY2021_Rx" SG_ 1085 PwSrcULoDcnnt_B_Stat 1;
BA_ "U_CD542_MY2021_Tx" SG_ 1085 PwSrcULo_Pc_Mx 1;
BA_ "U_P702_MY2021_Tx" SG_ 1085 PwSrcULo_Pc_Mx 1;
BA_ "U_CX727_MY2021_Tx" SG_ 1085 PwSrcULo_Pc_Mx 1;
BA_ "U_CD764_MY2022_Rx" SG_ 1085 PwSrcULo_Pc_Mx 1;
BA_ "U_U55X_MY2022_Rx" SG_ 1085 PwSrcULo_Pc_Mx 1;
BA_ "U_CD542_MY2021_Rx" SG_ 1085 PwSrcULo_Pc_Mx 1;
BA_ "U_T6_MCA_MY2020_Rx" SG_ 1085 PwSrcULo_Pc_Mx 1;
BA_ "U_P702_MY2021_Rx" SG_ 1085 PwSrcULo_Pc_Mx 1;
BA_ "U_CX727_MY2021_Rx" SG_ 1085 PwSrcULo_Pc_Mx 1;
BA_ "ContentDependant" SG_ 1085 BattTracCool_D_RqDcdc 1;
BA_ "U_CD764_MY2022_Rx" SG_ 1085 PwSrcULoComm_B_Falt 1;
BA_ "U_U55X_MY2022_Rx" SG_ 1085 PwSrcULoComm_B_Falt 1;
BA_ "U_CD542_MY2021_Rx" SG_ 1085 PwSrcULoComm_B_Falt 1;
BA_ "U_T6_MCA_MY2020_Rx" SG_ 1085 PwSrcULoComm_B_Falt 1;
BA_ "U_P702_MY2021_Rx" SG_ 1085 PwSrcULoComm_B_Falt 1;
BA_ "U_CX727_MY2021_Rx" SG_ 1085 PwSrcULoComm_B_Falt 1;
BA_ "ContentDependant" SG_ 1085 PwSrcULoComm_B_Falt 1;
BA_ "U_CD542_MY2021_Tx" SG_ 1085 DcdcULo_U_Actl 1;
BA_ "U_P702_MY2021_Tx" SG_ 1085 DcdcULo_U_Actl 1;
BA_ "U_CX727_MY2021_Tx" SG_ 1085 DcdcULo_U_Actl 1;
BA_ "U_P702_MY2021_Rx" SG_ 1085 DcdcULo_U_Actl 1;
BA_ "U_CX727_MY2021_Rx" SG_ 1085 DcdcULo_U_Actl 1;
BA_ "ContentDependant" SG_ 1085 DcdcULo_U_Actl 1;
BA_ "U_CD542_MY2021_Tx" SG_ 1085 DcdcUHi_I_Actl 1;
BA_ "U_P702_MY2021_Tx" SG_ 1085 DcdcUHi_I_Actl 1;
BA_ "U_CX727_MY2021_Tx" SG_ 1085 DcdcUHi_I_Actl 1;
BA_ "U_U55X_MY2022_Rx" SG_ 1085 DcdcUHi_I_Actl 1;
BA_ "U_CD542_MY2021_Rx" SG_ 1085 DcdcUHi_I_Actl 1;
BA_ "U_CX727_MY2021_Rx" SG_ 1085 DcdcUHi_I_Actl 1;
BA_ "ContentDependant" SG_ 1085 DcdcUHi_I_Actl 1;
BA_ "U_CD542_MY2021_Tx" SG_ 1085 PwSrcULo_I_Mx 1;
BA_ "U_P702_MY2021_Tx" SG_ 1085 PwSrcULo_I_Mx 1;
BA_ "U_CX727_MY2021_Tx" SG_ 1085 PwSrcULo_I_Mx 1;
BA_ "U_CD764_MY2022_Rx" SG_ 1085 PwSrcULo_I_Mx 1;
BA_ "U_U55X_MY2022_Rx" SG_ 1085 PwSrcULo_I_Mx 1;
BA_ "U_CD542_MY2021_Rx" SG_ 1085 PwSrcULo_I_Mx 1;
BA_ "U_T6_MCA_MY2020_Rx" SG_ 1085 PwSrcULo_I_Mx 1;
BA_ "U_P702_MY2021_Rx" SG_ 1085 PwSrcULo_I_Mx 1;
BA_ "U_CX727_MY2021_Rx" SG_ 1085 PwSrcULo_I_Mx 1;
BA_ "U_CD542_MY2021_Tx" SG_ 1085 PwSrcULo_I_Actl 1;
BA_ "U_P702_MY2021_Tx" SG_ 1085 PwSrcULo_I_Actl 1;
BA_ "U_CX727_MY2021_Tx" SG_ 1085 PwSrcULo_I_Actl 1;
BA_ "U_CD764_MY2022_Rx" SG_ 1085 PwSrcULo_I_Actl 1;
BA_ "U_U55X_MY2022_Rx" SG_ 1085 PwSrcULo_I_Actl 1;
BA_ "U_CD542_MY2021_Rx" SG_ 1085 PwSrcULo_I_Actl 1;
BA_ "U_T6_MCA_MY2020_Rx" SG_ 1085 PwSrcULo_I_Actl 1;
BA_ "U_P702_MY2021_Rx" SG_ 1085 PwSrcULo_I_Actl 1;
BA_ "U_CX727_MY2021_Rx" SG_ 1085 PwSrcULo_I_Actl 1;
BA_ "U_CD542_MY2021_Tx" SG_ 1085 DcdcUHi_U_Actl 1;
BA_ "U_P702_MY2021_Tx" SG_ 1085 DcdcUHi_U_Actl 1;
BA_ "U_CX727_MY2021_Tx" SG_ 1085 DcdcUHi_U_Actl 1;
BA_ "U_U55X_MY2022_Rx" SG_ 1085 DcdcUHi_U_Actl 1;
BA_ "U_CD542_MY2021_Rx" SG_ 1085 DcdcUHi_U_Actl 1;
BA_ "U_P702_MY2021_Rx" SG_ 1085 DcdcUHi_U_Actl 1;
BA_ "U_CX727_MY2021_Rx" SG_ 1085 DcdcUHi_U_Actl 1;
BA_ "ContentDependant" SG_ 1085 DcdcUHi_U_Actl 1;
BA_ "ContentDependant" SG_ 603 WhlDirAvgDrv_D_Actl 1;
BA_ "ContentDependant" SG_ 603 PrplTqMnRgen_B_Actl 1;
BA_ "U_CX727_MY2021_Rx" SG_ 603 PrplWhlTot_Tq_Cmd 1;
BA_ "GenSigStartValue" SG_ 603 EDrvTqMntrRconfg_D_Cmd 7;
BA_ "GenSigStartValueInteger" SG_ 603 EDrvTqMntrRconfg_D_Cmd 7;
BA_ "U_CD542_MY2021_Rx" SG_ 603 BattTracCnnct_D_Rq 1;
BA_ "U_P702_MY2021_Rx" SG_ 603 BattTracCnnct_D_Rq 1;
BA_ "U_CX727_MY2021_Rx" SG_ 603 BattTracCnnct_D_Rq 1;
BA_ "GenSigStartValue" SG_ 603 BattTracCnnct_D_Rq 2;
BA_ "ContentDependant" SG_ 603 BattTracCnnct_D_Rq 1;
BA_ "GenSigStartValueInteger" SG_ 603 BattTracCnnct_D_Rq 2;
BA_ "U_CD542_MY2021_Rx" SG_ 602 HtrnWarnLamp_B_Dsply 1;
BA_ "ECGUsedRxSignal" SG_ 602 HtrnWarnLamp_B_Dsply 1;
BA_ "GenSigStartValue" SG_ 602 BattTracRsrvSoc_Pc_Rq 16382;
BA_ "U_CD542_MY2021_Tx" SG_ 587 BattTracClnt_Te_Actl 1;
BA_ "U_P702_MY2021_Tx" SG_ 587 BattTracClnt_Te_Actl 1;
BA_ "U_CX727_MY2021_Tx" SG_ 587 BattTracClnt_Te_Actl 1;
BA_ "GenSigStartValue" SG_ 587 BattTracClnt_Te_Actl 254;
BA_ "GenSigStartValueInteger" SG_ 587 BattTracClnt_Te_Actl 164;
BA_ "GenSigStartValue" SG_ 587 BattTracClnt_Te_Rq 190;
BA_ "GenSigStartValueInteger" SG_ 587 BattTracClnt_Te_Rq 190;
BA_ "U_CD542_MY2021_Tx" SG_ 587 BattTracWarnLamp_B_Rq 1;
BA_ "U_P702_MY2021_Tx" SG_ 587 BattTracWarnLamp_B_Rq 1;
BA_ "U_CX727_MY2021_Tx" SG_ 587 BattTracWarnLamp_B_Rq 1;
BA_ "U_U55X_MY2022_Rx" SG_ 587 BattTracWarnLamp_B_Rq 1;
BA_ "U_CD542_MY2021_Rx" SG_ 587 BattTracWarnLamp_B_Rq 1;
BA_ "ECGUsedRxSignal" SG_ 587 BattTracWarnLamp_B_Rq 1;
BA_ "U_CD542_MY2021_Tx" SG_ 587 BattTracSrvcRqd_B_Rq 1;
BA_ "U_P702_MY2021_Tx" SG_ 587 BattTracSrvcRqd_B_Rq 1;
BA_ "U_CX727_MY2021_Tx" SG_ 587 BattTracSrvcRqd_B_Rq 1;
BA_ "U_U55X_MY2022_Rx" SG_ 587 BattTracSrvcRqd_B_Rq 1;
BA_ "U_CD542_MY2021_Rx" SG_ 587 BattTracSrvcRqd_B_Rq 1;
BA_ "ECGUsedRxSignal" SG_ 587 BattTracSrvcRqd_B_Rq 1;
BA_ "U_CD542_MY2021_Tx" SG_ 587 BattTracSoc_Pc_MxPrtct 1;
BA_ "U_P702_MY2021_Tx" SG_ 587 BattTracSoc_Pc_MxPrtct 1;
BA_ "U_CX727_MY2021_Tx" SG_ 587 BattTracSoc_Pc_MxPrtct 1;
BA_ "GenSigStartValue" SG_ 587 BattTracSoc_Pc_MxPrtct 700;
BA_ "GenSigStartValueInteger" SG_ 587 BattTracSoc_Pc_MxPrtct 700;
BA_ "U_CD542_MY2021_Tx" SG_ 587 BattTracSoc_Pc_MnPrtct 1;
BA_ "U_P702_MY2021_Tx" SG_ 587 BattTracSoc_Pc_MnPrtct 1;
BA_ "U_CX727_MY2021_Tx" SG_ 587 BattTracSoc_Pc_MnPrtct 1;
BA_ "GenSigStartValue" SG_ 587 BattTracSoc_Pc_MnPrtct 30;
BA_ "GenSigStartValueInteger" SG_ 587 BattTracSoc_Pc_MnPrtct 300;
BA_ "U_CD542_MY2021_Tx" SG_ 587 BattTracSoc_Pc_LimLo 1;
BA_ "U_P702_MY2021_Tx" SG_ 587 BattTracSoc_Pc_LimLo 1;
BA_ "U_CX727_MY2021_Tx" SG_ 587 BattTracSoc_Pc_LimLo 1;
BA_ "GenSigStartValue" SG_ 587 BattTracSoc_Pc_LimLo 400;
BA_ "GenSigStartValueInteger" SG_ 587 BattTracSoc_Pc_LimLo 400;
BA_ "U_CD542_MY2021_Tx" SG_ 587 BattTracSoc_Pc_LimHi 1;
BA_ "U_P702_MY2021_Tx" SG_ 587 BattTracSoc_Pc_LimHi 1;
BA_ "U_CX727_MY2021_Tx" SG_ 587 BattTracSoc_Pc_LimHi 1;
BA_ "GenSigStartValue" SG_ 587 BattTracSoc_Pc_LimHi 600;
BA_ "GenSigStartValueInteger" SG_ 587 BattTracSoc_Pc_LimHi 600;
BA_ "GenSigStartValue" SG_ 1040 BattTrac_I2_EstVsc 262142;
BA_ "GenSigStartValueInteger" SG_ 1040 BattTrac_I2_EstVsc 15000;
BA_ "U_CD542_MY2021_Rx" SG_ 1040 ElCmprEnbl_B_Rq 1;
BA_ "U_P702_MY2021_Rx" SG_ 1040 ElCmprEnbl_B_Rq 1;
BA_ "U_CX727_MY2021_Rx" SG_ 1040 ElCmprEnbl_B_Rq 1;
BA_ "U_CD542_MY2021_Rx" SG_ 1040 ElCmpr_N_Rq 1;
BA_ "U_P702_MY2021_Rx" SG_ 1040 ElCmpr_N_Rq 1;
BA_ "U_CX727_MY2021_Rx" SG_ 1040 ElCmpr_N_Rq 1;
BA_ "U_CD542_MY2021_Tx" SG_ 1041 ElCmprPerfErr_D_Falt 1;
BA_ "U_P702_MY2021_Tx" SG_ 1041 ElCmprPerfErr_D_Falt 1;
BA_ "U_CX727_MY2021_Tx" SG_ 1041 ElCmprPerfErr_D_Falt 1;
BA_ "U_CD542_MY2021_Tx" SG_ 1041 ElCmprInnrErr_D_Falt 1;
BA_ "U_P702_MY2021_Tx" SG_ 1041 ElCmprInnrErr_D_Falt 1;
BA_ "U_CX727_MY2021_Tx" SG_ 1041 ElCmprInnrErr_D_Falt 1;
BA_ "U_CD542_MY2021_Tx" SG_ 1041 ElCmprLostComm_D_Falt 1;
BA_ "U_P702_MY2021_Tx" SG_ 1041 ElCmprLostComm_D_Falt 1;
BA_ "U_CX727_MY2021_Tx" SG_ 1041 ElCmprLostComm_D_Falt 1;
BA_ "U_CD542_MY2021_Tx" SG_ 1041 ElCmprOverLoad_D_Falt 1;
BA_ "U_P702_MY2021_Tx" SG_ 1041 ElCmprOverLoad_D_Falt 1;
BA_ "U_CX727_MY2021_Tx" SG_ 1041 ElCmprOverLoad_D_Falt 1;
BA_ "U_CD542_MY2021_Tx" SG_ 1041 ElCmprOverTe_D_Falt 1;
BA_ "U_P702_MY2021_Tx" SG_ 1041 ElCmprOverTe_D_Falt 1;
BA_ "U_CX727_MY2021_Tx" SG_ 1041 ElCmprOverTe_D_Falt 1;
BA_ "U_CD542_MY2021_Tx" SG_ 1041 ElCmprBattURng_D_Falt 1;
BA_ "U_P702_MY2021_Tx" SG_ 1041 ElCmprBattURng_D_Falt 1;
BA_ "U_CX727_MY2021_Tx" SG_ 1041 ElCmprBattURng_D_Falt 1;
BA_ "U_CD542_MY2021_Tx" SG_ 1041 ElCmprBattSysU_D_Falt 1;
BA_ "U_P702_MY2021_Tx" SG_ 1041 ElCmprBattSysU_D_Falt 1;
BA_ "U_CX727_MY2021_Tx" SG_ 1041 ElCmprBattSysU_D_Falt 1;
BA_ "U_CD542_MY2021_Tx" SG_ 1041 ElCmprSysU_D_Falt 1;
BA_ "U_P702_MY2021_Tx" SG_ 1041 ElCmprSysU_D_Falt 1;
BA_ "U_CX727_MY2021_Tx" SG_ 1041 ElCmprSysU_D_Falt 1;
BA_ "U_CD542_MY2021_Tx" SG_ 1041 ElCmprUHi_U_Actl 1;
BA_ "U_P702_MY2021_Tx" SG_ 1041 ElCmprUHi_U_Actl 1;
BA_ "U_CX727_MY2021_Tx" SG_ 1041 ElCmprUHi_U_Actl 1;
BA_ "U_CD542_MY2021_Tx" SG_ 1041 ElCmprUHi_D_Stat 1;
BA_ "U_P702_MY2021_Tx" SG_ 1041 ElCmprUHi_D_Stat 1;
BA_ "U_CX727_MY2021_Tx" SG_ 1041 ElCmprUHi_D_Stat 1;
BA_ "U_CD542_MY2021_Tx" SG_ 1041 ElCmprOverTe_D_Stat 1;
BA_ "U_P702_MY2021_Tx" SG_ 1041 ElCmprOverTe_D_Stat 1;
BA_ "U_CX727_MY2021_Tx" SG_ 1041 ElCmprOverTe_D_Stat 1;
BA_ "U_CD542_MY2021_Tx" SG_ 1041 ElCmpr_N_Actl 1;
BA_ "U_P702_MY2021_Tx" SG_ 1041 ElCmpr_N_Actl 1;
BA_ "U_CX727_MY2021_Tx" SG_ 1041 ElCmpr_N_Actl 1;
BA_ "U_CD542_MY2021_Tx" SG_ 1041 ElCmpr_Pw_Actl 1;
BA_ "U_P702_MY2021_Tx" SG_ 1041 ElCmpr_Pw_Actl 1;
BA_ "U_CX727_MY2021_Tx" SG_ 1041 ElCmpr_Pw_Actl 1;
BA_ "U_CD542_MY2021_Tx" SG_ 1041 ElCmpr_D_Stat 1;
BA_ "U_P702_MY2021_Tx" SG_ 1041 ElCmpr_D_Stat 1;
BA_ "U_CX727_MY2021_Tx" SG_ 1041 ElCmpr_D_Stat 1;
BA_ "U_CD542_MY2021_Tx" SG_ 1999 TesterPhysicalResACCM 1;
BA_ "U_P702_MY2021_Tx" SG_ 1999 TesterPhysicalResACCM 1;
BA_ "U_CX727_MY2021_Tx" SG_ 1999 TesterPhysicalResACCM 1;
BA_ "GenSigSendType" SG_ 1999 TesterPhysicalResACCM 3;
BA_ "U_CD542_MY2021_Rx" SG_ 1991 TesterPhysicalReqACCM 1;
BA_ "U_P702_MY2021_Rx" SG_ 1991 TesterPhysicalReqACCM 1;
BA_ "U_CX727_MY2021_Rx" SG_ 1991 TesterPhysicalReqACCM 1;
BA_ "GenSigSendType" SG_ 1991 TesterPhysicalReqACCM 3;
BA_ "GenSigSendType" SG_ 2022 TesterPhysicalReqSOBDMC 3;
BA_ "GenSigStartValue" SG_ 1088 TrlrRng_L_Dsply 8190;
BA_ "ContentDependant" SG_ 1088 HvacPrecondMode2_D_Rq 1;
BA_ "WakeupSignal" SG_ 1088 HvacPrecondMode2_D_Rq 1;
BA_ "ContentDependant" SG_ 1088 HvacPrecondBlwr2_D_Rq 1;
BA_ "WakeupSignal" SG_ 1088 HvacPrecondBlwr2_D_Rq 1;
BA_ "GenSigStartValue" SG_ 1088 HvacPrecond_Te_Rq 2;
BA_ "GenSigStartValueInteger" SG_ 1088 HvacPrecond_Te_Rq 2;
BA_ "GenSigStartValue" SG_ 1088 BattDcChrgRms_I_Lim 32766;
BA_ "U_CD542_MY2021_Rx" SG_ 1088 BattChrgInhbt_D_Rq 1;
BA_ "U_CX727_MY2021_Rx" SG_ 1088 BattChrgInhbt_D_Rq 1;
BA_ "WakeupSignal" SG_ 1088 ChrgStat_D2_Dsply 1;
BA_ "GenSigStartValue" SG_ 869 EffWhlLvl2_Pc_Dsply 511;
BA_ "GenSigStartValueInteger" SG_ 869 EffWhlLvl2_Pc_Dsply 511;
BA_ "GenSigStartValue" SG_ 870 RngPerChrgInst_L_Dsply 4093;
BA_ "GenSigStartValueInteger" SG_ 870 RngPerChrgInst_L_Dsply 4094;
BA_ "GenSigStartValue" SG_ 870 EffRgenThres_Pc_Dsply 1023;
BA_ "GenSigStartValue" SG_ 1071 EngMnfld3_P_Actl 254;
BA_ "GenSigStartValueInteger" SG_ 1071 EngMnfld3_P_Actl 254;
BA_ "ContentDependant" SG_ 1071 CluPdl_PcRate_Actl 1;
BA_ "GenSigStartValue" SG_ 1071 CluPdlPosPcMeas_D_Qf 1;
BA_ "MetaData" SG_ 1071 CluPdlPosPcMeas_D_Qf 1;
BA_ "ContentDependant" SG_ 1071 CluPdlPosPcMeas_D_Qf 1;
BA_ "GenSigStartValueInteger" SG_ 1071 CluPdlPosPcMeas_D_Qf 1;
BA_ "ContentDependant" SG_ 1071 CluPdlPos_Pc_Meas 1;
BA_ "ContentDependant" SG_ 1071 EngAoutIdl_N_Ntrl 1;
BA_ "U_CD764_MY2022_Rx" SG_ 130 TrlrHitchLamp_D_Rqst 1;
BA_ "U_U55X_MY2022_Rx" SG_ 130 TrlrHitchLamp_D_Rqst 1;
BA_ "U_CD542_MY2021_Rx" SG_ 130 TrlrHitchLamp_D_Rqst 1;
BA_ "U_T6_MCA_MY2020_Rx" SG_ 130 TrlrHitchLamp_D_Rqst 1;
BA_ "U_P702_MY2021_Rx" SG_ 130 TrlrHitchLamp_D_Rqst 1;
BA_ "U_CX727_MY2021_Rx" SG_ 130 TrlrHitchLamp_D_Rqst 1;
BA_ "GenSigStartValue" SG_ 130 Veh_V_RqMxTrlrAid 255;
BA_ "GenSigStartValueInteger" SG_ 130 Veh_V_RqMxTrlrAid 255;
BA_ "GenSigStartValueInteger" SG_ 130 DrvSte_Tq_Actl 128;
BA_ "U_CD764_MY2022_Rx" SG_ 130 SteMdule_U_Meas 1;
BA_ "U_U55X_MY2022_Rx" SG_ 130 SteMdule_U_Meas 1;
BA_ "U_CD542_MY2021_Rx" SG_ 130 SteMdule_U_Meas 1;
BA_ "U_T6_MCA_MY2020_Rx" SG_ 130 SteMdule_U_Meas 1;
BA_ "U_P702_MY2021_Rx" SG_ 130 SteMdule_U_Meas 1;
BA_ "U_CX727_MY2021_Rx" SG_ 130 SteMdule_U_Meas 1;
BA_ "GenSigStartValue" SG_ 130 SteMdule_U_Meas 255;
BA_ "GenSigStartValueInteger" SG_ 130 SteMdule_U_Meas 255;
BA_ "U_CD764_MY2022_Rx" SG_ 130 SteMdule_I_Est 1;
BA_ "U_U55X_MY2022_Rx" SG_ 130 SteMdule_I_Est 1;
BA_ "U_CD542_MY2021_Rx" SG_ 130 SteMdule_I_Est 1;
BA_ "U_T6_MCA_MY2020_Rx" SG_ 130 SteMdule_I_Est 1;
BA_ "U_P702_MY2021_Rx" SG_ 130 SteMdule_I_Est 1;
BA_ "U_CX727_MY2021_Rx" SG_ 130 SteMdule_I_Est 1;
BA_ "GenSigStartValue" SG_ 130 SteMdule_I_Est 4095;
BA_ "GenSigStartValueInteger" SG_ 130 SteMdule_I_Est 4095;
BA_ "GenSigStartValue" SG_ 130 SteeringColumnTorque 254;
BA_ "GenSigStartValueInteger" SG_ 130 SteeringColumnTorque 254;
BA_ "GenSigSendType" SG_ 1076 CenterStackRing_D_Actl 3;
BA_ "GenSigStartValue" SG_ 1076 CenterStackRing_D_Actl 2;
BA_ "GenSigStartValueInteger" SG_ 1076 CenterStackRing_D_Actl 2;
BA_ "GenSigSendType" SG_ 1076 EngIdlShutDown_B_RqDrv 3;
BA_ "GenSigSendType" SG_ 1076 OdoTripRx_B_Actl 3;
BA_ "GenSigSendType" SG_ 1076 LscmbbEngTqMn_B_Rq 3;
BA_ "U_CD764_MY2022_Rx" SG_ 1076 TirePReset_B_Rq_UB 1;
BA_ "U_U55X_MY2022_Rx" SG_ 1076 TirePReset_B_Rq_UB 1;
BA_ "U_CD542_MY2021_Rx" SG_ 1076 TirePReset_B_Rq_UB 1;
BA_ "U_T6_MCA_MY2020_Rx" SG_ 1076 TirePReset_B_Rq_UB 1;
BA_ "U_P702_MY2021_Rx" SG_ 1076 TirePReset_B_Rq_UB 1;
BA_ "U_CX727_MY2021_Rx" SG_ 1076 TirePReset_B_Rq_UB 1;
BA_ "U_CD764_MY2022_Rx" SG_ 1076 DrTGate_D_Rq 1;
BA_ "U_U55X_MY2022_Rx" SG_ 1076 DrTGate_D_Rq 1;
BA_ "U_CD542_MY2021_Rx" SG_ 1076 DrTGate_D_Rq 1;
BA_ "U_T6_MCA_MY2020_Rx" SG_ 1076 DrTGate_D_Rq 1;
BA_ "U_P702_MY2021_Rx" SG_ 1076 DrTGate_D_Rq 1;
BA_ "U_CX727_MY2021_Rx" SG_ 1076 DrTGate_D_Rq 1;
BA_ "GenSigSendType" SG_ 1076 DrTGate_D_Rq 3;
BA_ "WakeupSignal" SG_ 1076 DrTGate_D_Rq 1;
BA_ "U_CD764_MY2022_Rx" SG_ 1076 DrTGate_D_Rq_UB 1;
BA_ "U_U55X_MY2022_Rx" SG_ 1076 DrTGate_D_Rq_UB 1;
BA_ "U_CD542_MY2021_Rx" SG_ 1076 DrTGate_D_Rq_UB 1;
BA_ "U_T6_MCA_MY2020_Rx" SG_ 1076 DrTGate_D_Rq_UB 1;
BA_ "U_P702_MY2021_Rx" SG_ 1076 DrTGate_D_Rq_UB 1;
BA_ "U_CX727_MY2021_Rx" SG_ 1076 DrTGate_D_Rq_UB 1;
BA_ "GenSigStartValue" SG_ 1076 Veh_V_CompLimMx 4093;
BA_ "GenSigStartValueInteger" SG_ 1076 Veh_V_CompLimMx 4095;
BA_ "GenSigSendType" SG_ 1076 FUEL_SENSOR_NUM 3;
BA_ "U_CD764_MY2022_Rx" SG_ 1076 TirePReset_B_Rq 1;
BA_ "U_U55X_MY2022_Rx" SG_ 1076 TirePReset_B_Rq 1;
BA_ "U_CD542_MY2021_Rx" SG_ 1076 TirePReset_B_Rq 1;
BA_ "U_T6_MCA_MY2020_Rx" SG_ 1076 TirePReset_B_Rq 1;
BA_ "U_P702_MY2021_Rx" SG_ 1076 TirePReset_B_Rq 1;
BA_ "U_CX727_MY2021_Rx" SG_ 1076 TirePReset_B_Rq 1;
BA_ "GenSigSendType" SG_ 1076 TirePReset_B_Rq 3;
BA_ "U_CD764_MY2022_Rx" SG_ 1072 ePRNDL_MODE_UB 1;
BA_ "U_U55X_MY2022_Rx" SG_ 1072 ePRNDL_MODE_UB 1;
BA_ "U_CD542_MY2021_Rx" SG_ 1072 ePRNDL_MODE_UB 1;
BA_ "U_T6_MCA_MY2020_Rx" SG_ 1072 ePRNDL_MODE_UB 1;
BA_ "U_P702_MY2021_Rx" SG_ 1072 ePRNDL_MODE_UB 1;
BA_ "U_CX727_MY2021_Rx" SG_ 1072 ePRNDL_MODE_UB 1;
BA_ "GenSigSendType" SG_ 1072 NtrlTowMdeEnbl_B_RqDrv 3;
BA_ "U_CD764_MY2022_Rx" SG_ 1072 Remote_Start_QuietMode_UB 1;
BA_ "U_U55X_MY2022_Rx" SG_ 1072 Remote_Start_QuietMode_UB 1;
BA_ "U_CD542_MY2021_Rx" SG_ 1072 Remote_Start_QuietMode_UB 1;
BA_ "U_T6_MCA_MY2020_Rx" SG_ 1072 Remote_Start_QuietMode_UB 1;
BA_ "U_P702_MY2021_Rx" SG_ 1072 Remote_Start_QuietMode_UB 1;
BA_ "U_CX727_MY2021_Rx" SG_ 1072 Remote_Start_QuietMode_UB 1;
BA_ "U_CD764_MY2022_Rx" SG_ 1072 Remote_Start_QuietMode 1;
BA_ "U_U55X_MY2022_Rx" SG_ 1072 Remote_Start_QuietMode 1;
BA_ "U_CD542_MY2021_Rx" SG_ 1072 Remote_Start_QuietMode 1;
BA_ "U_T6_MCA_MY2020_Rx" SG_ 1072 Remote_Start_QuietMode 1;
BA_ "U_P702_MY2021_Rx" SG_ 1072 Remote_Start_QuietMode 1;
BA_ "U_CX727_MY2021_Rx" SG_ 1072 Remote_Start_QuietMode 1;
BA_ "GenSigSendType" SG_ 1072 Remote_Start_QuietMode 3;
BA_ "U_CD764_MY2022_Rx" SG_ 1072 ParkDetect_Stat_UB 1;
BA_ "U_U55X_MY2022_Rx" SG_ 1072 ParkDetect_Stat_UB 1;
BA_ "U_CD542_MY2021_Rx" SG_ 1072 ParkDetect_Stat_UB 1;
BA_ "U_T6_MCA_MY2020_Rx" SG_ 1072 ParkDetect_Stat_UB 1;
BA_ "U_P702_MY2021_Rx" SG_ 1072 ParkDetect_Stat_UB 1;
BA_ "U_CX727_MY2021_Rx" SG_ 1072 ParkDetect_Stat_UB 1;
BA_ "U_CD764_MY2022_Rx" SG_ 1072 ParkDetect_Stat 1;
BA_ "U_U55X_MY2022_Rx" SG_ 1072 ParkDetect_Stat 1;
BA_ "U_CD542_MY2021_Rx" SG_ 1072 ParkDetect_Stat 1;
BA_ "U_T6_MCA_MY2020_Rx" SG_ 1072 ParkDetect_Stat 1;
BA_ "U_P702_MY2021_Rx" SG_ 1072 ParkDetect_Stat 1;
BA_ "U_CX727_MY2021_Rx" SG_ 1072 ParkDetect_Stat 1;
BA_ "GenSigSendType" SG_ 1072 ParkDetect_Stat 3;
BA_ "U_CD764_MY2022_Rx" SG_ 1072 TrlrLampCnnct_B_Actl_UB 1;
BA_ "U_U55X_MY2022_Rx" SG_ 1072 TrlrLampCnnct_B_Actl_UB 1;
BA_ "U_CD542_MY2021_Rx" SG_ 1072 TrlrLampCnnct_B_Actl_UB 1;
BA_ "U_T6_MCA_MY2020_Rx" SG_ 1072 TrlrLampCnnct_B_Actl_UB 1;
BA_ "U_P702_MY2021_Rx" SG_ 1072 TrlrLampCnnct_B_Actl_UB 1;
BA_ "U_CX727_MY2021_Rx" SG_ 1072 TrlrLampCnnct_B_Actl_UB 1;
BA_ "U_CD764_MY2022_Rx" SG_ 1072 StopLamp_B_RqTrlrBrk_UB 1;
BA_ "U_U55X_MY2022_Rx" SG_ 1072 StopLamp_B_RqTrlrBrk_UB 1;
BA_ "U_CD542_MY2021_Rx" SG_ 1072 StopLamp_B_RqTrlrBrk_UB 1;
BA_ "U_T6_MCA_MY2020_Rx" SG_ 1072 StopLamp_B_RqTrlrBrk_UB 1;
BA_ "U_P702_MY2021_Rx" SG_ 1072 StopLamp_B_RqTrlrBrk_UB 1;
BA_ "U_CX727_MY2021_Rx" SG_ 1072 StopLamp_B_RqTrlrBrk_UB 1;
BA_ "U_CD764_MY2022_Rx" SG_ 1072 StopLamp_B_RqTrlrBrk 1;
BA_ "U_U55X_MY2022_Rx" SG_ 1072 StopLamp_B_RqTrlrBrk 1;
BA_ "U_CD542_MY2021_Rx" SG_ 1072 StopLamp_B_RqTrlrBrk 1;
BA_ "U_T6_MCA_MY2020_Rx" SG_ 1072 StopLamp_B_RqTrlrBrk 1;
BA_ "U_P702_MY2021_Rx" SG_ 1072 StopLamp_B_RqTrlrBrk 1;
BA_ "U_CX727_MY2021_Rx" SG_ 1072 StopLamp_B_RqTrlrBrk 1;
BA_ "GenSigSendType" SG_ 1072 StopLamp_B_RqTrlrBrk 3;
BA_ "ContentDependant" SG_ 1072 StopLamp_B_RqTrlrBrk 1;
BA_ "U_CD764_MY2022_Rx" SG_ 1072 OdometerMasterValue_UB 1;
BA_ "U_U55X_MY2022_Rx" SG_ 1072 OdometerMasterValue_UB 1;
BA_ "U_CD542_MY2021_Rx" SG_ 1072 OdometerMasterValue_UB 1;
BA_ "U_T6_MCA_MY2020_Rx" SG_ 1072 OdometerMasterValue_UB 1;
BA_ "U_P702_MY2021_Rx" SG_ 1072 OdometerMasterValue_UB 1;
BA_ "U_CX727_MY2021_Rx" SG_ 1072 OdometerMasterValue_UB 1;
BA_ "U_CD764_MY2022_Rx" SG_ 1072 OdometerMasterValue 1;
BA_ "U_U55X_MY2022_Rx" SG_ 1072 OdometerMasterValue 1;
BA_ "U_CD542_MY2021_Rx" SG_ 1072 OdometerMasterValue 1;
BA_ "U_T6_MCA_MY2020_Rx" SG_ 1072 OdometerMasterValue 1;
BA_ "U_P702_MY2021_Rx" SG_ 1072 OdometerMasterValue 1;
BA_ "U_CX727_MY2021_Rx" SG_ 1072 OdometerMasterValue 1;
BA_ "GenSigSendType" SG_ 1072 OdometerMasterValue 3;
BA_ "GenSigSendType" SG_ 1072 FrostWarn_D_Stat 3;
BA_ "U_CD764_MY2022_Rx" SG_ 1072 ReducedGuard_D_Rq_UB 1;
BA_ "U_U55X_MY2022_Rx" SG_ 1072 ReducedGuard_D_Rq_UB 1;
BA_ "U_CD542_MY2021_Rx" SG_ 1072 ReducedGuard_D_Rq_UB 1;
BA_ "U_T6_MCA_MY2020_Rx" SG_ 1072 ReducedGuard_D_Rq_UB 1;
BA_ "U_P702_MY2021_Rx" SG_ 1072 ReducedGuard_D_Rq_UB 1;
BA_ "U_CX727_MY2021_Rx" SG_ 1072 ReducedGuard_D_Rq_UB 1;
BA_ "U_CD764_MY2022_Rx" SG_ 1072 ReducedGuard_D_Rq 1;
BA_ "U_U55X_MY2022_Rx" SG_ 1072 ReducedGuard_D_Rq 1;
BA_ "U_CD542_MY2021_Rx" SG_ 1072 ReducedGuard_D_Rq 1;
BA_ "U_T6_MCA_MY2020_Rx" SG_ 1072 ReducedGuard_D_Rq 1;
BA_ "U_P702_MY2021_Rx" SG_ 1072 ReducedGuard_D_Rq 1;
BA_ "U_CX727_MY2021_Rx" SG_ 1072 ReducedGuard_D_Rq 1;
BA_ "GenSigSendType" SG_ 1072 ReducedGuard_D_Rq 3;
BA_ "U_CD764_MY2022_Rx" SG_ 1072 ePRNDL_MODE 1;
BA_ "U_U55X_MY2022_Rx" SG_ 1072 ePRNDL_MODE 1;
BA_ "U_CD542_MY2021_Rx" SG_ 1072 ePRNDL_MODE 1;
BA_ "U_T6_MCA_MY2020_Rx" SG_ 1072 ePRNDL_MODE 1;
BA_ "U_P702_MY2021_Rx" SG_ 1072 ePRNDL_MODE 1;
BA_ "U_CX727_MY2021_Rx" SG_ 1072 ePRNDL_MODE 1;
BA_ "GenSigSendType" SG_ 1072 ePRNDL_MODE 3;
BA_ "WakeupSignal" SG_ 1072 ePRNDL_MODE 1;
BA_ "GenSigSendType" SG_ 1072 EngOilLife_B_RqReset 3;
BA_ "U_U55X_MY2022_Rx" SG_ 1072 Outside_Air_Temp_Stat_UB 1;
BA_ "U_U55X_MY2022_Rx" SG_ 1072 Outside_Air_Temp_Stat 1;
BA_ "GenSigSendType" SG_ 1072 Outside_Air_Temp_Stat 3;
BA_ "GenSigStartValue" SG_ 1072 Outside_Air_Temp_Stat 254;
BA_ "GenSigStartValueInteger" SG_ 1072 Outside_Air_Temp_Stat 254;
BA_ "U_CD764_MY2022_Rx" SG_ 1072 KeyTypeChngMykey_D_Rq_UB 1;
BA_ "U_U55X_MY2022_Rx" SG_ 1072 KeyTypeChngMykey_D_Rq_UB 1;
BA_ "U_CD542_MY2021_Rx" SG_ 1072 KeyTypeChngMykey_D_Rq_UB 1;
BA_ "U_T6_MCA_MY2020_Rx" SG_ 1072 KeyTypeChngMykey_D_Rq_UB 1;
BA_ "U_P702_MY2021_Rx" SG_ 1072 KeyTypeChngMykey_D_Rq_UB 1;
BA_ "U_CX727_MY2021_Rx" SG_ 1072 KeyTypeChngMykey_D_Rq_UB 1;
BA_ "U_CD764_MY2022_Rx" SG_ 1072 KeyTypeChngMykey_D_Rq 1;
BA_ "U_U55X_MY2022_Rx" SG_ 1072 KeyTypeChngMykey_D_Rq 1;
BA_ "U_CD542_MY2021_Rx" SG_ 1072 KeyTypeChngMykey_D_Rq 1;
BA_ "U_T6_MCA_MY2020_Rx" SG_ 1072 KeyTypeChngMykey_D_Rq 1;
BA_ "U_P702_MY2021_Rx" SG_ 1072 KeyTypeChngMykey_D_Rq 1;
BA_ "U_CX727_MY2021_Rx" SG_ 1072 KeyTypeChngMykey_D_Rq 1;
BA_ "GenSigSendType" SG_ 1072 KeyTypeChngMykey_D_Rq 3;
BA_ "U_CD764_MY2022_Rx" SG_ 1072 TrlrLampCnnct_B_Actl 1;
BA_ "U_U55X_MY2022_Rx" SG_ 1072 TrlrLampCnnct_B_Actl 1;
BA_ "U_CD542_MY2021_Rx" SG_ 1072 TrlrLampCnnct_B_Actl 1;
BA_ "U_T6_MCA_MY2020_Rx" SG_ 1072 TrlrLampCnnct_B_Actl 1;
BA_ "U_P702_MY2021_Rx" SG_ 1072 TrlrLampCnnct_B_Actl 1;
BA_ "U_CX727_MY2021_Rx" SG_ 1072 TrlrLampCnnct_B_Actl 1;
BA_ "GenSigSendType" SG_ 1072 TrlrLampCnnct_B_Actl 3;
BA_ "GenSigSendType" SG_ 2002 TesterPhysicalReqGFM2 3;
BA_ "U_CD764_MY2022_Tx" SG_ 1438 GWM_GWOnBoardTester 1;
BA_ "U_U55X_MY2022_Tx" SG_ 1438 GWM_GWOnBoardTester 1;
BA_ "U_CD542_MY2021_Tx" SG_ 1438 GWM_GWOnBoardTester 1;
BA_ "ECGUsedTxSignal" SG_ 1438 GWM_GWOnBoardTester 1;
BA_ "U_T6_MCA_MY2020_Tx" SG_ 1438 GWM_GWOnBoardTester 1;
BA_ "U_CD764_MY2022_Rx" SG_ 1438 GWM_GWOnBoardTester 1;
BA_ "U_U55X_MY2022_Rx" SG_ 1438 GWM_GWOnBoardTester 1;
BA_ "U_CD542_MY2021_Rx" SG_ 1438 GWM_GWOnBoardTester 1;
BA_ "U_T6_MCA_MY2020_Rx" SG_ 1438 GWM_GWOnBoardTester 1;
BA_ "U_P702_MY2021_Rx" SG_ 1438 GWM_GWOnBoardTester 1;
BA_ "U_CX727_MY2021_Rx" SG_ 1438 GWM_GWOnBoardTester 1;
BA_ "GenSigStartValue" SG_ 1438 GWM_GWOnBoardTester 255;
BA_ "ContentDependant" SG_ 1438 GWM_GWOnBoardTester 1;
BA_ "GenSigStartValueInteger" SG_ 1438 GWM_GWOnBoardTester 255;
BA_ "U_CD764_MY2022_Tx" SG_ 1438 GWM_GWNMProxy 1;
BA_ "U_U55X_MY2022_Tx" SG_ 1438 GWM_GWNMProxy 1;
BA_ "U_CD542_MY2021_Tx" SG_ 1438 GWM_GWNMProxy 1;
BA_ "ECGUsedTxSignal" SG_ 1438 GWM_GWNMProxy 1;
BA_ "U_T6_MCA_MY2020_Tx" SG_ 1438 GWM_GWNMProxy 1;
BA_ "U_CD764_MY2022_Rx" SG_ 1438 GWM_GWNMProxy 1;
BA_ "U_U55X_MY2022_Rx" SG_ 1438 GWM_GWNMProxy 1;
BA_ "U_CD542_MY2021_Rx" SG_ 1438 GWM_GWNMProxy 1;
BA_ "U_T6_MCA_MY2020_Rx" SG_ 1438 GWM_GWNMProxy 1;
BA_ "U_P702_MY2021_Rx" SG_ 1438 GWM_GWNMProxy 1;
BA_ "U_CX727_MY2021_Rx" SG_ 1438 GWM_GWNMProxy 1;
BA_ "GenSigStartValue" SG_ 1438 GWM_GWNMProxy 255;
BA_ "ContentDependant" SG_ 1438 GWM_GWNMProxy 1;
BA_ "GenSigStartValueInteger" SG_ 1438 GWM_GWNMProxy 255;
BA_ "U_CD764_MY2022_Tx" SG_ 1438 GWM_AutoSarNMReserved4 1;
BA_ "U_U55X_MY2022_Tx" SG_ 1438 GWM_AutoSarNMReserved4 1;
BA_ "U_CD542_MY2021_Tx" SG_ 1438 GWM_AutoSarNMReserved4 1;
BA_ "ECGUsedTxSignal" SG_ 1438 GWM_AutoSarNMReserved4 1;
BA_ "U_T6_MCA_MY2020_Tx" SG_ 1438 GWM_AutoSarNMReserved4 1;
BA_ "U_CD764_MY2022_Rx" SG_ 1438 GWM_AutoSarNMReserved4 1;
BA_ "U_U55X_MY2022_Rx" SG_ 1438 GWM_AutoSarNMReserved4 1;
BA_ "U_CD542_MY2021_Rx" SG_ 1438 GWM_AutoSarNMReserved4 1;
BA_ "U_T6_MCA_MY2020_Rx" SG_ 1438 GWM_AutoSarNMReserved4 1;
BA_ "U_P702_MY2021_Rx" SG_ 1438 GWM_AutoSarNMReserved4 1;
BA_ "U_CX727_MY2021_Rx" SG_ 1438 GWM_AutoSarNMReserved4 1;
BA_ "GenSigStartValue" SG_ 1438 GWM_AutoSarNMReserved4 255;
BA_ "ContentDependant" SG_ 1438 GWM_AutoSarNMReserved4 1;
BA_ "GenSigStartValueInteger" SG_ 1438 GWM_AutoSarNMReserved4 255;
BA_ "U_CD764_MY2022_Tx" SG_ 1438 GWM_AutoSarNMReserved3 1;
BA_ "U_U55X_MY2022_Tx" SG_ 1438 GWM_AutoSarNMReserved3 1;
BA_ "U_CD542_MY2021_Tx" SG_ 1438 GWM_AutoSarNMReserved3 1;
BA_ "ECGUsedTxSignal" SG_ 1438 GWM_AutoSarNMReserved3 1;
BA_ "U_T6_MCA_MY2020_Tx" SG_ 1438 GWM_AutoSarNMReserved3 1;
BA_ "U_CD764_MY2022_Rx" SG_ 1438 GWM_AutoSarNMReserved3 1;
BA_ "U_U55X_MY2022_Rx" SG_ 1438 GWM_AutoSarNMReserved3 1;
BA_ "U_CD542_MY2021_Rx" SG_ 1438 GWM_AutoSarNMReserved3 1;
BA_ "U_T6_MCA_MY2020_Rx" SG_ 1438 GWM_AutoSarNMReserved3 1;
BA_ "U_P702_MY2021_Rx" SG_ 1438 GWM_AutoSarNMReserved3 1;
BA_ "U_CX727_MY2021_Rx" SG_ 1438 GWM_AutoSarNMReserved3 1;
BA_ "GenSigStartValue" SG_ 1438 GWM_AutoSarNMReserved3 255;
BA_ "ContentDependant" SG_ 1438 GWM_AutoSarNMReserved3 1;
BA_ "GenSigStartValueInteger" SG_ 1438 GWM_AutoSarNMReserved3 255;
BA_ "U_CD764_MY2022_Tx" SG_ 1438 GWM_AutoSarNMReserved2 1;
BA_ "U_U55X_MY2022_Tx" SG_ 1438 GWM_AutoSarNMReserved2 1;
BA_ "U_CD542_MY2021_Tx" SG_ 1438 GWM_AutoSarNMReserved2 1;
BA_ "ECGUsedTxSignal" SG_ 1438 GWM_AutoSarNMReserved2 1;
BA_ "U_T6_MCA_MY2020_Tx" SG_ 1438 GWM_AutoSarNMReserved2 1;
BA_ "U_CD764_MY2022_Rx" SG_ 1438 GWM_AutoSarNMReserved2 1;
BA_ "U_U55X_MY2022_Rx" SG_ 1438 GWM_AutoSarNMReserved2 1;
BA_ "U_CD542_MY2021_Rx" SG_ 1438 GWM_AutoSarNMReserved2 1;
BA_ "U_T6_MCA_MY2020_Rx" SG_ 1438 GWM_AutoSarNMReserved2 1;
BA_ "U_P702_MY2021_Rx" SG_ 1438 GWM_AutoSarNMReserved2 1;
BA_ "U_CX727_MY2021_Rx" SG_ 1438 GWM_AutoSarNMReserved2 1;
BA_ "GenSigStartValue" SG_ 1438 GWM_AutoSarNMReserved2 255;
BA_ "ContentDependant" SG_ 1438 GWM_AutoSarNMReserved2 1;
BA_ "GenSigStartValueInteger" SG_ 1438 GWM_AutoSarNMReserved2 255;
BA_ "U_CD764_MY2022_Tx" SG_ 1438 GWM_AutoSarNMReserved1 1;
BA_ "U_U55X_MY2022_Tx" SG_ 1438 GWM_AutoSarNMReserved1 1;
BA_ "U_CD542_MY2021_Tx" SG_ 1438 GWM_AutoSarNMReserved1 1;
BA_ "ECGUsedTxSignal" SG_ 1438 GWM_AutoSarNMReserved1 1;
BA_ "U_T6_MCA_MY2020_Tx" SG_ 1438 GWM_AutoSarNMReserved1 1;
BA_ "U_CD764_MY2022_Rx" SG_ 1438 GWM_AutoSarNMReserved1 1;
BA_ "U_U55X_MY2022_Rx" SG_ 1438 GWM_AutoSarNMReserved1 1;
BA_ "U_CD542_MY2021_Rx" SG_ 1438 GWM_AutoSarNMReserved1 1;
BA_ "U_T6_MCA_MY2020_Rx" SG_ 1438 GWM_AutoSarNMReserved1 1;
BA_ "U_P702_MY2021_Rx" SG_ 1438 GWM_AutoSarNMReserved1 1;
BA_ "U_CX727_MY2021_Rx" SG_ 1438 GWM_AutoSarNMReserved1 1;
BA_ "GenSigStartValue" SG_ 1438 GWM_AutoSarNMReserved1 255;
BA_ "ContentDependant" SG_ 1438 GWM_AutoSarNMReserved1 1;
BA_ "GenSigStartValueInteger" SG_ 1438 GWM_AutoSarNMReserved1 255;
BA_ "U_CD764_MY2022_Tx" SG_ 1438 GWM_AutoSarNMNodeId 1;
BA_ "U_U55X_MY2022_Tx" SG_ 1438 GWM_AutoSarNMNodeId 1;
BA_ "U_CD542_MY2021_Tx" SG_ 1438 GWM_AutoSarNMNodeId 1;
BA_ "ECGUsedTxSignal" SG_ 1438 GWM_AutoSarNMNodeId 1;
BA_ "U_T6_MCA_MY2020_Tx" SG_ 1438 GWM_AutoSarNMNodeId 1;
BA_ "U_CD764_MY2022_Rx" SG_ 1438 GWM_AutoSarNMNodeId 1;
BA_ "U_U55X_MY2022_Rx" SG_ 1438 GWM_AutoSarNMNodeId 1;
BA_ "U_CD542_MY2021_Rx" SG_ 1438 GWM_AutoSarNMNodeId 1;
BA_ "U_T6_MCA_MY2020_Rx" SG_ 1438 GWM_AutoSarNMNodeId 1;
BA_ "U_P702_MY2021_Rx" SG_ 1438 GWM_AutoSarNMNodeId 1;
BA_ "U_CX727_MY2021_Rx" SG_ 1438 GWM_AutoSarNMNodeId 1;
BA_ "GenSigStartValue" SG_ 1438 GWM_AutoSarNMNodeId 158;
BA_ "ContentDependant" SG_ 1438 GWM_AutoSarNMNodeId 1;
BA_ "GenSigStartValueInteger" SG_ 1438 GWM_AutoSarNMNodeId 158;
BA_ "U_CD764_MY2022_Tx" SG_ 1438 GWM_AutoSarNMControl 1;
BA_ "U_U55X_MY2022_Tx" SG_ 1438 GWM_AutoSarNMControl 1;
BA_ "U_CD542_MY2021_Tx" SG_ 1438 GWM_AutoSarNMControl 1;
BA_ "ECGUsedTxSignal" SG_ 1438 GWM_AutoSarNMControl 1;
BA_ "U_T6_MCA_MY2020_Tx" SG_ 1438 GWM_AutoSarNMControl 1;
BA_ "U_CD764_MY2022_Rx" SG_ 1438 GWM_AutoSarNMControl 1;
BA_ "U_U55X_MY2022_Rx" SG_ 1438 GWM_AutoSarNMControl 1;
BA_ "U_CD542_MY2021_Rx" SG_ 1438 GWM_AutoSarNMControl 1;
BA_ "U_T6_MCA_MY2020_Rx" SG_ 1438 GWM_AutoSarNMControl 1;
BA_ "U_P702_MY2021_Rx" SG_ 1438 GWM_AutoSarNMControl 1;
BA_ "U_CX727_MY2021_Rx" SG_ 1438 GWM_AutoSarNMControl 1;
BA_ "ContentDependant" SG_ 1438 GWM_AutoSarNMControl 1;
BA_ "U_U55X_MY2022_Tx" SG_ 1067 BattULoAux_U_Rq 1;
BA_ "U_T6_MCA_MY2020_Tx" SG_ 1067 BattULoAux_U_Rq 1;
BA_ "U_P702_MY2021_Tx" SG_ 1067 BattULoAux_U_Rq 1;
BA_ "GenSigStartValue" SG_ 1067 BattULoAux_U_Rq 3296;
BA_ "U_U55X_MY2022_Tx" SG_ 1067 BattULoAuxIsol_D_Rq 1;
BA_ "U_T6_MCA_MY2020_Tx" SG_ 1067 BattULoAuxIsol_D_Rq 1;
BA_ "U_P702_MY2021_Tx" SG_ 1067 BattULoAuxIsol_D_Rq 1;
BA_ "GenSigStartValue" SG_ 1067 BattULoAuxIsol_D_Rq 2;
BA_ "GenSigStartValueInteger" SG_ 1067 BattULoAuxIsol_D_Rq 2;
BA_ "U_CD764_MY2022_Tx" SG_ 1067 BattULoAuxSoc_Pc_Actl 1;
BA_ "U_U55X_MY2022_Tx" SG_ 1067 BattULoAuxSoc_Pc_Actl 1;
BA_ "U_T6_MCA_MY2020_Tx" SG_ 1067 BattULoAuxSoc_Pc_Actl 1;
BA_ "U_P702_MY2021_Tx" SG_ 1067 BattULoAuxSoc_Pc_Actl 1;
BA_ "U_CX727_MY2021_Tx" SG_ 1067 BattULoAuxSoc_Pc_Actl 1;
BA_ "GenSigStartValue" SG_ 1067 BattULoAuxSoc_Pc_Actl 95;
BA_ "GenSigStartValueInteger" SG_ 1067 BattULoAuxSoc_Pc_Actl 95;
BA_ "U_CD764_MY2022_Tx" SG_ 1067 BattULoAux_I_Actl 1;
BA_ "U_U55X_MY2022_Tx" SG_ 1067 BattULoAux_I_Actl 1;
BA_ "U_T6_MCA_MY2020_Tx" SG_ 1067 BattULoAux_I_Actl 1;
BA_ "U_P702_MY2021_Tx" SG_ 1067 BattULoAux_I_Actl 1;
BA_ "U_CX727_MY2021_Tx" SG_ 1067 BattULoAux_I_Actl 1;
BA_ "GenSigStartValueInteger" SG_ 1067 BattULoAux_I_Actl 2048;
BA_ "U_CD764_MY2022_Tx" SG_ 1067 BattULoAux_D_Qlty 1;
BA_ "U_U55X_MY2022_Tx" SG_ 1067 BattULoAux_D_Qlty 1;
BA_ "U_T6_MCA_MY2020_Tx" SG_ 1067 BattULoAux_D_Qlty 1;
BA_ "U_P702_MY2021_Tx" SG_ 1067 BattULoAux_D_Qlty 1;
BA_ "U_CX727_MY2021_Tx" SG_ 1067 BattULoAux_D_Qlty 1;
BA_ "U_CD764_MY2022_Tx" SG_ 1067 BattULoCrnkStrt_U_Pred 1;
BA_ "U_U55X_MY2022_Tx" SG_ 1067 BattULoCrnkStrt_U_Pred 1;
BA_ "U_T6_MCA_MY2020_Tx" SG_ 1067 BattULoCrnkStrt_U_Pred 1;
BA_ "U_P702_MY2021_Tx" SG_ 1067 BattULoCrnkStrt_U_Pred 1;
BA_ "U_CX727_MY2021_Tx" SG_ 1067 BattULoCrnkStrt_U_Pred 1;
BA_ "U_CD764_MY2022_Tx" SG_ 1067 BattULoCrnkBelt_U_Pred 1;
BA_ "U_U55X_MY2022_Tx" SG_ 1067 BattULoCrnkBelt_U_Pred 1;
BA_ "U_T6_MCA_MY2020_Tx" SG_ 1067 BattULoCrnkBelt_U_Pred 1;
BA_ "U_P702_MY2021_Tx" SG_ 1067 BattULoCrnkBelt_U_Pred 1;
BA_ "U_CX727_MY2021_Tx" SG_ 1067 BattULoCrnkBelt_U_Pred 1;
BA_ "U_CD764_MY2022_Tx" SG_ 1067 BattULoAux_U_Actl 1;
BA_ "U_U55X_MY2022_Tx" SG_ 1067 BattULoAux_U_Actl 1;
BA_ "U_T6_MCA_MY2020_Tx" SG_ 1067 BattULoAux_U_Actl 1;
BA_ "U_P702_MY2021_Tx" SG_ 1067 BattULoAux_U_Actl 1;
BA_ "U_CX727_MY2021_Tx" SG_ 1067 BattULoAux_U_Actl 1;
BA_ "GenSigStartValue" SG_ 1067 BattULoAux_U_Actl 203;
BA_ "GenSigStartValueInteger" SG_ 1067 BattULoAux_U_Actl 203;
BA_ "U_CD764_MY2022_Tx" SG_ 1067 BattULoAux_B_Falt 1;
BA_ "U_U55X_MY2022_Tx" SG_ 1067 BattULoAux_B_Falt 1;
BA_ "U_T6_MCA_MY2020_Tx" SG_ 1067 BattULoAux_B_Falt 1;
BA_ "U_P702_MY2021_Tx" SG_ 1067 BattULoAux_B_Falt 1;
BA_ "U_CX727_MY2021_Tx" SG_ 1067 BattULoAux_B_Falt 1;
BA_ "WakeupSignal" SG_ 588 HvacAirFlw_B_RqBatt 1;
BA_ "U_CD542_MY2021_Tx" SG_ 588 BattChrgRdyStat_D_Actl 1;
BA_ "U_CX727_MY2021_Tx" SG_ 588 BattChrgRdyStat_D_Actl 1;
BA_ "U_CD542_MY2021_Rx" SG_ 588 BattChrgRdyStat_D_Actl 1;
BA_ "U_CX727_MY2021_Rx" SG_ 588 BattChrgRdyStat_D_Actl 1;
BA_ "U_CD542_MY2021_Tx" SG_ 588 BattTracSoc2_Pc_Actl 1;
BA_ "U_P702_MY2021_Tx" SG_ 588 BattTracSoc2_Pc_Actl 1;
BA_ "U_CX727_MY2021_Tx" SG_ 588 BattTracSoc2_Pc_Actl 1;
BA_ "U_U55X_MY2022_Rx" SG_ 588 BattTracSoc2_Pc_Actl 1;
BA_ "U_CD542_MY2021_Rx" SG_ 588 BattTracSoc2_Pc_Actl 1;
BA_ "ECGUsedRxSignal" SG_ 588 BattTracSoc2_Pc_Actl 1;
BA_ "GenSigStartValue" SG_ 588 BattTracSoc2_Pc_Actl 16382;
BA_ "GenSigStartValueInteger" SG_ 588 BattTracSoc2_Pc_Actl 16382;
BA_ "U_CD542_MY2021_Tx" SG_ 588 BattTracSoc_Pc_Dsply 1;
BA_ "U_CX727_MY2021_Tx" SG_ 588 BattTracSoc_Pc_Dsply 1;
BA_ "U_U55X_MY2022_Rx" SG_ 588 BattTracSoc_Pc_Dsply 1;
BA_ "ECGUsedRxSignal" SG_ 588 BattTracSoc_Pc_Dsply 1;
BA_ "U_CD542_MY2021_Rx" SG_ 588 BattTracSoc_Pc_Dsply 1;
BA_ "U_CX727_MY2021_Rx" SG_ 588 BattTracSoc_Pc_Dsply 1;
BA_ "GenSigStartValue" SG_ 588 BattTracSoc_Pc_Dsply 254;
BA_ "GenSigStartValueInteger" SG_ 588 BattTracSoc_Pc_Dsply 254;
BA_ "GenSigStartValue" SG_ 588 BattTracClntIn_Te_Actl 75;
BA_ "GenSigStartValueInteger" SG_ 588 BattTracClntIn_Te_Actl 75;
BA_ "U_CD542_MY2021_Tx" SG_ 588 BattTrac_Te_Actl 1;
BA_ "U_P702_MY2021_Tx" SG_ 588 BattTrac_Te_Actl 1;
BA_ "U_CX727_MY2021_Tx" SG_ 588 BattTrac_Te_Actl 1;
BA_ "U_U55X_MY2022_Rx" SG_ 588 BattTrac_Te_Actl 1;
BA_ "U_CD542_MY2021_Rx" SG_ 588 BattTrac_Te_Actl 1;
BA_ "ECGUsedRxSignal" SG_ 588 BattTrac_Te_Actl 1;
BA_ "GenSigStartValue" SG_ 588 BattTrac_Te_Actl 150;
BA_ "GenSigStartValueInteger" SG_ 588 BattTrac_Te_Actl 150;
BA_ "GenSigStartValue" SG_ 588 HvacRec_D_RqMxBatt 10;
BA_ "GenSigStartValueInteger" SG_ 588 HvacRec_D_RqMxBatt 10;
BA_ "U_CD542_MY2021_Tx" SG_ 122 BattTrac_U_LimLo 1;
BA_ "U_P702_MY2021_Tx" SG_ 122 BattTrac_U_LimLo 1;
BA_ "U_CX727_MY2021_Tx" SG_ 122 BattTrac_U_LimLo 1;
BA_ "U_CX727_MY2021_Rx" SG_ 122 BattTrac_U_LimLo 1;
BA_ "GenSigStartValue" SG_ 122 BattTrac_U_LimLo 88;
BA_ "GenSigStartValueInteger" SG_ 122 BattTrac_U_LimLo 88;
BA_ "U_CD542_MY2021_Tx" SG_ 122 BattTrac_U_LimHi 1;
BA_ "U_P702_MY2021_Tx" SG_ 122 BattTrac_U_LimHi 1;
BA_ "U_CX727_MY2021_Tx" SG_ 122 BattTrac_U_LimHi 1;
BA_ "U_CX727_MY2021_Rx" SG_ 122 BattTrac_U_LimHi 1;
BA_ "GenSigStartValue" SG_ 122 BattTrac_U_LimHi 163;
BA_ "GenSigStartValueInteger" SG_ 122 BattTrac_U_LimHi 163;
BA_ "U_CD542_MY2021_Tx" SG_ 122 VehStrtInhbt_B_RqBatt 1;
BA_ "U_P702_MY2021_Tx" SG_ 122 VehStrtInhbt_B_RqBatt 1;
BA_ "U_CX727_MY2021_Tx" SG_ 122 VehStrtInhbt_B_RqBatt 1;
BA_ "U_CD542_MY2021_Tx" SG_ 122 BattTracOffFst_D_Actl 1;
BA_ "U_P702_MY2021_Tx" SG_ 122 BattTracOffFst_D_Actl 1;
BA_ "U_CX727_MY2021_Tx" SG_ 122 BattTracOffFst_D_Actl 1;
BA_ "U_CD542_MY2021_Rx" SG_ 122 BattTracOffFst_D_Actl 1;
BA_ "U_P702_MY2021_Rx" SG_ 122 BattTracOffFst_D_Actl 1;
BA_ "U_CX727_MY2021_Rx" SG_ 122 BattTracOffFst_D_Actl 1;
BA_ "U_CD542_MY2021_Tx" SG_ 122 BattTracOff_B_Actl 1;
BA_ "U_P702_MY2021_Tx" SG_ 122 BattTracOff_B_Actl 1;
BA_ "U_CX727_MY2021_Tx" SG_ 122 BattTracOff_B_Actl 1;
BA_ "U_U55X_MY2022_Rx" SG_ 122 BattTracOff_B_Actl 1;
BA_ "ECGUsedRxSignal" SG_ 122 BattTracOff_B_Actl 1;
BA_ "U_CD542_MY2021_Rx" SG_ 122 BattTracOff_B_Actl 1;
BA_ "U_CX727_MY2021_Rx" SG_ 122 BattTracOff_B_Actl 1;
BA_ "U_CD542_MY2021_Tx" SG_ 122 BattTracMil_D_Rq 1;
BA_ "U_P702_MY2021_Tx" SG_ 122 BattTracMil_D_Rq 1;
BA_ "U_CX727_MY2021_Tx" SG_ 122 BattTracMil_D_Rq 1;
BA_ "U_U55X_MY2022_Rx" SG_ 122 BattTracMil_D_Rq 1;
BA_ "U_CD542_MY2021_Rx" SG_ 122 BattTracMil_D_Rq 1;
BA_ "ECGUsedRxSignal" SG_ 122 BattTracMil_D_Rq 1;
BA_ "U_CX727_MY2021_Rx" SG_ 122 BattTracCnnct_B_Cmd 1;
BA_ "U_CD542_MY2021_Tx" SG_ 122 BattTrac_U_Actl 1;
BA_ "U_P702_MY2021_Tx" SG_ 122 BattTrac_U_Actl 1;
BA_ "U_CX727_MY2021_Tx" SG_ 122 BattTrac_U_Actl 1;
BA_ "U_U55X_MY2022_Rx" SG_ 122 BattTrac_U_Actl 1;
BA_ "ECGUsedRxSignal" SG_ 122 BattTrac_U_Actl 1;
BA_ "U_CD542_MY2021_Rx" SG_ 122 BattTrac_U_Actl 1;
BA_ "U_P702_MY2021_Rx" SG_ 122 BattTrac_U_Actl 1;
BA_ "U_CX727_MY2021_Rx" SG_ 122 BattTrac_U_Actl 1;
BA_ "GenSigStartValue" SG_ 122 BattTrac_U_Actl 1022;
BA_ "GenSigStartValueInteger" SG_ 122 BattTrac_U_Actl 1022;
BA_ "U_CD542_MY2021_Tx" SG_ 122 BattTrac_I_Actl 1;
BA_ "U_P702_MY2021_Tx" SG_ 122 BattTrac_I_Actl 1;
BA_ "U_CX727_MY2021_Tx" SG_ 122 BattTrac_I_Actl 1;
BA_ "U_U55X_MY2022_Rx" SG_ 122 BattTrac_I_Actl 1;
BA_ "ECGUsedRxSignal" SG_ 122 BattTrac_I_Actl 1;
BA_ "U_CD542_MY2021_Rx" SG_ 122 BattTrac_I_Actl 1;
BA_ "U_CX727_MY2021_Rx" SG_ 122 BattTrac_I_Actl 1;
BA_ "GenSigStartValueInteger" SG_ 122 BattTrac_I_Actl 15000;
BA_ "U_CD764_MY2022_Rx" SG_ 1814 TesterPhysicalReqGWM_H1 1;
BA_ "U_U55X_MY2022_Rx" SG_ 1814 TesterPhysicalReqGWM_H1 1;
BA_ "U_CD542_MY2021_Rx" SG_ 1814 TesterPhysicalReqGWM_H1 1;
BA_ "ECGUsedRxSignal" SG_ 1814 TesterPhysicalReqGWM_H1 1;
BA_ "U_T6_MCA_MY2020_Rx" SG_ 1814 TesterPhysicalReqGWM_H1 1;
BA_ "GenSigSendType" SG_ 1814 TesterPhysicalReqGWM_H1 3;
BA_ "U_CD764_MY2022_Tx" SG_ 1822 TesterPhysicalResGWM_H1 1;
BA_ "U_U55X_MY2022_Tx" SG_ 1822 TesterPhysicalResGWM_H1 1;
BA_ "U_CD542_MY2021_Tx" SG_ 1822 TesterPhysicalResGWM_H1 1;
BA_ "ECGUsedTxSignal" SG_ 1822 TesterPhysicalResGWM_H1 1;
BA_ "U_T6_MCA_MY2020_Tx" SG_ 1822 TesterPhysicalResGWM_H1 1;
BA_ "GenSigSendType" SG_ 1822 TesterPhysicalResGWM_H1 3;
BA_ "U_CD764_MY2022_Rx" SG_ 806 SnowPlowMde_B_Enbl 1;
BA_ "U_U55X_MY2022_Rx" SG_ 806 SnowPlowMde_B_Enbl 1;
BA_ "U_CD542_MY2021_Rx" SG_ 806 SnowPlowMde_B_Enbl 1;
BA_ "U_T6_MCA_MY2020_Rx" SG_ 806 SnowPlowMde_B_Enbl 1;
BA_ "U_P702_MY2021_Rx" SG_ 806 SnowPlowMde_B_Enbl 1;
BA_ "U_CX727_MY2021_Rx" SG_ 806 SnowPlowMde_B_Enbl 1;
BA_ "GenSigStartValueInteger" SG_ 806 HvacEvap_Te_Rq 400;
BA_ "GenSigStartValueInteger" SG_ 806 HvacEvap_Te_Actl 400;
BA_ "GenSigStartValueInteger" SG_ 806 HvacEvap_Te_Offst 400;
BA_ "GenSigStartValueInteger" SG_ 806 ClimtDeltaLoad_Pw_Actl 32;
BA_ "U_CD764_MY2022_Tx" SG_ 578 PtLatchActv_B_RqBcm 1;
BA_ "U_U55X_MY2022_Tx" SG_ 578 PtLatchActv_B_RqBcm 1;
BA_ "U_CD542_MY2021_Tx" SG_ 578 PtLatchActv_B_RqBcm 1;
BA_ "U_T6_MCA_MY2020_Tx" SG_ 578 PtLatchActv_B_RqBcm 1;
BA_ "U_P702_MY2021_Tx" SG_ 578 PtLatchActv_B_RqBcm 1;
BA_ "U_CX727_MY2021_Tx" SG_ 578 PtLatchActv_B_RqBcm 1;
BA_ "U_CD764_MY2022_Tx" SG_ 578 immoSecureIdleMode 1;
BA_ "U_U55X_MY2022_Tx" SG_ 578 immoSecureIdleMode 1;
BA_ "U_CD542_MY2021_Tx" SG_ 578 immoSecureIdleMode 1;
BA_ "U_T6_MCA_MY2020_Tx" SG_ 578 immoSecureIdleMode 1;
BA_ "U_P702_MY2021_Tx" SG_ 578 immoSecureIdleMode 1;
BA_ "U_CX727_MY2021_Tx" SG_ 578 immoSecureIdleMode 1;
BA_ "U_CX727_MY2021_Rx" SG_ 578 immoSecureIdleMode 1;
BA_ "U_CD764_MY2022_Tx" SG_ 578 ReFuelSwtchStat_D_Actl 1;
BA_ "U_U55X_MY2022_Tx" SG_ 578 ReFuelSwtchStat_D_Actl 1;
BA_ "U_CD542_MY2021_Tx" SG_ 578 ReFuelSwtchStat_D_Actl 1;
BA_ "U_T6_MCA_MY2020_Tx" SG_ 578 ReFuelSwtchStat_D_Actl 1;
BA_ "U_P702_MY2021_Tx" SG_ 578 ReFuelSwtchStat_D_Actl 1;
BA_ "U_CX727_MY2021_Tx" SG_ 578 ReFuelSwtchStat_D_Actl 1;
BA_ "WakeupSignal" SG_ 578 ReFuelSwtchStat_D_Actl 1;
BA_ "U_CD764_MY2022_Tx" SG_ 578 FuelPumpPwr_D_Stat 1;
BA_ "U_U55X_MY2022_Tx" SG_ 578 FuelPumpPwr_D_Stat 1;
BA_ "U_CD542_MY2021_Tx" SG_ 578 FuelPumpPwr_D_Stat 1;
BA_ "U_T6_MCA_MY2020_Tx" SG_ 578 FuelPumpPwr_D_Stat 1;
BA_ "U_P702_MY2021_Tx" SG_ 578 FuelPumpPwr_D_Stat 1;
BA_ "U_CX727_MY2021_Tx" SG_ 578 FuelPumpPwr_D_Stat 1;
BA_ "U_CD764_MY2022_Tx" SG_ 578 BattULo_U_Actl 1;
BA_ "U_U55X_MY2022_Tx" SG_ 578 BattULo_U_Actl 1;
BA_ "U_CD542_MY2021_Tx" SG_ 578 BattULo_U_Actl 1;
BA_ "U_T6_MCA_MY2020_Tx" SG_ 578 BattULo_U_Actl 1;
BA_ "U_P702_MY2021_Tx" SG_ 578 BattULo_U_Actl 1;
BA_ "U_CX727_MY2021_Tx" SG_ 578 BattULo_U_Actl 1;
BA_ "U_U55X_MY2022_Rx" SG_ 578 BattULo_U_Actl 1;
BA_ "ECGUsedRxSignal" SG_ 578 BattULo_U_Actl 1;
BA_ "U_T6_MCA_MY2020_Rx" SG_ 578 BattULo_U_Actl 1;
BA_ "U_CD542_MY2021_Rx" SG_ 578 BattULo_U_Actl 1;
BA_ "U_P702_MY2021_Rx" SG_ 578 BattULo_U_Actl 1;
BA_ "U_CX727_MY2021_Rx" SG_ 578 BattULo_U_Actl 1;
BA_ "GenSigStartValue" SG_ 578 BattULo_U_Actl 255;
BA_ "GenSigStartValueInteger" SG_ 578 BattULo_U_Actl 255;
BA_ "U_CD764_MY2022_Tx" SG_ 578 PrkLckCtl_B_Enbl 1;
BA_ "U_U55X_MY2022_Tx" SG_ 578 PrkLckCtl_B_Enbl 1;
BA_ "U_CD542_MY2021_Tx" SG_ 578 PrkLckCtl_B_Enbl 1;
BA_ "U_T6_MCA_MY2020_Tx" SG_ 578 PrkLckCtl_B_Enbl 1;
BA_ "U_P702_MY2021_Tx" SG_ 578 PrkLckCtl_B_Enbl 1;
BA_ "U_CX727_MY2021_Tx" SG_ 578 PrkLckCtl_B_Enbl 1;
BA_ "U_CD764_MY2022_Tx" SG_ 578 PrkLckCtlMsgTxt_D_Rq 1;
BA_ "U_U55X_MY2022_Tx" SG_ 578 PrkLckCtlMsgTxt_D_Rq 1;
BA_ "U_CD542_MY2021_Tx" SG_ 578 PrkLckCtlMsgTxt_D_Rq 1;
BA_ "U_T6_MCA_MY2020_Tx" SG_ 578 PrkLckCtlMsgTxt_D_Rq 1;
BA_ "U_P702_MY2021_Tx" SG_ 578 PrkLckCtlMsgTxt_D_Rq 1;
BA_ "U_CX727_MY2021_Tx" SG_ 578 PrkLckCtlMsgTxt_D_Rq 1;
BA_ "WakeupSignal" SG_ 578 PrkLckCtlMsgTxt_D_Rq 1;
BA_ "U_CD764_MY2022_Tx" SG_ 578 PrkLckCtlAvail_T_Stat 1;
BA_ "U_U55X_MY2022_Tx" SG_ 578 PrkLckCtlAvail_T_Stat 1;
BA_ "U_CD542_MY2021_Tx" SG_ 578 PrkLckCtlAvail_T_Stat 1;
BA_ "U_T6_MCA_MY2020_Tx" SG_ 578 PrkLckCtlAvail_T_Stat 1;
BA_ "U_P702_MY2021_Tx" SG_ 578 PrkLckCtlAvail_T_Stat 1;
BA_ "U_CX727_MY2021_Tx" SG_ 578 PrkLckCtlAvail_T_Stat 1;
BA_ "WakeupSignal" SG_ 578 PrkLckCtlAvail_T_Stat 1;
BA_ "U_CD764_MY2022_Tx" SG_ 578 BrkTrnShifLck_B_Stat 1;
BA_ "U_U55X_MY2022_Tx" SG_ 578 BrkTrnShifLck_B_Stat 1;
BA_ "U_CD542_MY2021_Tx" SG_ 578 BrkTrnShifLck_B_Stat 1;
BA_ "U_T6_MCA_MY2020_Tx" SG_ 578 BrkTrnShifLck_B_Stat 1;
BA_ "U_P702_MY2021_Tx" SG_ 578 BrkTrnShifLck_B_Stat 1;
BA_ "U_CX727_MY2021_Tx" SG_ 578 BrkTrnShifLck_B_Stat 1;
BA_ "U_CD764_MY2022_Tx" SG_ 578 PrkLckCtlUnlck_D_Stat 1;
BA_ "U_U55X_MY2022_Tx" SG_ 578 PrkLckCtlUnlck_D_Stat 1;
BA_ "U_CD542_MY2021_Tx" SG_ 578 PrkLckCtlUnlck_D_Stat 1;
BA_ "U_T6_MCA_MY2020_Tx" SG_ 578 PrkLckCtlUnlck_D_Stat 1;
BA_ "U_P702_MY2021_Tx" SG_ 578 PrkLckCtlUnlck_D_Stat 1;
BA_ "U_CX727_MY2021_Tx" SG_ 578 PrkLckCtlUnlck_D_Stat 1;
BA_ "U_CD764_MY2022_Tx" SG_ 578 PrkLckCtlTow_B_Enbl 1;
BA_ "U_U55X_MY2022_Tx" SG_ 578 PrkLckCtlTow_B_Enbl 1;
BA_ "U_CD542_MY2021_Tx" SG_ 578 PrkLckCtlTow_B_Enbl 1;
BA_ "U_T6_MCA_MY2020_Tx" SG_ 578 PrkLckCtlTow_B_Enbl 1;
BA_ "U_P702_MY2021_Tx" SG_ 578 PrkLckCtlTow_B_Enbl 1;
BA_ "U_CX727_MY2021_Tx" SG_ 578 PrkLckCtlTow_B_Enbl 1;
BA_ "U_CD764_MY2022_Tx" SG_ 578 DriverCrankingReq 1;
BA_ "U_U55X_MY2022_Tx" SG_ 578 DriverCrankingReq 1;
BA_ "U_CD542_MY2021_Tx" SG_ 578 DriverCrankingReq 1;
BA_ "U_T6_MCA_MY2020_Tx" SG_ 578 DriverCrankingReq 1;
BA_ "U_P702_MY2021_Tx" SG_ 578 DriverCrankingReq 1;
BA_ "U_CX727_MY2021_Tx" SG_ 578 DriverCrankingReq 1;
BA_ "U_CD764_MY2022_Tx" SG_ 578 EngOff_T_Actl 1;
BA_ "U_U55X_MY2022_Tx" SG_ 578 EngOff_T_Actl 1;
BA_ "U_CD542_MY2021_Tx" SG_ 578 EngOff_T_Actl 1;
BA_ "U_T6_MCA_MY2020_Tx" SG_ 578 EngOff_T_Actl 1;
BA_ "U_P702_MY2021_Tx" SG_ 578 EngOff_T_Actl 1;
BA_ "U_CX727_MY2021_Tx" SG_ 578 EngOff_T_Actl 1;
BA_ "U_U55X_MY2022_Rx" SG_ 578 EngOff_T_Actl 1;
BA_ "U_CD764_MY2022_Tx" SG_ 578 DcacElPw_D_Rq 1;
BA_ "U_U55X_MY2022_Tx" SG_ 578 DcacElPw_D_Rq 1;
BA_ "U_CD542_MY2021_Tx" SG_ 578 DcacElPw_D_Rq 1;
BA_ "U_T6_MCA_MY2020_Tx" SG_ 578 DcacElPw_D_Rq 1;
BA_ "U_P702_MY2021_Tx" SG_ 578 DcacElPw_D_Rq 1;
BA_ "U_CX727_MY2021_Tx" SG_ 578 DcacElPw_D_Rq 1;
BA_ "U_CD764_MY2022_Tx" SG_ 578 BattULo_I_Actl 1;
BA_ "U_U55X_MY2022_Tx" SG_ 578 BattULo_I_Actl 1;
BA_ "U_CD542_MY2021_Tx" SG_ 578 BattULo_I_Actl 1;
BA_ "U_T6_MCA_MY2020_Tx" SG_ 578 BattULo_I_Actl 1;
BA_ "U_P702_MY2021_Tx" SG_ 578 BattULo_I_Actl 1;
BA_ "U_CX727_MY2021_Tx" SG_ 578 BattULo_I_Actl 1;
BA_ "GenSigStartValue" SG_ 578 BattULo_I_Actl 16383;
BA_ "GenSigStartValueInteger" SG_ 578 BattULo_I_Actl 16383;
BA_ "U_CD764_MY2022_Rx" SG_ 514 StrtrMtrCtlMsgTxt_D2_Rq 1;
BA_ "U_U55X_MY2022_Rx" SG_ 514 StrtrMtrCtlMsgTxt_D2_Rq 1;
BA_ "U_CD542_MY2021_Rx" SG_ 514 StrtrMtrCtlMsgTxt_D2_Rq 1;
BA_ "U_T6_MCA_MY2020_Rx" SG_ 514 StrtrMtrCtlMsgTxt_D2_Rq 1;
BA_ "U_CD764_MY2022_Rx" SG_ 514 StrtrMtrDlyStrt_B_Stat 1;
BA_ "U_U55X_MY2022_Rx" SG_ 514 StrtrMtrDlyStrt_B_Stat 1;
BA_ "U_CD542_MY2021_Rx" SG_ 514 StrtrMtrDlyStrt_B_Stat 1;
BA_ "U_T6_MCA_MY2020_Rx" SG_ 514 StrtrMtrDlyStrt_B_Stat 1;
BA_ "U_P702_MY2021_Rx" SG_ 514 StrtrMtrDlyStrt_B_Stat 1;
BA_ "U_CX727_MY2021_Rx" SG_ 514 StrtrMtrDlyStrt_B_Stat 1;
BA_ "MetaData" SG_ 514 VehVActlEng_No_Cs 1;
BA_ "MetaData" SG_ 514 VehVActlEng_No_Cnt 1;
BA_ "U_CD764_MY2022_Rx" SG_ 514 VehVActlEng_D_Qf 1;
BA_ "U_U55X_MY2022_Rx" SG_ 514 VehVActlEng_D_Qf 1;
BA_ "U_CD542_MY2021_Rx" SG_ 514 VehVActlEng_D_Qf 1;
BA_ "U_T6_MCA_MY2020_Rx" SG_ 514 VehVActlEng_D_Qf 1;
BA_ "U_P702_MY2021_Rx" SG_ 514 VehVActlEng_D_Qf 1;
BA_ "U_CX727_MY2021_Rx" SG_ 514 VehVActlEng_D_Qf 1;
BA_ "MetaData" SG_ 514 VehVActlEng_D_Qf 1;
BA_ "U_CD764_MY2022_Rx" SG_ 514 Veh_V_ActlEng 1;
BA_ "U_U55X_MY2022_Rx" SG_ 514 Veh_V_ActlEng 1;
BA_ "U_CD542_MY2021_Rx" SG_ 514 Veh_V_ActlEng 1;
BA_ "U_T6_MCA_MY2020_Rx" SG_ 514 Veh_V_ActlEng 1;
BA_ "U_P702_MY2021_Rx" SG_ 514 Veh_V_ActlEng 1;
BA_ "U_CX727_MY2021_Rx" SG_ 514 Veh_V_ActlEng 1;
BA_ "ContentDependant" SG_ 514 EngAout_Tq_VacLimSpcN 1;
BA_ "ContentDependant" SG_ 514 EngCylSync_No_Ctr 1;
BA_ "U_CD764_MY2022_Rx" SG_ 514 GearRvrse_D_Actl 1;
BA_ "U_U55X_MY2022_Rx" SG_ 514 GearRvrse_D_Actl 1;
BA_ "U_CD542_MY2021_Rx" SG_ 514 GearRvrse_D_Actl 1;
BA_ "U_T6_MCA_MY2020_Rx" SG_ 514 GearRvrse_D_Actl 1;
BA_ "U_P702_MY2021_Rx" SG_ 514 GearRvrse_D_Actl 1;
BA_ "U_CX727_MY2021_Rx" SG_ 514 GearRvrse_D_Actl 1;
BA_ "GenSigStartValue" SG_ 514 GearRvrse_D_Actl 7;
BA_ "GenSigStartValueInteger" SG_ 514 GearRvrse_D_Actl 7;
BA_ "GenSigStartValue" SG_ 1057 FohEng_D_Rq 2;
BA_ "ContentDependant" SG_ 1057 FohEng_D_Rq 1;
BA_ "GenSigStartValueInteger" SG_ 1057 FohEng_D_Rq 2;
BA_ "U_CD764_MY2022_Rx" SG_ 1057 EngIdlShutDown_D_Stat 1;
BA_ "U_U55X_MY2022_Rx" SG_ 1057 EngIdlShutDown_D_Stat 1;
BA_ "U_CD542_MY2021_Rx" SG_ 1057 EngIdlShutDown_D_Stat 1;
BA_ "U_T6_MCA_MY2020_Rx" SG_ 1057 EngIdlShutDown_D_Stat 1;
BA_ "U_P702_MY2021_Rx" SG_ 1057 EngIdlShutDown_D_Stat 1;
BA_ "U_CX727_MY2021_Rx" SG_ 1057 EngIdlShutDown_D_Stat 1;
BA_ "ContentDependant" SG_ 1057 EngIdlShutDown_D_Stat 1;
BA_ "GenSigStartValue" SG_ 1057 FUEL_ALCOHOL_PERCNT 255;
BA_ "ContentDependant" SG_ 1057 FUEL_ALCOHOL_PERCNT 1;
BA_ "GenSigStartValueInteger" SG_ 1057 FUEL_ALCOHOL_PERCNT 255;
BA_ "ContentDependant" SG_ 1057 TrnTotTq_Rt_Est 1;
BA_ "ContentDependant" SG_ 1057 TrnTotLss_Tq_Est 1;
BA_ "ContentDependant" SG_ 1057 VehVLimStat_D_Actl 1;
BA_ "ContentDependant" SG_ 1057 VehVLimActv_B_Actl 1;
BA_ "U_CD764_MY2022_Rx" SG_ 1057 CoolantFanStepAct 1;
BA_ "U_U55X_MY2022_Rx" SG_ 1057 CoolantFanStepAct 1;
BA_ "U_CD542_MY2021_Rx" SG_ 1057 CoolantFanStepAct 1;
BA_ "U_T6_MCA_MY2020_Rx" SG_ 1057 CoolantFanStepAct 1;
BA_ "U_P702_MY2021_Rx" SG_ 1057 CoolantFanStepAct 1;
BA_ "U_CX727_MY2021_Rx" SG_ 1057 CoolantFanStepAct 1;
BA_ "WakeupSignal" SG_ 1069 ReFuelSysStat_D_Dsply 1;
BA_ "U_CX727_MY2021_Rx" SG_ 1069 ULoSrcOnPlg_B_Cmd 1;
BA_ "U_CD542_MY2021_Rx" SG_ 1069 ULoSrcOnPlg_B_Cmd 1;
BA_ "U_CD764_MY2022_Rx" SG_ 1069 GrllShtrPos_D_Cmd 1;
BA_ "U_U55X_MY2022_Rx" SG_ 1069 GrllShtrPos_D_Cmd 1;
BA_ "U_CD542_MY2021_Rx" SG_ 1069 GrllShtrPos_D_Cmd 1;
BA_ "U_T6_MCA_MY2020_Rx" SG_ 1069 GrllShtrPos_D_Cmd 1;
BA_ "U_P702_MY2021_Rx" SG_ 1069 GrllShtrPos_D_Cmd 1;
BA_ "U_CX727_MY2021_Rx" SG_ 1069 GrllShtrPos_D_Cmd 1;
BA_ "U_CD764_MY2022_Rx" SG_ 1069 GrllShtrPos_B_Falt 1;
BA_ "U_U55X_MY2022_Rx" SG_ 1069 GrllShtrPos_B_Falt 1;
BA_ "U_CD542_MY2021_Rx" SG_ 1069 GrllShtrPos_B_Falt 1;
BA_ "U_T6_MCA_MY2020_Rx" SG_ 1069 GrllShtrPos_B_Falt 1;
BA_ "U_P702_MY2021_Rx" SG_ 1069 GrllShtrPos_B_Falt 1;
BA_ "U_CX727_MY2021_Rx" SG_ 1069 GrllShtrPos_B_Falt 1;
BA_ "U_CD542_MY2021_Rx" SG_ 1069 ObdWarmUp_B_Complt 1;
BA_ "U_P702_MY2021_Rx" SG_ 1069 ObdWarmUp_B_Complt 1;
BA_ "U_CX727_MY2021_Rx" SG_ 1069 ObdWarmUp_B_Complt 1;
BA_ "ContentDependant" SG_ 1069 ObdWarmUp_B_Complt 1;
BA_ "ContentDependant" SG_ 1069 EngMsgTxt_D_Rq 1;
BA_ "U_CD542_MY2021_Rx" SG_ 1069 EngClnt_Te_ActlDiag 1;
BA_ "U_P702_MY2021_Rx" SG_ 1069 EngClnt_Te_ActlDiag 1;
BA_ "U_CX727_MY2021_Rx" SG_ 1069 EngClnt_Te_ActlDiag 1;
BA_ "ContentDependant" SG_ 1069 EngClnt_Te_ActlDiag 1;
BA_ "U_CD542_MY2021_Rx" SG_ 1069 EngLoad_Pc_CalcDiag 1;
BA_ "U_P702_MY2021_Rx" SG_ 1069 EngLoad_Pc_CalcDiag 1;
BA_ "U_CX727_MY2021_Rx" SG_ 1069 EngLoad_Pc_CalcDiag 1;
BA_ "ContentDependant" SG_ 1069 EngLoad_Pc_CalcDiag 1;
BA_ "U_CD764_MY2022_Rx" SG_ 1069 EngAirIn_Te_Actl 1;
BA_ "U_U55X_MY2022_Rx" SG_ 1069 EngAirIn_Te_Actl 1;
BA_ "U_CD542_MY2021_Rx" SG_ 1069 EngAirIn_Te_Actl 1;
BA_ "U_T6_MCA_MY2020_Rx" SG_ 1069 EngAirIn_Te_Actl 1;
BA_ "U_P702_MY2021_Rx" SG_ 1069 EngAirIn_Te_Actl 1;
BA_ "U_CX727_MY2021_Rx" SG_ 1069 EngAirIn_Te_Actl 1;
BA_ "U_CD542_MY2021_Rx" SG_ 1069 ApedPos_Pc_ActlDiag 1;
BA_ "U_P702_MY2021_Rx" SG_ 1069 ApedPos_Pc_ActlDiag 1;
BA_ "U_CX727_MY2021_Rx" SG_ 1069 ApedPos_Pc_ActlDiag 1;
BA_ "ContentDependant" SG_ 1069 ApedPos_Pc_ActlDiag 1;
BA_ "U_CD764_MY2022_Tx" SG_ 1037 BattRgenLo_I_Est 1;
BA_ "U_U55X_MY2022_Tx" SG_ 1037 BattRgenLo_I_Est 1;
BA_ "U_T6_MCA_MY2020_Tx" SG_ 1037 BattRgenLo_I_Est 1;
BA_ "U_T6_MCA_MY2020_Rx" SG_ 1037 BattRgenLo_I_Est 1;
BA_ "GenSigStartValueInteger" SG_ 878 DcacHw_D_Confg 1;
BA_ "U_U55X_MY2022_Rx" SG_ 878 DcacFaltMsgTxt_D_Rq 1;
BA_ "U_T6_MCA_MY2020_Rx" SG_ 878 DcacFaltMsgTxt_D_Rq 1;
BA_ "GenSigStartValueInteger" SG_ 878 DcacFaltMsgTxt_D_Rq 1;
BA_ "U_U55X_MY2022_Rx" SG_ 878 DcacElPw_D_Stat 1;
BA_ "U_T6_MCA_MY2020_Rx" SG_ 878 DcacElPw_D_Stat 1;
BA_ "GenSigStartValue" SG_ 878 DcacElPw_D_Stat 1;
BA_ "GenSigStartValueInteger" SG_ 878 DcacElPw_D_Stat 1;
BA_ "U_P702_MY2021_Rx" SG_ 878 DcacOn_B_Rq 1;
BA_ "U_P702_MY2021_Rx" SG_ 878 DcacSys_B_Falt 1;
BA_ "U_U55X_MY2022_Rx" SG_ 878 DcacSys_B_Falt 1;
BA_ "U_T6_MCA_MY2020_Rx" SG_ 878 DcacSys_B_Falt 1;
BA_ "U_P702_MY2021_Rx" SG_ 878 DcacLedCtl_D_Rq 1;
BA_ "GenSigSendType" SG_ 2010 TesterPhysicalResGFM2 3;
BA_ "GenSigStartValue" SG_ 1522 GFM2_GWOnBoardTester 255;
BA_ "ContentDependant" SG_ 1522 GFM2_GWOnBoardTester 1;
BA_ "GenSigStartValueInteger" SG_ 1522 GFM2_GWOnBoardTester 255;
BA_ "GenSigStartValue" SG_ 1522 GFM2_GWNMProxy 255;
BA_ "ContentDependant" SG_ 1522 GFM2_GWNMProxy 1;
BA_ "GenSigStartValueInteger" SG_ 1522 GFM2_GWNMProxy 255;
BA_ "GenSigStartValue" SG_ 1522 GFM2_AutoSarNMReserved4 255;
BA_ "ContentDependant" SG_ 1522 GFM2_AutoSarNMReserved4 1;
BA_ "GenSigStartValueInteger" SG_ 1522 GFM2_AutoSarNMReserved4 255;
BA_ "GenSigStartValue" SG_ 1522 GFM2_AutoSarNMReserved3 255;
BA_ "ContentDependant" SG_ 1522 GFM2_AutoSarNMReserved3 1;
BA_ "GenSigStartValueInteger" SG_ 1522 GFM2_AutoSarNMReserved3 255;
BA_ "GenSigStartValue" SG_ 1522 GFM2_AutoSarNMReserved2 255;
BA_ "ContentDependant" SG_ 1522 GFM2_AutoSarNMReserved2 1;
BA_ "GenSigStartValueInteger" SG_ 1522 GFM2_AutoSarNMReserved2 255;
BA_ "GenSigStartValue" SG_ 1522 GFM2_AutoSarNMReserved1 255;
BA_ "ContentDependant" SG_ 1522 GFM2_AutoSarNMReserved1 1;
BA_ "GenSigStartValueInteger" SG_ 1522 GFM2_AutoSarNMReserved1 255;
BA_ "GenSigStartValue" SG_ 1522 GFM2_AutoSarNMNodeId 242;
BA_ "ContentDependant" SG_ 1522 GFM2_AutoSarNMNodeId 1;
BA_ "GenSigStartValueInteger" SG_ 1522 GFM2_AutoSarNMNodeId 242;
BA_ "ContentDependant" SG_ 1522 GFM2_AutoSarNMControl 1;
BA_ "GenSigStartValue" SG_ 1442 BECM_GWOnBoardTester 255;
BA_ "ContentDependant" SG_ 1442 BECM_GWOnBoardTester 1;
BA_ "GenSigStartValueInteger" SG_ 1442 BECM_GWOnBoardTester 255;
BA_ "U_CD542_MY2021_Tx" SG_ 1442 BECM_GWNMProxy 1;
BA_ "GenSigStartValue" SG_ 1442 BECM_GWNMProxy 255;
BA_ "ContentDependant" SG_ 1442 BECM_GWNMProxy 1;
BA_ "GenSigStartValueInteger" SG_ 1442 BECM_GWNMProxy 255;
BA_ "GenSigStartValue" SG_ 1442 BECM_AutoSarNMReserved4 255;
BA_ "ContentDependant" SG_ 1442 BECM_AutoSarNMReserved4 1;
BA_ "GenSigStartValueInteger" SG_ 1442 BECM_AutoSarNMReserved4 255;
BA_ "GenSigStartValue" SG_ 1442 BECM_AutoSarNMReserved3 255;
BA_ "ContentDependant" SG_ 1442 BECM_AutoSarNMReserved3 1;
BA_ "GenSigStartValueInteger" SG_ 1442 BECM_AutoSarNMReserved3 255;
BA_ "GenSigStartValue" SG_ 1442 BECM_AutoSarNMReserved2 255;
BA_ "ContentDependant" SG_ 1442 BECM_AutoSarNMReserved2 1;
BA_ "GenSigStartValueInteger" SG_ 1442 BECM_AutoSarNMReserved2 255;
BA_ "GenSigStartValue" SG_ 1442 BECM_AutoSarNMReserved1 255;
BA_ "ContentDependant" SG_ 1442 BECM_AutoSarNMReserved1 1;
BA_ "GenSigStartValueInteger" SG_ 1442 BECM_AutoSarNMReserved1 255;
BA_ "GenSigStartValue" SG_ 1442 BECM_AutoSarNMNodeId 162;
BA_ "ContentDependant" SG_ 1442 BECM_AutoSarNMNodeId 1;
BA_ "GenSigStartValueInteger" SG_ 1442 BECM_AutoSarNMNodeId 162;
BA_ "ContentDependant" SG_ 1442 BECM_AutoSarNMControl 1;
BA_ "U_U55X_MY2022_Rx" SG_ 1200 BrkHold_D_Stat 1;
BA_ "GenSigStartValueInteger" SG_ 1200 HsaTrnAout_Tq_Rq 32768;
BA_ "GenSigStartValue" SG_ 1200 BrkBstrVac_P_Actl 127;
BA_ "GenSigStartValueInteger" SG_ 1200 BrkBstrVac_P_Actl 127;
BA_ "GenSigStartValueInteger" SG_ 1200 YawStabilityIndex 256;
BA_ "U_U55X_MY2022_Rx" SG_ 1200 BrkTot_Tq_RqDrv 1;
BA_ "U_U55X_MY2022_Rx" SG_ 1200 BrkTotTqRqDrv_No_Cnt 1;
BA_ "MetaData" SG_ 1200 BrkTotTqRqDrv_No_Cnt 1;
BA_ "U_U55X_MY2022_Rx" SG_ 1200 BrkTotTqRqDrv_No_Cs 1;
BA_ "MetaData" SG_ 1200 BrkTotTqRqDrv_No_Cs 1;
BA_ "ECGUsedRxSignal" SG_ 2015 TesterFunctionalReq 1;
BA_ "U_CD764_MY2022_Rx" SG_ 2015 TesterFunctionalReq 1;
BA_ "U_U55X_MY2022_Rx" SG_ 2015 TesterFunctionalReq 1;
BA_ "U_CD542_MY2021_Rx" SG_ 2015 TesterFunctionalReq 1;
BA_ "U_T6_MCA_MY2020_Rx" SG_ 2015 TesterFunctionalReq 1;
BA_ "U_P702_MY2021_Rx" SG_ 2015 TesterFunctionalReq 1;
BA_ "U_CX727_MY2021_Rx" SG_ 2015 TesterFunctionalReq 1;
BA_ "GenSigSendType" SG_ 2015 TesterFunctionalReq 3;
BA_ "ContentDependant" SG_ 376 EngAout_Aa_Actl 1;
BA_ "GenSigStartValueInteger" SG_ 376 HvacHtrCore2_Te_Actl 200;
BA_ "U_CD764_MY2022_Rx" SG_ 376 AirAmbTe_D_Qf 1;
BA_ "U_U55X_MY2022_Rx" SG_ 376 AirAmbTe_D_Qf 1;
BA_ "U_CD542_MY2021_Rx" SG_ 376 AirAmbTe_D_Qf 1;
BA_ "U_T6_MCA_MY2020_Rx" SG_ 376 AirAmbTe_D_Qf 1;
BA_ "U_P702_MY2021_Rx" SG_ 376 AirAmbTe_D_Qf 1;
BA_ "U_CX727_MY2021_Rx" SG_ 376 AirAmbTe_D_Qf 1;
BA_ "GenSigStartValue" SG_ 376 AirAmbTe_D_Qf 1;
BA_ "MetaData" SG_ 376 AirAmbTe_D_Qf 1;
BA_ "GenSigStartValueInteger" SG_ 376 AirAmbTe_D_Qf 1;
BA_ "ECGUsedRxSignal" SG_ 376 AirAmb_Te_ActlFilt 1;
BA_ "U_CD764_MY2022_Rx" SG_ 376 AirAmb_Te_ActlFilt 1;
BA_ "U_U55X_MY2022_Rx" SG_ 376 AirAmb_Te_ActlFilt 1;
BA_ "U_CD542_MY2021_Rx" SG_ 376 AirAmb_Te_ActlFilt 1;
BA_ "U_T6_MCA_MY2020_Rx" SG_ 376 AirAmb_Te_ActlFilt 1;
BA_ "U_P702_MY2021_Rx" SG_ 376 AirAmb_Te_ActlFilt 1;
BA_ "U_CX727_MY2021_Rx" SG_ 376 AirAmb_Te_ActlFilt 1;
BA_ "GenSigStartValueInteger" SG_ 376 AirAmb_Te_ActlFilt 512;
BA_ "U_P702_MY2021_Rx" SG_ 376 AirAmb_Te_Actl 1;
BA_ "U_CD764_MY2022_Rx" SG_ 376 AirAmb_Te_Actl 1;
BA_ "U_U55X_MY2022_Rx" SG_ 376 AirAmb_Te_Actl 1;
BA_ "U_CD542_MY2021_Rx" SG_ 376 AirAmb_Te_Actl 1;
BA_ "U_CX727_MY2021_Rx" SG_ 376 AirAmb_Te_Actl 1;
BA_ "GenSigStartValueInteger" SG_ 376 AirAmb_Te_Actl 512;
BA_ "U_CD764_MY2022_Rx" SG_ 376 AirAmb_P_Actl 1;
BA_ "U_U55X_MY2022_Rx" SG_ 376 AirAmb_P_Actl 1;
BA_ "U_CD542_MY2021_Rx" SG_ 376 AirAmb_P_Actl 1;
BA_ "U_T6_MCA_MY2020_Rx" SG_ 376 AirAmb_P_Actl 1;
BA_ "U_P702_MY2021_Rx" SG_ 376 AirAmb_P_Actl 1;
BA_ "U_CX727_MY2021_Rx" SG_ 376 AirAmb_P_Actl 1;
VAL_ 125 VehRolComp_W_Actl 4094 "NoDataExists" 4095 "Fault" ;
VAL_ 125 VehVertComp_A_Actl 1022 "NoDataExists" 1023 "Fault" ;
VAL_ 125 BrkTot_Tq_RqArb 8191 "Fault" 8190 "Unknown" ;
VAL_ 125 BrkTot_Tq_Actl 8191 "Fault" 8190 "Unknown" ;
VAL_ 125 HsaStat_D_Actl 7 "Faulty" 6 "FaultyWithDriverIndication" 5 "SlowRelease" 4 "FastRelease" 3 "ActiveBrakePedalReleased" 2 "ActiveBrakePedalPressed" 1 "FindingGradient" 0 "Inactive" ;
VAL_ 119 VehLongComp_A_Actl 1023 "Fault" 1022 "NoDataExists" ;
VAL_ 119 VehLatComp_A_Actl 1023 "Fault" 1022 "NoDataExists" ;
VAL_ 119 VehYawComp_W_Actl 4095 "Fault" 4094 "NoDataExists" ;
VAL_ 119 VehOverGnd_V_Est 65535 "Invalid" 65534 "Unknown" ;
VAL_ 1045 VehStab_D_Stat 15 "Faulty" 14 "No_Data_Exists" 13 "NotUsed6" 12 "NotUsed5" 11 "NotUsed4" 10 "NotUsed3" 9 "NotUsed2" 8 "Combined_OS_and_US" 7 "High_SSRA_no_OS" 6 "Straight" 5 "Post_Oversteer" 4 "Post_Transition" 3 "Countersteer" 2 "Understeer" 1 "Oversteer" 0 "Linear" ;
VAL_ 1045 BrkFluidLvl_D_Stat 3 "Invalid" 2 "Unknown" 1 "Low" 0 "OK" ;
VAL_ 1045 LsmcBrkDecel_D_Stat 7 "NotUsed_3" 6 "NotUsed_2" 5 "NotUsed_1" 4 "Denied" 3 "FaultDegraded" 2 "FaultExt" 1 "On" 0 "Off" ;
VAL_ 1045 VehYawNonLin_W_Rq 4095 "Fault" 4094 "Unknown" ;
VAL_ 1045 VehYawLin_W_Rq 4095 "Fault" 4094 "Unknown" ;
VAL_ 1045 VehVActlBrk_D_Qf 3 "OK" 2 "Not_Within_Specifications" 1 "No_Data_Exists" 0 "Faulty" ;
VAL_ 534 WhlDirRr_D_Actl 3 "Faulty" 2 "NoDataExists" 1 "Backward" 0 "Forward" ;
VAL_ 534 WhlDirRl_D_Actl 3 "Faulty" 2 "NoDataExists" 1 "Backward" 0 "Forward" ;
VAL_ 534 WhlDirFr_D_Actl 3 "Faulty" 2 "NoDataExists" 1 "Backward" 0 "Forward" ;
VAL_ 534 WhlDirFl_D_Actl 3 "Faulty" 2 "NoDataExists" 1 "Backward" 0 "Forward" ;
VAL_ 532 RgenTqFalt_B_Actl 1 "Fault" 0 "No_Fault" ;
VAL_ 532 RgenBrkDynoMde_B_Actl 1 "TwoWheelDyno" 0 "NormalOperation" ;
VAL_ 531 VehStop_D_Stat 3 "Faulty" 2 "NoDataExists" 1 "Yes" 0 "No" ;
VAL_ 531 TracCtlPtActv_B_Actl 1 "Active" 0 "Inactive" ;
VAL_ 531 LscmbbMntr_B_Err 1 "DisplayMessage" 0 "NoMessage" ;
VAL_ 531 LscmbbBrkDis_B_Actl 1 "Yes" 0 "No" ;
VAL_ 531 StabCtlBrkActv_B_Actl 1 "Yes" 0 "No" ;
VAL_ 531 CmbbBrkPrchg_B_Actl 1 "Yes" 0 "No" ;
VAL_ 531 CmbbBrkDecel_B_Actl 1 "Yes" 0 "No" ;
VAL_ 531 CmbbBaSensInc_B_Actl 1 "Yes" 0 "No" ;
VAL_ 531 AccBrkWarm_B_Actl 1 "Yes" 0 "No" ;
VAL_ 531 AccBrkTotTqMn_B_Actl 1 "Yes" 0 "No" ;
VAL_ 531 AccBrkPrchgActv_B_Actl 1 "Yes" 0 "No" ;
VAL_ 531 AccBrkDis_B_Actl 1 "Yes" 0 "No" ;
VAL_ 531 AccBrkDeny_B_Actl 1 "Yes" 0 "No" ;
VAL_ 531 AccBrkActv_B_Actl 1 "Yes" 0 "No" ;
VAL_ 531 PrplDrgCtlActv_B_Actl 1 "Active" 0 "Inactive" ;
VAL_ 531 AbsActv_B_Actl 1 "Yes" 0 "No" ;
VAL_ 531 CmbbBrkDis_B_Actl 1 "Yes" 0 "No" ;
VAL_ 531 CmbbDeny_B_ActlBrk 1 "Yes" 0 "No" ;
VAL_ 531 CcDis_B_Cmd 1 "Yes" 0 "No" ;
VAL_ 531 VehLongOvrGnd_A_Est 1023 "Fault" 1022 "Unknown" ;
VAL_ 531 AccStopActv_B_ActlBrk 1 "Yes" 0 "No" ;
VAL_ 531 AccDis_B_ActlEpb 1 "Yes" 0 "No" ;
VAL_ 531 PrkBrkYwLamp_D_Rq 3 "Fast_Flash" 2 "Slow_Flash" 1 "On" 0 "Off" ;
VAL_ 531 PrkBrkRedLamp_D_Rq 3 "Fast_Flash" 2 "Slow_Flash" 1 "On" 0 "Off" ;
VAL_ 531 PrkBrkMsgTxt_D_Rq 15 "Message15" 14 "Message14" 13 "Message13" 12 "Message12" 11 "Message11" 10 "Message10" 9 "Message9" 8 "Message8" 7 "Message7" 6 "Message6" 5 "Message5" 4 "Message4" 3 "Message3" 2 "Message2" 1 "Message1" 0 "No_Message" ;
VAL_ 531 PrkBrkStatus 7 "GeneralFault_MaintenceMode" 6 "ECD_by_Brake_ECU_Active" 5 "EPB_Limphome_Active" 4 "Rear_Caliper_Open" 3 "RWU_By_EPB_Active" 2 "Rear_Caliper_Transition" 1 "Rear_Caliper_Closed" 0 "Not_Supported" ;
VAL_ 531 VehicleStationary 1 "Yes" 0 "No" ;
VAL_ 531 LscmbbDeny_B_ActlBrk 1 "Yes" 0 "No" ;
VAL_ 531 LscmbbBrkDecel_B_Actl 1 "Yes" 0 "No" ;
VAL_ 531 LscmbbBaSensInc_B_Actl 1 "Yes" 0 "No" ;
VAL_ 531 LscmbBrkPrchg_B_Actl 1 "Active" 0 "Inactive" ;
VAL_ 535 WhlRr_W_Meas 32767 "Fault" 32766 "Unknown" ;
VAL_ 535 WhlRl_W_Meas 32767 "Fault" 32766 "Unknown" ;
VAL_ 535 WhlFr_W_Meas 32767 "Fault" 32766 "Unknown" ;
VAL_ 535 WhlFl_W_Meas 32767 "Fault" 32766 "Unknown" ;
VAL_ 611 AwdTerrMdeChng_D_Rdy 7 "Fault" 6 "Undefined_2" 5 "Undefined_1" 4 "ModeUnavailDrInputRqd" 3 "SpOpModes_NotSupported" 2 "ModeUnavailDynamicCond" 1 "Module_In_Initialization" 0 "Mode_Change_Available" ;
VAL_ 611 AwdTerrMde_D_Actl 7 "Fail_Safe_Default" 6 "Dynamic_Mode" 5 "Rock_Crawl_Mode" 4 "Mud_Ruts_Mode" 3 "Sand_Mode" 2 "Undefined" 1 "Low_Mu_Mode" 0 "Special_Operating_Mode_Off" ;
VAL_ 611 AwdSys_D_Stat 3 "Faulty" 2 "NotUsed" 1 "_4x4_L_H_Active" 0 "_4x4_L_H_Inactive" ;
VAL_ 611 SelDrvMdeAwd_D_Stat 0 "NotAvailable" 1 "Available" 2 "TemporarilyNotAvailable" 3 "Faulty" ;
VAL_ 611 AwdStat_D_RqDsply 31 "Rear_Diff_Lock_Not_Avail" 30 "_4wd_Lock_Required" 29 "Cfg_Perf_Redc_See_Manual" 28 "To_Engage_4x4_Release_Aped" 27 "To_Engage_4x4_Slow_To_3MPH" 26 "Shift_To_Neutral" 25 "Lkr_Mode_Unavail_TMS" 24 " _4x4_Mode_Unavail_TMS" 23 "Out_of_4Low_Crawl" 22 "AWD_PTU_Oil_Changed" 21 "Change_AWD_PTU_Oil" 20 "Neutral_Tow_Disabled" 19 "Neutral_Tow_Enabled" 18 "AWD_OFF" 17 "_4x4_Off_Road_Speed" 16 "_4x4_Extreme_Off_Road_Mode" 15 "_4x4_Exiting_Off_Road" 14 "_4x4_Off_Road_Mode" 10 "_4x4_Locked_Temporarily" 9 "Shift_In_Progress" 13 "Blocked_Shift_Assist" 12 "_4x4_Auto_Restored" 11 "_4x4_Disabled_Temporarily" 7 "Out_of_4Low__Neutral" 6 "Out_of_4Low__Brake" 5 "Out_of_4Low__Speed" 4 "Into_4Low__Clutch" 3 "Into_4Low__Neutral" 2 "Into_4Low__Brake" 1 "Into_4Low__Speed" 0 "Normal__No_Message" 8 "Out_of_4Low__Clutch" ;
VAL_ 611 AwdLck_D_Stat 9 "Undefined" 8 "Under_External_Torque_Ctrl" 7 "Torque_Limited_by_Cmd" 6 "Fully_Locked_by_Cmd" 5 "Disabled" 4 "Warning" 3 "Fault" 2 "Inactive" 1 "Completely_Opened_by_Cmd" 0 "OK" ;
VAL_ 611 AwdSrvcRqd_B_Rq 1 "On" 0 "Off" ;
VAL_ 611 AwdDrvMde_D_Stat 7 "Faulty" 6 "NotAvailable" 5 "RockCrawl" 4 "Baja" 3 "MudAndSand" 2 "Weather" 1 "Sport" 0 "Normal" ;
VAL_ 611 NtrlTowAvail_B_Stat 1 "Available" 0 "NotAvailable" ;
VAL_ 611 AwdLck_Tq_Rq 4095 "Fault" 4094 "Unknown" ;
VAL_ 611 AwdOffRoadMode_D_Stats 3 "Invalid" 2 "Extreme_Off_Road" 1 "Off_Road" 0 "Normal_Mode" ;
VAL_ 611 AwdLoLamp_D_RqDsply 3 "Not_Used" 2 "Flash" 1 "On" 0 "Off" ;
VAL_ 611 AwdHiLamp_D_RqDsply 3 "Not_Used" 2 "Flash" 1 "On" 0 "Off" ;
VAL_ 611 AwdAutoLamp_D_RqDsply 3 "Not_Used" 2 "Flash" 1 "On" 0 "Off" ;
VAL_ 611 Awd2wdLamp_D_RqDsply 3 "Not_Used" 2 "Flash" 1 "On" 0 "Off" ;
VAL_ 611 AwdRnge_D_Actl 7 "Unknown" 6 "High_Range_2wd" 5 "High_Range_Auto" 4 "High_Range_Locked" 3 "Neutral" 2 "Low_Range_2wd" 1 "Low_Range_Auto" 0 "Low_Range_Locked" ;
VAL_ 90 TrnGsmNtmState_D_Actl 3 "Faulty" 2 "Neutral_Tow_Mode" 1 "Car_Wash_Mode" 0 "None" ;
VAL_ 90 DrQltyDrv_D_StatGsm 7 "Faulty" 6 "NoDataExists" 5 "NotUsed2" 4 "NotUsed1" 3 "ClosedDegraded" 2 "OpenDegraded" 1 "ClosedOkay" 0 "OpenOkay" ;
VAL_ 90 TrnBtsiOvrrd_B_Stat 1 "Override" 0 "Null" ;
VAL_ 90 GsmGearMsgTxt_D_Rq 3 "Message3" 2 "Message2" 1 "Message1" 0 "NoMessage" ;
VAL_ 90 TrnRng_D_RqGsm 15 "Fault" 14 "UnknownPosition" 13 "Undefined_2" 12 "Undefined_1" 11 "_6" 10 "_5" 9 "_4" 8 "_3" 7 "_2" 6 "_1" 5 "Low" 4 "Sport_DriveSport" 3 "Drive" 2 "Neutral" 1 "Reverse" 0 "Park" ;
VAL_ 90 PrkBrkActv_D_RqGsmGear 3 "NotUsed" 2 "RequestParkBrakeEngage" 1 "NoRequest" 0 "Null" ;
VAL_ 90 TrnValidGearRq_D_Stat 3 "Valid_Request" 2 "Valid_Degraded_Request" 1 "Invalid_Request" 0 "No_Request" ;
VAL_ 90 TrnGearButtn_U_Actl 255 "Fault" ;
VAL_ 90 TrnGearButtn_B_ActlR2 1 "Yes" 0 "No" ;
VAL_ 90 TrnGearButtn_B_ActlR1 1 "Yes" 0 "No" ;
VAL_ 90 TrnGearButtn_B_ActlR0 1 "Yes" 0 "No" ;
VAL_ 90 TrnGearButtn_B_ActlP2 1 "Yes" 0 "No" ;
VAL_ 90 TrnGearButtn_B_ActlP1 1 "Yes" 0 "No" ;
VAL_ 90 TrnGearButtn_B_ActlP0 1 "Yes" 0 "No" ;
VAL_ 90 TrnGearButtn_B_ActlN2 1 "Yes" 0 "No" ;
VAL_ 90 TrnGearButtn_B_ActlN1 1 "Yes" 0 "No" ;
VAL_ 90 TrnGearButtn_B_ActlN0 1 "Yes" 0 "No" ;
VAL_ 90 TrnGearButtn_B_ActlM2 1 "Yes" 0 "No" ;
VAL_ 90 TrnGearButtn_B_ActlM1 1 "Yes" 0 "No" ;
VAL_ 90 TrnGearButtn_B_ActlM0 1 "Yes" 0 "No" ;
VAL_ 90 TrnGearButtn_B_ActlD2 1 "Yes" 0 "No" ;
VAL_ 90 TrnGearButtn_B_ActlD1 1 "Yes" 0 "No" ;
VAL_ 90 TrnGearButtn_B_ActlD0 1 "Yes" 0 "No" ;
VAL_ 90 TrnGear_D_RqDrv 31 "Fault" 30 "NotUsed_25" 29 "NotUsed_24" 28 "NotUsed_23" 27 "NotUsed_22" 26 "NotUsed_21" 25 "NotUsed_20" 24 "NotUsed_19" 23 "NotUsed_18" 22 "NotUsed_17" 21 "Return_To_Park" 20 "NotUsed_15" 19 "NotUsed_14" 18 "NotUsed_13" 17 "NotUsed_12" 16 "Manual" 15 "Not_Used11" 14 "Not_Used10" 13 "NotUsed_9" 12 "NotUsed_8" 11 "NotUsed_7" 10 "NotUsed_6" 9 "NotUsed_5" 8 "Drive" 7 "NotUsed_4" 6 "NotUsed_3" 5 "NotUsed_2" 4 "Neutral" 3 "NotUsed_1" 2 "Reverse" 1 "Park" 0 "No_Gear" ;
VAL_ 90 BrkSwtchPos_B_ActlGsm 1 "Yes" 0 "No" ;
VAL_ 1109 eCallConfirmation 7 "Unused_2" 6 "CallComplete_DTMF_Timeout" 5 "eCall_Configured_Off" 4 "Call_Unsuccessful" 3 "Call_Cancelled" 2 "Call_Completed" 1 "Call_In_Progress" 0 "Normal" ;
VAL_ 92 TrnGearMsgTxt2_D_Rq 31 "Message31" 30 "Message30" 29 "Message29" 28 "Message28" 27 "Message27" 26 "Message26" 25 "Message25" 24 "Message24" 23 "Message23" 22 "Message22" 21 "Message21" 20 "Message20" 19 "Message19" 18 "Message18" 17 "Message17" 16 "Message16" 15 "Message15" 14 "Message14" 13 "Message13" 12 "Message12" 11 "Message11" 10 "Message10" 9 "Message9" 8 "Message8" 7 "Message7" 6 "Message6" 5 "Message5" 4 "Message4" 3 "Message3" 2 "Message2" 1 "Message1" 0 "NoMessage" ;
VAL_ 92 RaceTrakMde_D_Stat 3 "NotUsed" 2 "Available" 1 "NotAvailable" 0 "Null" ;
VAL_ 92 TrnLvrV_D_Rq 3 "Full_Speed" 2 "Aggressive" 1 "Normal" 0 "Quiet" ;
VAL_ 92 TrnSbwSysHlth_D_Actl 3 "OK" 2 "Degraded" 1 "No_Data_Exists" 0 "Faulty" ;
VAL_ 92 TrnGearNtmAllow_B_Stat 1 "Yes" 0 "No" ;
VAL_ 92 TrnDtpCmd_D_Actl 7 "NotUsed4" 6 "NotUsed3" 5 "NotUsed2" 4 "Relatch" 3 "Deploy" 2 "Self_Test" 1 "No_Command" 0 "NotUsed1" ;
VAL_ 92 GearSelLck_D_Rq 3 "PreventionBlocker" 2 "Unlock" 1 "Lock" 0 "Null" ;
VAL_ 92 TrnValidGear_D_Cnfm 3 "Accept" 2 "Reject" 1 "Internal_Request" 0 "No_Command" ;
VAL_ 92 TrnNtrlTowCmd_D_Actl 3 "NotUsed" 2 "Neutral_Tow_Entry" 1 "Car_Wash_Mode" 0 "Normal_Mode" ;
VAL_ 92 TrnGearCmd_Pc_ActlPt 1023 "Fault" ;
VAL_ 92 TrnGear_D_RqPt 7 "Fault" 6 "NotUsed" 5 "Manual" 4 "Drive" 3 "Neutral" 2 "Reverse" 1 "Park" 0 "No_Gear" ;
VAL_ 92 TrnCmdState_B_Actl 1 "Yes" 0 "No" ;
VAL_ 92 PrkBrkActv_D_RqTrnGear 3 "NotUsed2" 2 "RequestParkBrakeEngage" 1 "NoRequest" 0 "NotUsed1" ;
VAL_ 92 TrnGearMsgTxt_D_Rq 15 "Message_15" 14 "Message_14" 13 "Message_13" 12 "Message_12" 11 "Message_11" 10 "Message_10" 9 "Message_9" 8 "Message_8" 7 "Message_7" 6 "Message_6" 5 "Message_5" 4 "Message_4" 3 "Message_3" 2 "Message_2" 1 "Message_1" 0 "NoMessage" ;
VAL_ 359 PrplWhlRgenMn_Tq_Actl 8191 "Faulty" ;
VAL_ 359 ElPw_D_StatStrtStop 15 "NotUsed6" 14 "NotUsed5" 13 "NotUsed4" 12 "NotUsed3" 11 "NotUsed2" 10 "NotUsed1" 9 "Supported_Level_4" 8 "Supported_Level_3" 7 "Supported_Level_2" 6 "Supported_Level_1" 5 "Limited_Support" 4 "Fault_Limited" 3 "LV_Event_in_Progress" 2 "Not_Supported_Imminent" 1 "Supported_All" 0 "Not_Supported" ;
VAL_ 359 PrplWhlTot2_Tq_Actl 65535 "Fault" 65534 "NoDataExists" ;
VAL_ 359 LscmbbDeny_B_ActlPrpl 1 "Denied" 0 "Allowed" ;
VAL_ 359 LscmbbEngTqMn_B_Actl 1 "Engine_Braking_Activated" 0 "Engine_Braking_Off" ;
VAL_ 359 PwPckTq_D_Stat 3 "PwPckOn_TqAvailable" 2 "StartInPrgrss_TqNotAvail" 1 "PwPckOn_TqNotAvailable" 0 "PwPckOff_TqNotAvailable" ;
VAL_ 359 Eng_D_Stat 3 "NotUsed" 2 "EngAutoStopped" 1 "EngOn" 0 "EngOff" ;
VAL_ 359 PlgActvArb_B_Actl 1 "On" 0 "Off" ;
VAL_ 359 ElPw_D_Stat 7 "NotUsed_3" 6 "NotUsed_2" 5 "NotUsed_1" 4 "Fault_Limited" 3 "LV_Event_In_Progress" 2 "Not_Supported_Imminent" 1 "Supported" 0 "Not_Supported" ;
VAL_ 359 TrnAinTq_D_Qf 3 "OK" 2 "Not_Within_Specifications" 1 "No_Data_Exists" 0 "Faulty" ;
VAL_ 358 StopStrtStdby_D_Indic 6 "Telltale_On_Grey" 5 "Telltale_Struck_Out" 4 "Telltale_Flashing_Amber" 3 "Telltale_On_Amber" 2 "Telltale_Flashing_Green" 1 "Telltale_On_Green" 0 "Telltale_Off" 7 "NotUsed3" ;
VAL_ 358 StopStrtIODTxt_D_Rq 31 "Message31" 30 "Message30" 29 "Message29" 28 "Message28" 27 "Message27" 26 "Message26" 25 "Message25" 24 "Message24" 23 "Message23" 22 "Message22" 21 "Message21" 20 "Message20" 19 "Message19" 18 "Message18" 17 "Message17" 16 "Message16" 15 "Message15" 14 "Message14" 13 "Message13" 12 "Message12" 11 "Message11" 10 "Message10" 9 "Message9" 8 "Message8" 7 "Message7" 6 "Message6" 5 "Message5" 4 "Message4" 3 "Message3" 2 "Message2" 1 "Message1" 0 "NoMessage" ;
VAL_ 358 StopStrtDrvMde_D_Indic 3 "NotUsed" 2 "StartStop_IndirectDeselect" 1 "StopStart_Deselected" 0 "StopStart_Selected" ;
VAL_ 358 StopStrtMsgTxt_D_Rq 15 "Message_15" 14 "Message_14" 13 "Message_13" 12 "Message_12" 11 "Message_11" 10 "Message_10" 9 "Message_9" 8 "Message_8" 7 "Message_7" 6 "Message_6" 5 "Message_5" 4 "Message_4" 3 "Message_3" 2 "Message_2" 1 "Message_1" 0 "NoMessage" ;
VAL_ 358 OdoTripVerify_L_Actl 16777215 "Fault" ;
VAL_ 358 HiElPwInhbt_B_Stat 1 "Inhibit" 0 "No_Inibit" ;
VAL_ 358 AutoStopPtDelta_I_Est 255 "Fault" ;
VAL_ 1084 BattULoState_D_Qlty 3 "OK" 2 "Not_Within_Specifications" 1 "Eval_In_Progress" 0 "Fault" ;
VAL_ 1084 BSFault 1 "Fault" 0 "No_Fault" ;
VAL_ 1084 BattULo2_Te_Actl 127 "Fault" ;
VAL_ 1086 AwdPtu_Te_Actl 255 "Faulty" ;
VAL_ 1086 FuelPumpPwr_B_Rq 1 "On" 0 "Off" ;
VAL_ 1086 ElLoadCtl_D_Rq 7 "Unused3" 6 "Unused2" 5 "Unused1" 4 "HoldAllDrvrInvisibleLoads" 3 "StdDriverInvisibleLoadsOn" 2 "AllDriverInvisibleLoadsOn" 1 "All_Possible_Loads_Off" 0 "No_Request" ;
VAL_ 1085 ULoRgenTestMde_B_Stat 1 "Active" 0 "Inactive" ;
VAL_ 1085 PwSrcULoOvrTe_B_Actl 1 "Yes" 0 "No" ;
VAL_ 1085 PwSrcULoOn_B_Actl 1 "Operating" 0 "Not_Operating" ;
VAL_ 1085 PwSrcULoFalt_D_Stat 3 "Fault_No_Output" 2 "Fault_Reduced_Output" 1 "Fault_NonSpecific" 0 "No_Fault" ;
VAL_ 1085 PwSrcULoDcnnt_B_Stat 1 "Loose_or_Disconnected" 0 "Connected" ;
VAL_ 1085 PwSrcULo_Pc_Mx 255 "Fault" ;
VAL_ 1085 BattTracCool_D_RqDcdc 3 "NotUsed" 2 "DCDC_Overtemperature" 1 "CoolingRequiredbyDCDC" 0 "NoCoolingRequiredbyDCDC" ;
VAL_ 1085 PwSrcULoComm_B_Falt 1 "Fault" 0 "No_Fault" ;
VAL_ 1085 DcdcULo_U_Actl 255 "Fault" ;
VAL_ 1085 DcdcUHi_I_Actl 255 "Fault" ;
VAL_ 1085 PwSrcULo_I_Mx 255 "Fault" ;
VAL_ 1085 PwSrcULo_I_Actl 255 "Fault" ;
VAL_ 1085 DcdcUHi_U_Actl 1023 "Fault" 1022 "NoDataExists" ;
VAL_ 891 CabnSndAmb2_Db_Actl_UB 1 "Fresh_data" 0 "Unchanged_data" ;
VAL_ 891 CabnSndAmb2_Db_Actl 255 "Fault" ;
VAL_ 603 FuelCtlOpenLp_B_Inhbt 1 " Inhibit_FullPedal_Actions" 0 "Normal_Operation" ;
VAL_ 603 EngDiag_D_RqHtrn 7 "NotUsed4" 6 "NotUsed3" 5 "NotUsed2" 4 "NoUsed1" 3 "Eng_Diag_Cstdn" 2 "Eng_Diag_Run" 1 "Eng_Diag_Crank" 0 "Eng_Diag_Normal" ;
VAL_ 603 WhlDirAvgDrv_D_Actl 3 "Faulty" 2 "NoDataExists" 1 "Backward" 0 "Forward" ;
VAL_ 603 PrplTqMnRgen_B_Actl 1 "Yes" 0 "No" ;
VAL_ 603 EDrvTqMntrRconfg_D_Cmd 7 "OK" 6 "Disable_Cruise" 5 "NotUsed4" 4 "Supercreep" 3 "NotUsed3" 2 "NotUsed2" 1 "Engine_shutdown" 0 "NotUsed" ;
VAL_ 603 BattTracCnnct_D_Rq 3 "Undefined" 2 "Retain" 1 "Close" 0 "Open" ;
VAL_ 602 HtrnWarnLamp_B_Dsply 1 "On" 0 "Off" ;
VAL_ 602 HybPwLimOn_B_Stat 1 "Yes" 0 "No" ;
VAL_ 602 PwSrcULoMde_D_Rq 3 "BuckSpecial" 2 "ReverseBoost" 1 "ForwardBuck" 0 "Standby" ;
VAL_ 602 PtcHtrRun_B_Rq 1 "On" 0 "Off" ;
VAL_ 602 PwPckTqRdy_B_Dsply 1 "On" 0 "Off" ;
VAL_ 602 ObdEngStdy_B_Stat 1 "Yes" 0 "No" ;
VAL_ 602 BattTracRsrvSoc_Pc_Rq 16383 "Faulty" 16382 "NoDataExists" ;
VAL_ 602 EngStrtSrvc_B_Allw 1 "Yes" 0 "No" ;
VAL_ 587 BattTracClnt_Te_Actl 255 "Faulty" 254 "NoDataExists" ;
VAL_ 587 PwSrcULoMde_D_Actl 3 "BuckSpecial" 2 "ReverseBoost" 1 "ForwardBuck" 0 "Standby" ;
VAL_ 587 BattTracWarnLamp_B_Rq 1 "On" 0 "Off" ;
VAL_ 587 BattTracSrvcRqd_B_Rq 1 "On" 0 "Off" ;
VAL_ 1040 ElCmpr2Enbl_B_Rq 1 "Enable" 0 "Disable" ;
VAL_ 1040 BattTrac_I2_EstVsc 262143 "Faulty" 262142 "NoDataExists" ;
VAL_ 1040 ElCmprEnbl_B_Rq 1 "Enable" 0 "Disable" ;
VAL_ 1041 ElCmprPerfErr_D_Falt 3 "NotUsed" 2 "Pass" 1 "Fail" 0 "Not_Diagnose_Yet" ;
VAL_ 1041 ElCmprInnrErr_D_Falt 3 "NotUsed" 2 "Pass" 1 "Fail" 0 "Not_Diagnose_Yet" ;
VAL_ 1041 ElCmprLostComm_D_Falt 3 "NotUsed" 2 "Pass" 1 "Fail" 0 "Not_Diagnose_Yet" ;
VAL_ 1041 ElCmprOverLoad_D_Falt 3 "NotUsed" 2 "Pass" 1 "Fail" 0 "Not_Diagnose_Yet" ;
VAL_ 1041 ElCmprOverTe_D_Falt 3 "NotUsed" 2 "Pass" 1 "Fail" 0 "Not_Diagnose_Yet" ;
VAL_ 1041 ElCmprBattURng_D_Falt 3 "NotUsed" 2 "Pass" 1 "Fail" 0 "Not_Diagnose_Yet" ;
VAL_ 1041 ElCmprBattSysU_D_Falt 3 "NotUsed" 2 "Pass" 1 "Fail" 0 "Not_Diagnose_Yet" ;
VAL_ 1041 ElCmprSysU_D_Falt 3 "NotUsed" 2 "Pass" 1 "Fail" 0 "Not_Diagnose_Yet" ;
VAL_ 1041 ElCmprUHi_D_Stat 3 "Overvoltage" 2 "Undervoltage" 1 "InRange" 0 "Undetermined" ;
VAL_ 1041 ElCmprOverTe_D_Stat 3 "OverTempStop" 2 "OverTempWarning" 1 "Normal" 0 "Undefined" ;
VAL_ 1041 ElCmpr_N_Actl 255 "Invalid" ;
VAL_ 1041 ElCmpr_Pw_Actl 255 "Invalid" ;
VAL_ 1041 ElCmpr_D_Stat 7 "Signal_Invalid" 6 "Comp_Off_ActlSpd_Abnormal" 5 "Comp_Off_TrgtSpd_OutRange" 4 "Comp_Shutdown" 3 "Comp_Stopped_Self_Protect" 2 "Comp_Degraded" 1 "Comp_On" 0 "Comp_Off" ;
VAL_ 1088 TrlrRng_L_Dsply 8191 "Faulty" 8190 "NoDataExists" ;
VAL_ 1088 HvacPrecondRecirc_D_Rq 3 "Last_User_Setting" 2 "Auto" 1 "Recirc" 0 "Outside" ;
VAL_ 1088 HvacPrecondMode2_D_Rq 15 "NotUsed4" 14 "NotUsed3" 13 "NotUsed2" 12 "NotUsed1" 11 "Last_User_Settings" 10 "Auto" 9 "Max_Defrost" 8 "Windshield_Panel_Floor" 7 "Windshield_Panel" 6 "Windshield" 5 "Windshield_Floor" 4 "Floor" 3 "Panel_Floor" 2 "Panel" 1 "MAX_AC" 0 "Off" ;
VAL_ 1088 HvacPrecondBlwr2_D_Rq 15 "NotUsed6" 14 "NotUsed5" 13 "NotUsed4" 12 "NotUsed3" 11 "NotUsed2" 10 "NotUsed1" 9 "Last_User_Setting" 8 "Auto" 7 "Speed7" 6 "Speed6" 5 "Speed5" 4 "Speed4" 3 "Speed3" 2 "Speed2" 1 "Speed1" 0 "Off" ;
VAL_ 1088 HvacPrecondAC_D_Rq 3 "Last_User_Setting" 2 "Auto" 1 "On" 0 "Off" ;
VAL_ 1088 BattDcChrgRms_I_Lim 32767 "Faulty" 32766 "NoDataExists" ;
VAL_ 1088 BattChrgInhbt_D_Rq 3 "MaintainTargetSoc" 2 "NotUsed" 1 "InhibitChargingThermal" 0 "Enable_Charging" ;
VAL_ 1088 ChrgStat_D2_Dsply 15 "ChargeStopCommanded" 14 "ChargeStartCommanded" 13 "ChargeTargetReached" 12 "DriveConditioning" 11 "CabinPreconditioning" 10 "ChargingSystemMaintain" 9 "ChargingInductive" 8 "ChargingDCFastCharge" 7 "ChargingAC" 6 "ChargeScheduled" 5 "EvsePaused" 4 "EvseNotDetected" 3 "EvseNotCompatible" 2 "FaultOutsideCar" 1 "FaultInsideCar" 0 "NotReady" ;
VAL_ 1088 ChrgTMatch_B_Stat 1 "True" 0 "False" ;
VAL_ 871 BattElecPerf_D_Actl 7 "NotUsed" 6 "Hot_Batt_Severe_Lim_Perf" 5 "Hot_Batt_Reduced_Perf" 4 "Hot_Batt_Close_to_lim_Per" 3 "Cold_Batt_Severe_Lim_Perf" 2 "Cold_Batt_Reduced_Perf" 1 "Cold_Batt_Close_to_lim_Pe" 0 "Ok_no_message_displayed" ;
VAL_ 871 BattChrgTrgtLPt_T_Est 2047 "Faulty" 2046 "NoDataExists" ;
VAL_ 871 BattChrgTrgSocPt_T_Est 2047 "Faulty" 2046 "NoDataExists" ;
VAL_ 871 BattChrgCmpltPt_T_Est 2047 "Faulty" 2046 "NoDataExists" ;
VAL_ 871 DrvEffLvlIncDec_D_Cmd 3 "NotUsed" 2 "Decrease_Level_by_1" 1 "Increase_Level_by_1" 0 "Null_State" ;
VAL_ 869 PwrFlowTxt_D_Dsply 15 "NotUsed7" 14 "NotUsed6" 13 "NotUsed5" 12 "NotUsed4" 11 "Disply_Rgen_Chrg_Txt" 10 "Disp_Fast_Charge_Txt" 9 "Disp_Fast_Charge_Cmplt_Txt" 8 "Disp_Charge_Cmplt_Txt" 7 "Disp_Remote_Start_Txt" 6 "Disp_Eng_Drv_Txt" 5 "Disp_Elec_Drv_Txt" 4 "Disp_Idle_with_Chrg_Txt" 3 "Disp_Idle_Txt" 2 "Disp_Charg_HV_Batt_Txt" 1 "Disp_Hyb_Drive_Txt" 0 "No_Text" ;
VAL_ 869 EngOnMsg2_D_Dsply 14 "_0xE_to_1F_NotUsed" 12 "Battery_Temperature" 11 "Hill_Decent_Control" 10 "Fuel_Maintenance" 9 "Oil_Maintenance" 8 "Normal_Operation" 7 "Low_Gear" 6 "Batt_Charging" 5 "Engine_Cold" 4 "Neutral_Gear" 3 "Heater_Setting" 2 "High_Speed" 1 "Acceleration" 0 "No_Display" 13 "Drive_Mode_Selection" ;
VAL_ 869 EngOnMsg1_D_Dsply 14 "_0xE_to_1F_NotUsed" 12 "Battery_Temperature" 11 "Hill_Decent_Control" 10 "Fuel_Maintenance" 9 "Oil_Maintenance" 8 "Normal_Operation" 7 "Low_Gear" 6 "Batt_Charging" 5 "Engine_Cold" 4 "Neutral_Gear" 3 "Heater_Setting" 2 "High_Speed" 1 "Acceleration" 0 "No_Display" 13 "Drive_Mode_Selection" ;
VAL_ 869 FuelMaintMde_D_Dsply 3 "Feature_Not_Present" 2 "In_Fuel_Maint_Mode" 1 "Close_to_Fuel_Maint" 0 "OK" ;
VAL_ 869 RgenActv_B_Dsply 1 "On" 0 "Off" ;
VAL_ 869 EngOffTe_B_Dsply 1 "Eng_warm_engh_for_pd" 0 "Eng_not_warm_engh_for_pd" ;
VAL_ 869 EngActv_B_Dsply 1 "On" 0 "Off" ;
VAL_ 869 EffWhlThresOn_B_Dsply 1 "On" 0 "Off" ;
VAL_ 869 DchrgActv_B_Dsply 1 "On" 0 "Off" ;
VAL_ 869 ChrgActv_B_Dsply 1 "On" 0 "Off" ;
VAL_ 870 PolicePurstMde_B_Stat 1 "On" 0 "Off" ;
VAL_ 870 RngPerChrgInst_L_Dsply 4095 "Faulty" 4094 "NoDataExists" ;
VAL_ 870 ChkPlgtoStrt_D_Dsply 3 "NotUsed" 2 "Is_VehicleUnplugged_Prompt" 1 "Check_Plug_to_Start" 0 "No_Message_Display" ;
VAL_ 870 HybMdeLimMsgTxt_D_Rq 3 "Limited_Req_Full_Defrost" 2 "Limited_Climate_Defrost" 1 "Limited_System_Performance" 0 "Null" ;
VAL_ 870 HybMdeMsgTxt_D2_Rq 15 "NotUsed_4" 14 "NotUsed_3" 13 "NotUsed_2" 12 "NotUsed_1" 11 "EvOverride_Avail" 10 "EvLaterActv_EvAuto_NowAvai" 9 "EvNowActv_EvAuto_LaterAvai" 8 "EvAutoActv_EvNow_LaterAvai" 7 "EvAutoActv_NoOtherMdeAvail" 6 "EvChrgActv_EvAutoMdeAvail" 5 "EvAutoActv_EvChrgMdeAvail" 4 "EvChrgActv_AllPhevMdeAvail" 3 "EvLaterActv_AllPhevMdeAvai" 2 "EvNowActv_AllPhevMdeAvail" 1 "EvAutoActv_AllPhevMdeAvail" 0 "Null" ;
VAL_ 870 EngMdeMsgTxt_D_Rq 7 "NotUsed_3" 6 "NotUsed_2" 5 "NotUsed_1" 4 "Charge" 3 "GlowingCharge" 2 "Hybrid" 1 "Ev" 0 "NoMessage" ;
VAL_ 870 ShifOutNtrlMsgTxt_D_Rq 7 "Message7" 6 "Message6" 5 "Message5" 4 "Message4" 3 "Message3" 2 "Message2" 1 "Message1" 0 "NoMessage" ;
VAL_ 1071 EngMnfld3_P_Actl 255 "Faulty" 254 "NoDataExists" ;
VAL_ 1071 CluPdlPosPcMeas_D_Qf 3 "OK" 2 "Not_Within_Specifications" 1 "No_Data_Exists" 0 "Faulty" ;
VAL_ 130 TrlrHitchLamp_D_Rqst 1 "On" 0 "Off" ;
VAL_ 130 SteEffort_D_Stat 7 "NotUsed_3" 6 "NotUsed_2" 5 "NotUsed_1" 4 "SpecialMode_2" 3 "SpecialMode_1" 2 "Comfort" 1 "Sport" 0 "Normal" ;
VAL_ 130 SteMdule_D_Stat 7 "NotUsed" 6 "EPAS_Failure3" 5 "EPAS_Failure2" 4 "System_Failure" 3 "EPAS_Shutdown" 2 "Normal_Op_Full_Assist" 1 "Normal_Op_Limited_Assist" 0 "EPAS_Initialization" ;
VAL_ 130 DrvSteActv_B_Stat 1 "Active" 0 "Inactive" ;
VAL_ 130 DrvSte_Tq_Actl 255 "Invalid" 254 "Unknown" ;
VAL_ 130 VehVTrlrAid_B_Rq 1 "Request" 0 "NoRequest" ;
VAL_ 130 SteMdule_U_Meas 255 "Invalid" ;
VAL_ 130 SteMdule_I_Est 4095 "Invalid" ;
VAL_ 130 EPAS_Failure 3 "SERVICE_POWER_STEERING_NOW" 2 "SERVICE_POWER_STEERING" 1 "POWER_STRG_ASSIST_FAULT" 0 "EPAS_OK_NO_MESSAGE" ;
VAL_ 130 SteeringColumnTorque 255 "Invalid" 254 "Unknown" ;
VAL_ 130 SAPPAngleControlStat6 1 "RequestedAngleNotReached" 0 "RequestedAngleCanBeReached" ;
VAL_ 130 SAPPAngleControlStat5 1 "StrgColTorqueExceed_EAROn" 0 "ExternalSigContentOKforEAC" ;
VAL_ 130 SAPPAngleControlStat4 1 "SpeedLimitExceededEAROn" 0 "ExternalSigContentOKforEAC" ;
VAL_ 130 SAPPAngleControlStat3 1 "EARactiveNoReverseEngage" 0 "ExternalSigContentOKforEAC" ;
VAL_ 130 SAPPAngleControlStat2 1 "Rel_ExtSteeringAngleReqx" 0 "NoRel_ExtSteeringAngleReqx" ;
VAL_ 130 SAPPAngleControlStat1 3 "Fault" 2 "Active" 1 "Open" 0 "Closed" ;
VAL_ 1076 CenterStackRing_D_Actl 3 "LimitedOn" 2 "On" 1 "Off" 0 "Null" ;
VAL_ 1076 CenterStackRing_D_Actl_UB 1 "Fresh_data" 0 "Unchanged_data" ;
VAL_ 1076 EngIdlShutDown_B_RqDrv_UB 1 "Fresh_data" 0 "Unchanged_data" ;
VAL_ 1076 EngIdlShutDown_B_RqDrv 1 "Inhibit" 0 "No_Inibit" ;
VAL_ 1076 OdoTripRx_B_Actl 1 "Yes" 0 "No" ;
VAL_ 1076 LscmbbEngTqMn_B_Rq_UB 1 "Fresh_data" 0 "Unchanged_data" ;
VAL_ 1076 LscmbbEngTqMn_B_Rq 1 "Engine_Braking" 0 "No_Engine_Braking" ;
VAL_ 1076 TirePReset_B_Rq_UB 1 "Fresh_data" 0 "Unchanged_data" ;
VAL_ 1076 DrTGate_D_Rq 3 "NotUsed" 2 "Closing" 1 "Opening" 0 "Not_Moving" ;
VAL_ 1076 DrTGate_D_Rq_UB 1 "Fresh_data" 0 "Unchanged_data" ;
VAL_ 1076 FUEL_SENSOR_NUM 1 "Dual_Sensors" 0 "Single_Sensor" ;
VAL_ 1076 TirePReset_B_Rq 1 "Reset" 0 "Null" ;
VAL_ 1072 ePRNDL_MODE_UB 1 "Fresh_data" 0 "Unchanged_data" ;
VAL_ 1072 NtrlTowMdeEnbl_B_RqDrv 1 "Yes" 0 "No" ;
VAL_ 1072 NtrlTowMdeEnbl_B_RqDrv_UB 1 "Fresh_data" 0 "Unchanged_data" ;
VAL_ 1072 Remote_Start_QuietMode_UB 1 "Fresh_data" 0 "Unchanged_data" ;
VAL_ 1072 Remote_Start_QuietMode 1 "Quiet" 0 "Not_Quiet" ;
VAL_ 1072 ParkDetect_Stat_UB 1 "Fresh_data" 0 "Unchanged_data" ;
VAL_ 1072 ParkDetect_Stat 1 "Park" 0 "Not_Park" ;
VAL_ 1072 TrlrLampCnnct_B_Actl_UB 1 "Fresh_data" 0 "Unchanged_data" ;
VAL_ 1072 StopLamp_B_RqTrlrBrk_UB 1 "Fresh_data" 0 "Unchanged_data" ;
VAL_ 1072 StopLamp_B_RqTrlrBrk 1 "Yes" 0 "No" ;
VAL_ 1072 OdometerMasterValue_UB 1 "Fresh_data" 0 "Unchanged_data" ;
VAL_ 1072 OdometerMasterValue 16777215 "Invalid" ;
VAL_ 1072 FrostWarn_D_Stat 3 "NotUsed" 2 "On_Amber" 1 "On_Red" 0 "Off" ;
VAL_ 1072 ReducedGuard_D_Rq_UB 1 "Fresh_data" 0 "Unchanged_data" ;
VAL_ 1072 ReducedGuard_D_Rq 3 "NotUsed" 2 "On" 1 "Off" 0 "Null" ;
VAL_ 1072 ePRNDL_MODE 1 "On" 0 "Off" ;
VAL_ 1072 EngOilLife_B_RqReset 1 "Yes" 0 "No" ;
VAL_ 1072 Outside_Air_Temp_Stat_UB 1 "Fresh_data" 0 "Unchanged_data" ;
VAL_ 1072 Outside_Air_Temp_Stat 255 "Invalid" 254 "Unknown" ;
VAL_ 1072 KeyTypeChngMykey_D_Rq_UB 1 "Fresh_data" 0 "Unchanged_data" ;
VAL_ 1072 KeyTypeChngMykey_D_Rq 3 "Search_PE_BackupSlot" 2 "Clear_All_MyKeys" 1 "Request_New_MyKey" 0 "None" ;
VAL_ 1072 TrlrLampCnnct_B_Actl 1 "Yes" 0 "No" ;
VAL_ 1067 BattULoAux_U_Rq 4095 "Faulty" ;
VAL_ 1067 BattULoAuxIsol_D_Rq 3 "Undefined" 2 "Retain" 1 "Close" 0 "Open" ;
VAL_ 1067 BattULoAux_I_Actl 4095 "Faulty" ;
VAL_ 1067 BattULoAux_D_Qlty 3 "OK" 2 "Not_Within_Specifications" 1 "Eval_In_Progress" 0 "Faulty" ;
VAL_ 1067 BattULoAux_U_Actl 255 "Faulty" ;
VAL_ 1067 BattULoAux_B_Falt 1 "Fault" 0 "No_Fault" ;
VAL_ 588 HvacAirFlw_B_RqBatt 1 "Request" 0 "NoRequest" ;
VAL_ 588 BattChrgRdyStat_D_Actl 7 "NotUsed2" 6 "NotUsed1" 5 "Faulted" 4 "ChargeComplete" 3 "Charging" 2 "BatteryChargeReady" 1 "ChargeWait" 0 "NotReady" ;
VAL_ 588 BattTracSoc2_Pc_Actl 16383 "Faulty" 16382 "NoDataExists" ;
VAL_ 588 BattTracSoc_Pc_Dsply 255 "Faulty" 254 "NoDataExists" ;
VAL_ 588 BattTracCool_D_Falt 3 "NotUsed" 2 "CoolSysPartialyOperational" 1 "Cooling_System_Faulted" 0 "Cooling_System_Operational" ;
VAL_ 588 BattTracClntIn_Te_Actl 255 "Fault" ;
VAL_ 588 BattTrac_Te_Actl 1023 "Fault" 1022 "Unknown" ;
VAL_ 588 HvacRec_D_RqMxBatt 15 "NotUsed5" 14 "NotUsed4" 13 "NotUsed3" 12 "NotUsed2" 11 "NotUsed1" 10 "No_Override" 9 "90Percent_RecircMax" 8 "80Percent_RecircMax" 7 "70Percent_RecircMax" 6 "60Percent_RecircMax" 5 "50Percent_RecircMax" 4 "40Percent_RecircMax" 3 "30Percent_RecircMax" 2 "20Percent_RecircMax" 1 "10Percent_RecircMax" 0 "0Percent_RecircFullOpen" ;
VAL_ 588 HvacAir_Flw_EstBatt 255 "Invalid" ;
VAL_ 122 VehStrtInhbt_B_RqBatt 1 "Yes" 0 "No" ;
VAL_ 122 BattTracOffFst_D_Actl 3 "Unexpected_Contactor_Open" 2 "Restraints_Impact_Event" 1 "Interlock_Open" 0 "Normal" ;
VAL_ 122 BattTracOff_B_Actl 1 "Yes" 0 "No" ;
VAL_ 122 BattTracMil_D_Rq 3 "Not_Used" 2 "Flash" 1 "On" 0 "Off" ;
VAL_ 122 BattTracCnnct_B_Cmd 1 "Close" 0 "Open" ;
VAL_ 122 BattTrac_U_Actl 1023 "Fault" 1022 "Unknown" ;
VAL_ 122 BattTrac_I_Actl 32767 "Fault" 32766 "Unknown" ;
VAL_ 806 ClimtCoolRear_B_Rq 1 "On" 0 "Off" ;
VAL_ 806 ClimtHeatRear_D_Rq 7 "NotUsed4" 6 "NotUsed3" 5 "HtrCoreClntFlwOnly" 4 "PtcHtrTestMde" 3 "Defrost_Defog" 2 "FastTempPullDownHeatingReq" 1 "OpportunisticHeatingReq" 0 "NoHeatingRequest" ;
VAL_ 806 SnowPlowMde_B_Enbl 1 "Enable" 0 "Disable" ;
VAL_ 806 WndwFrontHeat_B_Stat 1 "On" 0 "Off" ;
VAL_ 806 StopStrtDrvMde_B_RqBtn 1 "Pressed" 0 "Not_Pressed" ;
VAL_ 806 HtrCorePump_B_Rq 1 "On" 0 "Off" ;
VAL_ 806 ClimtHeat_D_Rq 7 "NotUsed4" 6 "NotUsed3" 5 "HtrCoreClntFlwOnly" 4 "PtcHtrTestMde" 3 "Defrost_Defog" 2 "FastTempPullDownHeatingReq" 1 "OpportunisticHeatingReq" 0 "NoHeatingRequest" ;
VAL_ 806 ClimtCool_D_Rq 7 "NotUsed4" 6 "NotUsed3" 5 "NotUsed2" 4 "ElACTestMde" 3 "Defrost_Defog" 2 "FastTempPullDownCoolReq" 1 "OpportunisticCoolingReq" 0 "NoCoolingRequest" ;
VAL_ 806 HvacEvap_Te_Actl 1023 "Fault" ;
VAL_ 806 HvacAirCond_B_Rq 1 "Yes" 0 "No" ;
VAL_ 806 ClimtDeltaLoad_Pw_Actl 63 "Faulty" 62 "NoDataExists" ;
VAL_ 806 ClimtPw_B_Rq 1 "Yes" 0 "No" ;
VAL_ 578 PtLatchActv_B_RqBcm 1 "On" 0 "Off" ;
VAL_ 578 immoSecureIdleMode 3 "NotUsed2" 2 "NotUsed1" 1 "Active" 0 "Inactive" ;
VAL_ 578 ReFuelSwtchStat_D_Actl 3 "NotUsed2" 2 "NotUsed1" 1 "On" 0 "Off" ;
VAL_ 578 FuelPumpPwr_D_Stat 7 "NotUsed3" 6 "NotUsed2" 5 "NotUsed1" 4 "Power_Off_Default" 3 "Power_Off_Command" 2 "Power_Off_Service" 1 "Power_Off_Impact" 0 "Power_On" ;
VAL_ 578 BattULo_U_Actl 255 "Fault" ;
VAL_ 578 PrkLckCtl_B_Enbl 1 "Enable" 0 "Disable" ;
VAL_ 578 PrkLckCtlMsgTxt_D_Rq 3 "BTSI_DI_3" 2 "BTSI_DI_2" 1 "BTSI_DI_1" 0 "Null_BTSI_DI" ;
VAL_ 578 BrkTrnShifLck_B_Stat 1 "Shift" 0 "NoShift" ;
VAL_ 578 PrkLckCtlUnlck_D_Stat 3 "Trans_And_Steer_Unlckd" 2 "Steering_Unlckd" 1 "Transmission_Unlckd" 0 "Null" ;
VAL_ 578 PrkLckCtlTow_B_Enbl 1 "Enable" 0 "Disable" ;
VAL_ 578 DriverCrankingReq 1 "Crank_Request" 0 "No_Crank_Request" ;
VAL_ 578 EngOff_T_Actl 65535 "Invalid" ;
VAL_ 578 DcacElPw_D_Rq 3 "NotUsed" 2 "AC_HighPower_Requested" 1 "AC_LowPower_Requested" 0 "AC_Power_NotRequested" ;
VAL_ 578 BattULo_I_Actl 16383 "Fault" ;
VAL_ 514 StrtrMtrCtlMsgTxt_D2_Rq 3 "NoRequestPcmStartingMsgCtl" 2 "ShiftToNeutralToStart" 1 "ShiftToParkToStart" 0 "NoRequestBcmStartingMsgCtl" ;
VAL_ 514 StrtrMtrDlyStrt_B_Stat 1 "Yes" 0 "No" ;
VAL_ 514 VehVTrlrAid_B_Avail 1 "Yes" 0 "No" ;
VAL_ 514 StrtrMtrCtlMsgTxt_D_Rq 7 "Start_In_Gear_Allowed" 6 "Pending_Start_Cancelled" 5 "Start_Pending_Please_Wait" 4 "Cranking_Limit_Exceeded" 3 "Press_Brk_and_Shift_to_P_N" 2 "Press_Clutch_and_Brake" 1 "Press_Clutch_To_Start" 0 "No_Display" ;
VAL_ 514 VehVActlEng_D_Qf 3 "OK" 2 "Not_Within_Specifications" 1 "No_Data_Exists" 0 "Faulty" ;
VAL_ 514 GearRvrse_D_Actl 7 "Fault" 6 "NotUsed_3" 5 "NotUsed_2" 4 "NotUsed_1" 3 "Active_confirmed" 2 "Active_not_confirmed" 1 "Inactive_confirmed" 0 "Inactive_not_confirmed" ;
VAL_ 1057 FohEng_D_Rq 3 "AutoEnable_ParkEnable" 2 "AutoDisable_ParkEnable" 1 "AutoEnable_ParkDisable" 0 "Disable_Stop" ;
VAL_ 1057 EngIdlShutDwnTxt_D_Rq 3 "NotUsed" 2 "EngineShutdownOnPrevDrive" 1 "FeatureDisabledDueToFault" 0 "NoMessage" ;
VAL_ 1057 EngIdlShutDown_D_Stat 3 "Not_used" 2 "Engine_Shutdown" 1 "Initiated_Countdown" 0 "Normal_Operation" ;
VAL_ 1057 FUEL_ALCOHOL_PERCNT 255 "Invalid" ;
VAL_ 1057 TrnTotTq_Rt_Est 65535 "Fault" 65534 "Unknown" ;
VAL_ 1057 TrnTotLss_Tq_Est 255 "Fault" 254 "Unknown" ;
VAL_ 1057 ECMMILRequest 3 "Not_Used" 2 "Flash" 1 "On" 0 "Off" ;
VAL_ 1057 AirCondFluidHi_P_Actl 255 "Fault" 254 "Unknown" ;
VAL_ 1057 OilPressureWarning 1 "Low_Pressure_Lamp_On" 0 "Normal_Pressure_Lamp_Off" ;
VAL_ 1057 VehVLimStat_D_Actl 7 "Undefined_3" 6 "Undefined_2" 5 "Undefined_1" 4 "ASL_Fault_Condition" 3 "Active_and_Limiting" 2 "Active_but_Not_Limiting" 1 "Standby" 0 "Off" ;
VAL_ 1057 VehVLimActv_B_Actl 1 "Active" 0 "Inactive" ;
VAL_ 1057 CoolantFanStepAct 31 "Unused7" 30 "Unused6" 29 "Unused5" 28 "Unused4" 27 "Unused3" 26 "Unused2" 25 "Unused1" 23 "Step23" 22 "Step22" 21 "Step21" 20 "Step20" 19 "Step19" 18 "Step18" 17 "Step17" 16 "Step16" 15 "Step15" 14 "Step14" 13 "Step13" 12 "Step12" 11 "Step11" 10 "Step10" 9 "Step9" 8 "Step8" 7 "Step7" 6 "Step6" 5 "Step5" 4 "Step4" 3 "Step3" 2 "Step2" 1 "Step1" 24 "Max_Fan_Speed_Req" 0 "Fan_Cmd_Off" ;
VAL_ 1069 SlMde_D_Stat 3 "IsaNotConfigured" 2 "Manual_Mode" 1 "Auto_Mode" 0 "Null" ;
VAL_ 1069 SlMde_D_RqDsply 3 "NotUsed" 2 "ManualSpeed_LimiterSymbol" 1 "AutoSpeed_LimiterSymbol" 0 "NoSpeed_LimiterSymbol" ;
VAL_ 1069 IsaOffst_D_Stat 15 "Faulty" 14 "Null" 13 "Thirteen" 12 "Twelve" 11 "Eleven" 10 "Ten" 9 "Nine" 8 "Eight" 7 "Seven" 6 "Six" 5 "Five" 4 "Four" 3 "Three" 2 "Two" 1 "One" 0 "Zero" ;
VAL_ 1069 ReFuelSysStat_D_Dsply 7 "NotUsed3" 6 "NotUsed2" 5 "NotUsed1" 4 "Refuel_Err" 3 "Close_Fuel_Door" 2 "Refuel_Ready" 1 "Wait_To_Fuel" 0 "Null" ;
VAL_ 1069 ULoSrcOnPlg_B_Cmd 1 "Activate" 0 "Deactivate" ;
VAL_ 1069 EngOilMaint_B_Stat 1 "On" 0 "Off" ;
VAL_ 1069 GrllShtrPos_D_Cmd 15 "Fully_Open" 14 "Position14" 13 "Position13" 12 "Position12" 11 "Position11" 10 "Position10" 9 "Position9" 8 "Position8" 7 "Position7" 6 "Position6" 5 "Position5" 4 "Position4" 3 "Position3" 2 "Position2" 1 "Position1" 0 "Fully_Closed" ;
VAL_ 1069 GrllShtrPos_B_Falt 1 "Fault" 0 "No_Fault" ;
VAL_ 1069 ObdWarmUp_B_Complt 1 "Yes" 0 "No" ;
VAL_ 1069 EngMsgTxt_D_Rq 3 "Undefined_2" 2 "Undefined_1" 1 "Power_Reduced_to_LowerTemp" 0 "No_Message" ;
VAL_ 1069 EngAirIn_Te_Actl 1023 "Fault" 1022 "Unknown" ;
VAL_ 1069 TracKeyMdeEnbl_B_Stat 1 "On" 0 "Off" ;
VAL_ 878 PwBedPnlEnblScnd_B_Rq 1 "Enable" 0 "Disable" ;
VAL_ 878 DcacSysScnd_B_Falt 1 "Yes" 0 "No" ;
VAL_ 878 DcacOnScnd_B_Rq 1 "Enable" 0 "Disable" ;
VAL_ 878 DcacGfciTestScnd_B_Rq 1 "Pressed" 0 "Not_Pressed" ;
VAL_ 878 EngExhMdeHrStrt_D_Stat 31 "NotUsed_7" 30 "NotUsed_6" 29 "NotUsed_5" 28 "NotUsed_4" 27 "NotUsed_3" 26 "NotUsed_2" 25 "NotUsed_1" 24 "Hour23_11pm" 23 "Hour22_10pm" 22 "Hour21_9pm" 21 "Hour20_8pm" 20 "Hour19_7pm" 19 "Hour18_6pm" 18 "Hour17_5pm" 17 "Hour16_4pm" 16 "Hour15_3pm" 15 "Hour14_2pm" 14 "Hour13_1pm" 13 "Hour12_12pm" 12 "Hour11_11am" 11 "Hour10_10am" 10 "Hour9_9am" 9 "Hour8_8am" 8 "Hour7_7am" 7 "Hour6_6am" 6 "Hour5_5am" 5 "Hour4_4am" 4 "Hour3_3am" 3 "Hour2_2am" 2 "Hour1_1am" 1 "Hour0_12am" 0 "Null" ;
VAL_ 878 EngExhMdeHrEnd_D_Stat 31 "NotUsed_7" 30 "NotUsed_6" 29 "NotUsed_5" 28 "NotUsed_4" 27 "NotUsed_3" 26 "NotUsed_2" 25 "NotUsed_1" 24 "Hour23_11pm" 23 "Hour22_10pm" 22 "Hour21_9pm" 21 "Hour20_8pm" 20 "Hour19_7pm" 19 "Hour18_6pm" 18 "Hour17_5pm" 17 "Hour16_4pm" 16 "Hour15_3pm" 15 "Hour14_2pm" 14 "Hour13_1pm" 13 "Hour12_12pm" 12 "Hour11_11am" 11 "Hour10_10am" 10 "Hour9_9am" 9 "Hour8_8am" 8 "Hour7_7am" 7 "Hour6_6am" 6 "Hour5_5am" 5 "Hour4_4am" 4 "Hour3_3am" 3 "Hour2_2am" 2 "Hour1_1am" 1 "Hour0_12am" 0 "Null" ;
VAL_ 878 EngExhMdeHrEnbl_D_Stat 3 "NotUsed" 2 "Enabled" 1 "Disabled" 0 "Null" ;
VAL_ 878 DcacGfciTest_B_Rq 1 "Pressed" 0 "Not_Pressed" ;
VAL_ 878 DcacOut_Pw_DsplyMx 1023 "Faulty" ;
VAL_ 878 DcacOut1_Pw_Dsply 63 "Faulty" ;
VAL_ 878 DcacOut2_Pw_Dsply 63 "Faulty" ;
VAL_ 878 DcacHw_D_Confg 15 "NotUsed_11" 14 "NotUsed_10" 13 "NotUsed_9" 12 "NotUsed_8" 11 "NotUsed_7" 10 "NotUsed_6" 9 "NotUsed_5" 8 "NotUsed_4" 7 "NotUsed_3" 6 "NotUsed_2" 5 "NotUsed_1" 4 "Power_2300W" 3 "Power_7200W" 2 "Power_2400W" 1 "Power_2000W" 0 "NoDcacHardware" ;
VAL_ 878 DcacFaltMsgTxt_D_Rq 15 "HvacOn" 14 "OvercurrentLP" 13 "EngineRun" 12 "Service" 11 "NotAvailable" 10 "PlugWarn" 9 "PlugWarnDrive" 8 "BreakerC" 7 "BreakerB" 6 "BreakerA" 5 "FuelLow" 4 "AcOnOutput" 3 "Temperature" 2 "Gfci" 1 "Overcurrent" 0 "Ok" ;
VAL_ 878 DcacLoFuelMsgTxt_D_Rq 31 "Minute_31" 30 "Minute_30" 29 "Minute_29" 28 "Minute_28" 27 "Minute_27" 26 "Minute_26" 25 "Minute_25" 24 "Minute_24" 23 "Minute_23" 22 "Minute_22" 21 "Minute_21" 20 "Minute_20" 19 "Minute_19" 18 "Minute_18" 17 "Minute_17" 16 "Minute_16" 15 "Minute_15" 14 "Minute_14" 13 "Minute_13" 12 "Minute_12" 11 "Minute_11" 10 "Minute_10" 9 "Minute_9" 8 "Minute_8" 7 "Minute_7" 6 "Minute_6" 5 "Minute_5" 4 "Minute_4" 3 "Minute_3" 2 "Minute_2" 1 "Minute_1" 0 "Ok" ;
VAL_ 878 DcacEngOnMsgTxt_D_Rq 3 "NotUsed" 2 "DisplayQuestion" 1 "DisplayWarning" 0 "Ok" ;
VAL_ 878 DcacElPw_D_Stat 3 "NotUsed" 2 "High" 1 "Low" 0 "Off" ;
VAL_ 878 PwBedPnlEnbl_B_Rq 1 "Enable" 0 "Disable" ;
VAL_ 878 DcacOn_B_Rq 1 "Enable" 0 "Disable" ;
VAL_ 878 DcacSys_B_Falt 1 "Yes" 0 "No" ;
VAL_ 878 DcacLedCtl_D_Rq 3 "Fast_Flash" 2 "Slow_Flash" 1 "On" 0 "Off" ;
VAL_ 1200 BrkHold_D_Stat 7 "NotUsed_3" 6 "NotUsed_2" 5 "NotUsed_1" 4 "HeldSecondary" 3 "HeldSecure" 2 "Held" 1 "Inactive" 0 "Off" ;
VAL_ 1200 BrkRearPCorrltn_B_Stat 1 "Yes" 0 "No" ;
VAL_ 1200 HsaStat_D_Dsply 7 "NotUsed3" 6 "NotUsed2" 5 "NotUsed1" 4 "NotAvailable" 3 "SlowReleaseWithChime" 2 "SlowReleaseWithoutChime" 1 "Active" 0 "Inactive" ;
VAL_ 1200 HsaTrnAout_Tq_Rq 65535 "Fault" 65534 "Unknown" ;
VAL_ 1200 BrkBstrVac_P_Actl 127 "Invalid" ;
VAL_ 1200 YawStabilityIndex 511 "Fault" 510 "NoDataExists" ;
VAL_ 1200 BrkTot_Tq_RqDrv 8191 "Fault" ;
VAL_ 376 GasPrtc_D_RqDsply 7 "NotUsed_5" 6 "NotUsed_4" 5 "NotUsed_3" 4 "NotUsed_2" 3 "NotUsed_1" 2 "GpfOverLimit" 1 "GpfAtLimit" 0 "NormalOperation" ;
VAL_ 376 LnchCtlSys_D_Stat 7 "NotUsed3" 6 "NotUsed2" 5 "NotUsed1" 4 "On_LC_Unavailable_TC_On" 3 "On_LC_Unavailable" 2 "On_LC_Available" 1 "On_LC_Active" 0 "LC_OFF" ;
VAL_ 376 DynoMde_B_Cmd 1 "DynomometerMode" 0 "NormalOperation" ;
VAL_ 376 AslIconDsply_D_Rq 3 "On_Passive_Overridden" 2 "On_Active" 1 "On_Passive" 0 "Off" ;
VAL_ 376 AslChime_B_Rq 1 "Yes" 0 "No" ;
VAL_ 376 HvacHtrCore2_Te_Actl 1023 "Faulty" ;
VAL_ 376 PtcHtr_D_Cmd 3 "TurnOn" 2 "AutoMode" 1 "TurnOff" 0 "NoDecision_Initializing" ;
VAL_ 376 EcssLamp_D_RqDsply 3 "Not_Used" 2 "Flash" 1 "On" 0 "Off" ;
VAL_ 376 AirAmbTe_D_Qf 3 "OK" 2 "Not_Within_Specifications" 1 "No_Data_Exists" 0 "Faulty" ;
VAL_ 376 AirAmb_P_Actl 63 "Fault" 62 "NoDataExists" ;
